VERSION "0.0.1"

NS_ :

BS_:

BU_: TCU BRK ESP MCU RDD GP TMS GW KPD1 RDE FNR ECU KPD2 ATSGO ACU IMU1 IMU2 IMU3 IMU4 IMU5 AGW PMI HDOQS EGOQS OBC EEC CBSW EJRH EJLH EPDLT EPDL2 EPDLR EPDLA TRBDZ ECU1 CLST LC510 EGDL JS SMB KPAC ACCU Audio TGU RDRR RDLH RDRH AVM CHMSL CTC SMK MC3D EVC MCU2

BO_ 2566904865 MCU_CETI: 10 MCU
 SG_ SalesRegion : 72|8@1+ (1,0) [0|255] "" Vector__XXX
 SG_ TcuType : 68|4@1+ (1,0) [0|15] "" Vector__XXX
 SG_ JoyType : 64|4@1+ (1,0) [0|15] "" Vector__XXX
 SG_ McvCtrlType : 60|4@1+ (1,0) [0|15] "" Vector__XXX
 SG_ McvType : 56|4@1+ (1,0) [0|15] "" Vector__XXX
 SG_ PmpCtrlType : 52|4@1+ (1,0) [0|15] "" Vector__XXX
 SG_ PmpType : 48|4@1+ (1,0) [0|15] "" Vector__XXX
 SG_ EcuMaker : 44|4@1+ (1,0) [0|15] "" Vector__XXX
 SG_ EgMaker : 40|4@1+ (1,0) [0|15] "" Vector__XXX
 SG_ ModelYearVer : 36|4@1+ (1,0) [0|15] "" Vector__XXX
 SG_ MchType : 32|4@1+ (1,0) [0|15] "" Vector__XXX
 SG_ MchClass : 16|16@1+ (0.1,0) [0|6502.3] "" Vector__XXX
 SG_ MchGen : 8|8@1+ (1,0) [0|255] "" Vector__XXX
 SG_ EmsCtrl : 0|8@1+ (1,0) [0|255] "" Vector__XXX

BO_ 2566905121 MCU_ASDI: 178 MCU
 SG_ TwUseFlow4 : 1408|16@1+ (1,0) [0|65535] "" Vector__XXX
 SG_ TwUseFlow3 : 1392|16@1+ (1,0) [0|65535] "" Vector__XXX
 SG_ TwUseFlow2 : 1376|16@1+ (1,0) [0|65535] "" Vector__XXX
 SG_ TwUseFlow1 : 1360|16@1+ (1,0) [0|65535] "" Vector__XXX
 SG_ TwUseFlow0 : 1344|16@1+ (1,0) [0|65535] "" Vector__XXX
 SG_ TwSetFlow4 : 1328|16@1+ (1,0) [0|65535] "" Vector__XXX
 SG_ TwSetFlow3 : 1312|16@1+ (1,0) [0|65535] "" Vector__XXX
 SG_ TwSetFlow2 : 1296|16@1+ (1,0) [0|65535] "" Vector__XXX
 SG_ TwSetFlow1 : 1280|16@1+ (1,0) [0|65535] "" Vector__XXX
 SG_ TwSetFlow0 : 1264|16@1+ (1,0) [0|65535] "" Vector__XXX
 SG_ TwMinFlowAtt4 : 1248|16@1+ (1,0) [0|65535] "" Vector__XXX
 SG_ TwMinFlowAtt3 : 1232|16@1+ (1,0) [0|65535] "" Vector__XXX
 SG_ TwMinFlowAtt2 : 1216|16@1+ (1,0) [0|65535] "" Vector__XXX
 SG_ TwMinFlowAtt1 : 1200|16@1+ (1,0) [0|65535] "" Vector__XXX
 SG_ TwMinFlowAtt0 : 1184|16@1+ (1,0) [0|65535] "" Vector__XXX
 SG_ TwMaxFlowAtt4 : 1168|16@1+ (1,0) [0|65535] "" Vector__XXX
 SG_ TwMaxFlowAtt3 : 1152|16@1+ (1,0) [0|65535] "" Vector__XXX
 SG_ TwMaxFlowAtt2 : 1136|16@1+ (1,0) [0|65535] "" Vector__XXX
 SG_ TwMaxFlowAtt1 : 1120|16@1+ (1,0) [0|65535] "" Vector__XXX
 SG_ TwMaxFlowAtt0 : 1104|16@1+ (1,0) [0|65535] "" Vector__XXX
 SG_ TwMaxFlowPmp4 : 1088|16@1+ (1,0) [0|65535] "" Vector__XXX
 SG_ TwMaxFlowPmp3 : 1072|16@1+ (1,0) [0|65535] "" Vector__XXX
 SG_ TwMaxFlowPmp2 : 1056|16@1+ (1,0) [0|65535] "" Vector__XXX
 SG_ TwMaxFlowPmp1 : 1040|16@1+ (1,0) [0|65535] "" Vector__XXX
 SG_ TwMaxFlowPmp0 : 1024|16@1+ (1,0) [0|65535] "" Vector__XXX
 SG_ TwPrs4 : 1008|16@1+ (1,0) [0|65535] "" Vector__XXX
 SG_ TwPrs3 : 992|16@1+ (1,0) [0|65535] "" Vector__XXX
 SG_ TwPrs2 : 976|16@1+ (1,0) [0|65535] "" Vector__XXX
 SG_ TwPrs1 : 960|16@1+ (1,0) [0|65535] "" Vector__XXX
 SG_ TwPrs0 : 944|16@1+ (1,0) [0|65535] "" Vector__XXX
 SG_ TwRpm4 : 928|16@1+ (1,0) [0|65535] "" Vector__XXX
 SG_ TwRpm3 : 912|16@1+ (1,0) [0|65535] "" Vector__XXX
 SG_ TwRpm2 : 896|16@1+ (1,0) [0|65535] "" Vector__XXX
 SG_ TwRpm1 : 880|16@1+ (1,0) [0|65535] "" Vector__XXX
 SG_ TwRpm0 : 864|16@1+ (1,0) [0|65535] "" Vector__XXX
 SG_ Tw4BrkrBtnType : 853|2@1+ (1,0) [0|3] "" Vector__XXX
 SG_ Tw4TwoPmpOpt : 852|1@1+ (1,0) [0|1] "" Vector__XXX
 SG_ Tw4SelAttNo : 849|3@1+ (1,0) [0|7] "" Vector__XXX
 SG_ Tw4SelAttType : 848|1@1+ (1,0) [0|1] "" Vector__XXX
 SG_ Tw3BrkrBtnType : 837|2@1+ (1,0) [0|3] "" Vector__XXX
 SG_ Tw3TwoPmpOpt : 836|1@1+ (1,0) [0|1] "" Vector__XXX
 SG_ Tw3SelAttNo : 833|3@1+ (1,0) [0|7] "" Vector__XXX
 SG_ Tw3SelAttType : 832|1@1+ (1,0) [0|1] "" Vector__XXX
 SG_ Tw2BrkrBtnType : 821|2@1+ (1,0) [0|3] "" Vector__XXX
 SG_ Tw2TwoPmpOpt : 820|1@1+ (1,0) [0|1] "" Vector__XXX
 SG_ Tw2SelAttNo : 817|3@1+ (1,0) [0|7] "" Vector__XXX
 SG_ Tw2SelAttType : 816|1@1+ (1,0) [0|1] "" Vector__XXX
 SG_ Tw1BrkrBtnType : 805|2@1+ (1,0) [0|3] "" Vector__XXX
 SG_ Tw1TwoPmpOpt : 804|1@1+ (1,0) [0|1] "" Vector__XXX
 SG_ Tw1SelAttNo : 801|3@1+ (1,0) [0|7] "" Vector__XXX
 SG_ Tw1SelAttType : 800|1@1+ (1,0) [0|1] "" Vector__XXX
 SG_ Tw0BrkrBtnType : 789|2@1+ (1,0) [0|3] "" Vector__XXX
 SG_ Tw0TwoPmpOpt : 788|1@1+ (1,0) [0|1] "" Vector__XXX
 SG_ Tw0SelAttNo : 785|3@1+ (1,0) [0|7] "" Vector__XXX
 SG_ Tw0SelAttType : 784|1@1+ (1,0) [0|1] "" Vector__XXX
 SG_ OwUseFlow4 : 768|16@1+ (1,0) [0|65535] "" Vector__XXX
 SG_ OwUseFlow3 : 752|16@1+ (1,0) [0|65535] "" Vector__XXX
 SG_ OwUseFlow2 : 736|16@1+ (1,0) [0|65535] "" Vector__XXX
 SG_ OwUseFlow1 : 720|16@1+ (1,0) [0|65535] "" Vector__XXX
 SG_ OwUseFlow0 : 704|16@1+ (1,0) [0|65535] "" Vector__XXX
 SG_ OwSetFlow4 : 688|16@1+ (1,0) [0|65535] "" Vector__XXX
 SG_ OwSetFlow3 : 672|16@1+ (1,0) [0|65535] "" Vector__XXX
 SG_ OwSetFlow2 : 656|16@1+ (1,0) [0|65535] "" Vector__XXX
 SG_ OwSetFlow1 : 640|16@1+ (1,0) [0|65535] "" Vector__XXX
 SG_ OwSetFlow0 : 624|16@1+ (1,0) [0|65535] "" Vector__XXX
 SG_ OwMinFlowAtt4 : 608|16@1+ (1,0) [0|65535] "" Vector__XXX
 SG_ OwMinFlowAtt3 : 592|16@1+ (1,0) [0|65535] "" Vector__XXX
 SG_ OwMinFlowAtt2 : 576|16@1+ (1,0) [0|65535] "" Vector__XXX
 SG_ OwMinFlowAtt1 : 560|16@1+ (1,0) [0|65535] "" Vector__XXX
 SG_ OwMinFlowAtt0 : 544|16@1+ (1,0) [0|65535] "" Vector__XXX
 SG_ OwMaxFlowAtt4 : 528|16@1+ (1,0) [0|65535] "" Vector__XXX
 SG_ OwMaxFlowAtt3 : 512|16@1+ (1,0) [0|65535] "" Vector__XXX
 SG_ OwMaxFlowAtt2 : 496|16@1+ (1,0) [0|65535] "" Vector__XXX
 SG_ OwMaxFlowAtt1 : 480|16@1+ (1,0) [0|65535] "" Vector__XXX
 SG_ OwMaxFlowAtt0 : 464|16@1+ (1,0) [0|65535] "" Vector__XXX
 SG_ OwMaxFlowPmp4 : 448|16@1+ (1,0) [0|65535] "" Vector__XXX
 SG_ OwMaxFlowPmp3 : 432|16@1+ (1,0) [0|65535] "" Vector__XXX
 SG_ OwMaxFlowPmp2 : 416|16@1+ (1,0) [0|65535] "" Vector__XXX
 SG_ OwMaxFlowPmp1 : 400|16@1+ (1,0) [0|65535] "" Vector__XXX
 SG_ OwMaxFlowPmp0 : 384|16@1+ (1,0) [0|65535] "" Vector__XXX
 SG_ OwPrs4 : 368|16@1+ (1,0) [0|65535] "" Vector__XXX
 SG_ OwPrs3 : 352|16@1+ (1,0) [0|65535] "" Vector__XXX
 SG_ OwPrs2 : 336|16@1+ (1,0) [0|65535] "" Vector__XXX
 SG_ OwPrs1 : 320|16@1+ (1,0) [0|65535] "" Vector__XXX
 SG_ OwPrs0 : 304|16@1+ (1,0) [0|65535] "" Vector__XXX
 SG_ OwRpm4 : 288|16@1+ (1,0) [0|65535] "" Vector__XXX
 SG_ OwRpm3 : 272|16@1+ (1,0) [0|65535] "" Vector__XXX
 SG_ OwRpm2 : 256|16@1+ (1,0) [0|65535] "" Vector__XXX
 SG_ OwRpm1 : 240|16@1+ (1,0) [0|65535] "" Vector__XXX
 SG_ OwRpm0 : 224|16@1+ (1,0) [0|65535] "" Vector__XXX
 SG_ RttCurStep : 220|4@1+ (1,0) [0|15] "" Vector__XXX
 SG_ TwCurStep : 216|4@1+ (1,0) [0|15] "" Vector__XXX
 SG_ Ow4BrkrBtnType : 213|2@1+ (1,0) [0|3] "" Vector__XXX
 SG_ Ow4TwoPmpOpt : 212|1@1+ (1,0) [0|1] "" Vector__XXX
 SG_ Ow4SelAttNo : 209|3@1+ (1,0) [0|7] "" Vector__XXX
 SG_ Ow4SelAttType : 208|1@1+ (1,0) [0|1] "" Vector__XXX
 SG_ OwCurStep : 200|4@1+ (1,0) [0|15] "" Vector__XXX
 SG_ Ow3BrkrBtnType : 197|2@1+ (1,0) [0|3] "" Vector__XXX
 SG_ Ow3TwoPmpOpt : 196|1@1+ (1,0) [0|1] "" Vector__XXX
 SG_ Ow3SelAttNo : 193|3@1+ (1,0) [0|7] "" Vector__XXX
 SG_ Ow3SelAttType : 192|1@1+ (1,0) [0|1] "" Vector__XXX
 SG_ Ow2BrkrBtnType : 181|2@1+ (1,0) [0|3] "" Vector__XXX
 SG_ Ow2TwoPmpOpt : 180|1@1+ (1,0) [0|1] "" Vector__XXX
 SG_ Ow2SelAttNo : 177|3@1+ (1,0) [0|7] "" Vector__XXX
 SG_ Ow2SelAttType : 176|1@1+ (1,0) [0|1] "" Vector__XXX
 SG_ Ow1BrkrBtnType : 165|2@1+ (1,0) [0|3] "" Vector__XXX
 SG_ Ow1TwoPmpOpt : 164|1@1+ (1,0) [0|1] "" Vector__XXX
 SG_ Ow1SelAttNo : 161|3@1+ (1,0) [0|7] "" Vector__XXX
 SG_ Ow1SelAttType : 160|1@1+ (1,0) [0|1] "" Vector__XXX
 SG_ Ow0BrkrBtnType : 149|2@1+ (1,0) [0|3] "" Vector__XXX
 SG_ Ow0TwoPmpOpt : 148|1@1+ (1,0) [0|1] "" Vector__XXX
 SG_ Ow0SelAttNo : 145|3@1+ (1,0) [0|7] "" Vector__XXX
 SG_ Ow0SelAttType : 144|1@1+ (1,0) [0|1] "" Vector__XXX
 SG_ MaxFlow : 128|16@1+ (1,0) [0|65535] "" Vector__XXX
 SG_ MinFlow : 112|16@1+ (1,0) [0|65535] "" Vector__XXX
 SG_ MaxPrsTw : 96|16@1+ (1,0) [0|65535] "" Vector__XXX
 SG_ MinPrsTw : 80|16@1+ (1,0) [0|65535] "" Vector__XXX
 SG_ MaxPrsOw : 64|16@1+ (1,0) [0|65535] "" Vector__XXX
 SG_ MinPrsOw : 48|16@1+ (1,0) [0|65535] "" Vector__XXX
 SG_ MaxSpd : 32|16@1+ (1,0) [0|65535] "" Vector__XXX
 SG_ MinSpd : 16|16@1+ (1,0) [0|65535] "" Vector__XXX
 SG_ SelAttTw : 3|3@1+ (1,0) [0|7] "" Vector__XXX
 SG_ SelAttOw : 0|3@1+ (1,0) [0|7] "" Vector__XXX

BO_ 2566905377 MCU_FUDI: 32 MCU
 SG_ TrvlStd : 224|32@1+ (1,0) [0|4294967295] "" Vector__XXX
 SG_ TrvlPow : 192|32@1+ (1,0) [0|4294967295] "" Vector__XXX
 SG_ Idle : 160|32@1+ (1,0) [0|4294967295] "" Vector__XXX
 SG_ AutoIdle : 128|32@1+ (1,0) [0|4294967295] "" Vector__XXX
 SG_ EcnMd : 96|32@1+ (1,0) [0|4294967295] "" Vector__XXX
 SG_ StdMd : 64|32@1+ (1,0) [0|4294967295] "" Vector__XXX
 SG_ PowMd : 32|32@1+ (1,0) [0|4294967295] "" Vector__XXX
 SG_ PowPlusMd : 0|32@1+ (1,0) [0|4294967295] "" Vector__XXX

BO_ 2566905633 MCU_UHDI: 96 MCU
 SG_ TotOprHr : 736|32@1+ (1,0) [0|4294967295] "" Vector__XXX
 SG_ Co0lTempAbove106 : 704|32@1+ (1,0) [0|4294967295] "" Vector__XXX
 SG_ Co0lTemp96105 : 672|32@1+ (1,0) [0|4294967295] "" Vector__XXX
 SG_ Co0lTemp96100 : 640|32@1+ (1,0) [0|4294967295] "" Vector__XXX
 SG_ Co0lTemp9195 : 608|32@1+ (1,0) [0|4294967295] "" Vector__XXX
 SG_ Co0lTemp8190 : 576|32@1+ (1,0) [0|4294967295] "" Vector__XXX
 SG_ Co0lTempBelow80 : 544|32@1+ (1,0) [0|4294967295] "" Vector__XXX
 SG_ HydOilTmpAbove96 : 512|32@1+ (1,0) [0|4294967295] "" Vector__XXX
 SG_ HydOilTmp9195 : 480|32@1+ (1,0) [0|4294967295] "" Vector__XXX
 SG_ HydOilTmp8190 : 448|32@1+ (1,0) [0|4294967295] "" Vector__XXX
 SG_ HydOilTmp7180 : 416|32@1+ (1,0) [0|4294967295] "" Vector__XXX
 SG_ HydOilTmp5170 : 384|32@1+ (1,0) [0|4294967295] "" Vector__XXX
 SG_ HydOilTmpBelow50 : 352|32@1+ (1,0) [0|4294967295] "" Vector__XXX
 SG_ TwMd : 320|32@1+ (1,0) [0|4294967295] "" Vector__XXX
 SG_ BrkrMd : 288|32@1+ (1,0) [0|4294967295] "" Vector__XXX
 SG_ LiftMd : 256|32@1+ (1,0) [0|4294967295] "" Vector__XXX
 SG_ TrvlStd : 224|32@1+ (1,0) [0|4294967295] "" Vector__XXX
 SG_ TrvlPow : 192|32@1+ (1,0) [0|4294967295] "" Vector__XXX
 SG_ Idle : 160|32@1+ (1,0) [0|4294967295] "" Vector__XXX
 SG_ AutoIdle : 128|32@1+ (1,0) [0|4294967295] "" Vector__XXX
 SG_ EcnMd : 96|32@1+ (1,0) [0|4294967295] "" Vector__XXX
 SG_ StdMd : 64|32@1+ (1,0) [0|4294967295] "" Vector__XXX
 SG_ PowMd : 32|32@1+ (1,0) [0|4294967295] "" Vector__XXX
 SG_ PowPlusMd : 0|32@1+ (1,0) [0|4294967295] "" Vector__XXX

BO_ 2566905889 MCU_RTFI: 14 MCU
 SG_ Afc7 : 96|16@1+ (1,0) [0|65535] "" Vector__XXX
 SG_ Afc6 : 80|16@1+ (1,0) [0|65535] "" Vector__XXX
 SG_ Afc5 : 64|16@1+ (1,0) [0|65535] "" Vector__XXX
 SG_ Afc4 : 48|16@1+ (1,0) [0|65535] "" Vector__XXX
 SG_ Afc3 : 32|16@1+ (1,0) [0|65535] "" Vector__XXX
 SG_ Afc2 : 16|16@1+ (1,0) [0|65535] "" Vector__XXX
 SG_ Afc1 : 0|16@1+ (1,0) [0|65535] "" Vector__XXX

BO_ 2566906145 MCU_FLI: 14 MCU
 SG_ Hfc2FirstOcrTm : 80|32@1+ (1,0) [0|4294967295] "" Vector__XXX
 SG_ Hfc2 : 64|16@1+ (1,0) [0|65535] "" Vector__XXX
 SG_ Hfc2Cnt : 56|8@1+ (1,0) [0|255] "" Vector__XXX
 SG_ Hfc1FirstOcrTm : 24|32@1+ (1,0) [0|4294967295] "" Vector__XXX
 SG_ Hfc1 : 8|16@1+ (1,0) [0|65535] "" Vector__XXX
 SG_ Hfc1Cnt : 0|8@1+ (1,0) [0|255] "" Vector__XXX

BO_ 2566906401 MCU_ARTFI: 250 MCU

BO_ 2566906657 MCU_TPUC: 250 MCU
 SG_ TmsPunlckCode : 0|32@1+ (1,0) [0|4294967295] "" Vector__XXX

BO_ 2566907169 MCU_VSWVER: 250 MCU
 SG_ McuSwVerYear : 48|8@1+ (1,1985) [1985|2235] "year" Vector__XXX
 SG_ McuSwVerDay : 40|8@1+ (0.25,0) [0|62.5] "days" Vector__XXX
 SG_ McuSwVerMonth : 32|8@1+ (1,0) [0|250] "month" Vector__XXX
 SG_ McuSwVer : 0|32@1+ (1,0) [0|255] "" Vector__XXX

BO_ 2566907681 MCU_ECOGI: 15 MCU
 SG_ IccoFunCrcmdScore : 112|8@1+ (1,0) [0|250] "" Vector__XXX
 SG_ UnssHydReliefScore : 104|8@1+ (1,0) [0|250] "" Vector__XXX
 SG_ InIntentBrkPreventScore : 96|8@1+ (1,0) [0|250] "" Vector__XXX
 SG_ EmgStpPreventScore : 88|8@1+ (1,0) [0|250] "" Vector__XXX
 SG_ EgMdDnRcmdScore : 80|8@1+ (1,0) [0|250] "" Vector__XXX
 SG_ LckUpRcmdScore : 72|8@1+ (1,0) [0|250] "" Vector__XXX
 SG_ GrNeutRpmUpScore : 64|8@1+ (1,0) [0|250] "" Vector__XXX
 SG_ IdlePrvtScore : 56|8@1+ (1,0) [0|250] "" Vector__XXX
 SG_ ManGrMaxSpdRcmdScore : 48|8@1+ (1,0) [0|250] "" Vector__XXX
 SG_ Auto14RcmdScore : 40|8@1+ (1,0) [0|250] "" Vector__XXX
 SG_ LisVhcSpdSetDnChngRcmdScore : 32|8@1+ (1,0) [0|250] "" Vector__XXX
 SG_ LisVhcSpdSetUpChngRcmdScore : 24|8@1+ (1,0) [0|250] "" Vector__XXX
 SG_ LisFunCrcmdScore : 16|8@1+ (1,0) [0|250] "" Vector__XXX
 SG_ IccoFunCrctm : 5|1@1+ (1,0) [0|1] "" Vector__XXX
 SG_ EgMdDnRctm : 4|1@1+ (1,0) [0|1] "" Vector__XXX
 SG_ LckUpRcmd : 3|1@1+ (1,0) [0|1] "" Vector__XXX
 SG_ IdlePrvtRcmd : 2|1@1+ (1,0) [0|1] "" Vector__XXX
 SG_ Auto14Rcmd : 1|1@1+ (1,0) [0|1] "" Vector__XXX
 SG_ LisRcmd : 0|1@1+ (1,0) [0|1] "" Vector__XXX

BO_ 2566907937 MCU_MCI: 250 MCU
 SG_ ElecStrJoyThmbWhlConf : 16|2@1+ (1,0) [0|3] "" Vector__XXX
 SG_ Dl06EgFuelEffCalbConf : 14|2@1+ (1,0) [0|3] "" Vector__XXX
 SG_ RttThmbWhlDirConf : 12|2@1+ (1,0) [0|3] "" Vector__XXX
 SG_ TwThmbWhlDirConf : 10|2@1+ (1,0) [0|3] "" Vector__XXX
 SG_ CanPdlIntChngConf : 8|2@1+ (1,0) [0|3] "" Vector__XXX
 SG_ TrvlSwgAlmIntChngConf : 6|2@1+ (1,0) [0|3] "" Vector__XXX
 SG_ OprHrTmpIntChngConf : 4|2@1+ (1,0) [0|3] "" Vector__XXX
 SG_ QckCouplerIntChngConf : 2|2@1+ (1,0) [0|3] "" Vector__XXX
 SG_ ThmbWhlSensConf : 1|1@1+ (1,0) [0|1] "" Vector__XXX
 SG_ MultiFuncJoyBtnConf : 0|1@1+ (1,0) [0|1] "" Vector__XXX

BO_ 2566908449 MCU_MWIG: 250 MCU
 SG_ AssitSwgRh : 46|2@1+ (1,0) [0|3] "" Vector__XXX
 SG_ AssitSwgLh : 44|2@1+ (1,0) [0|3] "" Vector__XXX
 SG_ AssitBck : 42|2@1+ (1,0) [0|3] "" Vector__XXX
 SG_ AssitGrd : 40|2@1+ (1,0) [0|3] "" Vector__XXX
 SG_ SafeWrkSideFar : 36|2@1+ (1,0) [0|3] "" Vector__XXX
 SG_ SafeWrkSideMid : 34|2@1+ (1,0) [0|3] "" Vector__XXX
 SG_ SafeWrkSideNear : 32|2@1+ (1,0) [0|3] "" Vector__XXX
 SG_ SafeWrkFrFar : 28|2@1+ (1,0) [0|3] "" Vector__XXX
 SG_ SafeWrkFrMid : 26|2@1+ (1,0) [0|3] "" Vector__XXX
 SG_ SafeWrkFrNear : 24|2@1+ (1,0) [0|3] "" Vector__XXX
 SG_ FrMvGuidArmOut : 22|2@1+ (1,0) [0|3] "" Vector__XXX
 SG_ FrMvGuidArmIn : 20|2@1+ (1,0) [0|3] "" Vector__XXX
 SG_ FrMvGuidBoomDn : 18|2@1+ (1,0) [0|3] "" Vector__XXX
 SG_ FrMvGuidBoomUp : 16|2@1+ (1,0) [0|3] "" Vector__XXX
 SG_ EfenceTrkWrn : 14|2@1+ (1,0) [0|3] "" Vector__XXX
 SG_ EfenceDzWrn : 12|2@1+ (1,0) [0|3] "" Vector__XXX
 SG_ EfenceCabWrn : 10|2@1+ (1,0) [0|3] "" Vector__XXX
 SG_ EfenceFSwgRhWrn : 8|2@1+ (1,0) [0|3] "" Vector__XXX
 SG_ EfenceFSwgLhWrn : 6|2@1+ (1,0) [0|3] "" Vector__XXX
 SG_ EfenceCeilWrn : 4|2@1+ (1,0) [0|3] "" Vector__XXX
 SG_ EfenceFloorWrn : 2|2@1+ (1,0) [0|3] "" Vector__XXX
 SG_ EfenceWallWrn : 0|2@1+ (1,0) [0|3] "" Vector__XXX

BO_ 2566908705 MCU_TWG: 250 MCU
 SG_ TotWhgCurTrk : 40|16@1+ (2,0) [0|128510] "kg" Vector__XXX
 SG_ BckCntCurTrk : 24|16@1+ (1,0) [0|65535] "count" Vector__XXX
 SG_ WghCntSt : 20|2@1+ (1,0) [0|3] "" Vector__XXX
 SG_ WghSt : 16|4@1+ (1,0) [0|15] "" Vector__XXX
 SG_ RelTmBckWhg : 0|16@1+ (2,0) [0|128510] "kg" Vector__XXX

BO_ 2566908961 MCU_WCPR: 250 MCU
 SG_ BckZeroCalbStep : 20|4@1+ (1,0) [0|15] "" Vector__XXX
 SG_ BckZeroCalbStage : 16|4@1+ (1,0) [0|15] "" Vector__XXX
 SG_ FrMultiCalbStep : 12|4@1+ (1,0) [0|15] "" Vector__XXX
 SG_ FrMultiCalbStage : 8|4@1+ (1,0) [0|15] "" Vector__XXX
 SG_ FrSngCalbStep : 4|4@1+ (1,0) [0|15] "" Vector__XXX
 SG_ FrSngCalbStage : 0|4@1+ (1,0) [0|15] "" Vector__XXX

BO_ 2566909217 MCU_WCCV: 250 MCU
 SG_ TgtArmCylSpdUpLmt : 40|8@1+ (0.1,0) [0|20] "mm/sec" Vector__XXX
 SG_ TgtArmCylSpdLwLmt : 32|8@1+ (0.1,0) [0|20] "mm/sec" Vector__XXX
 SG_ CurArmCylSpd : 24|8@1+ (0.1,0) [0|20] "mm/sec" Vector__XXX
 SG_ TgtBoomCylSpdUpLmt : 16|8@1+ (0.1,0) [0|20] "mm/sec" Vector__XXX
 SG_ TgtBoomCylSpdLwLmt : 8|8@1+ (0.1,0) [0|20] "mm/sec" Vector__XXX
 SG_ CurBoomCylSpd : 0|8@1+ (0.1,0) [0|20] "mm/sec" Vector__XXX

BO_ 2566909473 MCU_WCJA: 250 MCU
 SG_ TgtArmJointAngEndPos : 40|8@1+ (1,-125) [-125|125] "deg" Vector__XXX
 SG_ TgtArmJointAngStartPos : 32|8@1+ (1,-125) [-125|125] "deg" Vector__XXX
 SG_ CurArmJointAng : 24|8@1+ (1,-125) [-125|125] "deg" Vector__XXX
 SG_ TgtBoomJointAngEndPos : 16|8@1+ (1,-125) [-125|125] "deg" Vector__XXX
 SG_ TgtBoomJointAngStartPos : 8|8@1+ (1,-125) [-125|125] "deg" Vector__XXX
 SG_ CurBoomJointAng : 0|8@1+ (1,-125) [-125|125] "deg" Vector__XXX

BO_ 2566909729 MCU_LADG: 250 MCU
 SG_ Reach : 48|16@1+ (1,-32000) [-32000|32255] "mm" Vector__XXX
 SG_ Hight : 32|16@1+ (1,-32000) [-32000|32255] "mm" Vector__XXX
 SG_ RatedLoad : 16|16@1+ (2,0) [0|128510] "kg" Vector__XXX
 SG_ ActLoad : 0|16@1+ (2,0) [0|128510] "kg" Vector__XXX

BO_ 2634018819 TCU_TCUID: 8 TCU

BO_ 2566910241 MCU_ASRG: 250 MCU
 SG_ SwgAng : 0|24@1+ (3.0517578125E-005,-250) [-250|252] "deg" Vector__XXX

BO_ 2566910534 EVC_ETCCMVCU: 9 EVC

BO_ 2566912289 MCU_MWHG4: 138 MCU
 SG_ SsOfsRttAng : 1088|16@1+ (0.0078125,-200) [-200|301.99] "deg" Vector__XXX
 SG_ ImuSsOfsTrttTiltAng : 1072|16@1+ (0.0078125,-200) [-200|301.99] "deg" Vector__XXX
 SG_ TrttBodyDmsnTQ4 : 1056|16@1+ (1,0) [0|64255] "mm" Vector__XXX
 SG_ TrttBodyDmsnDQ4 : 1040|16@1+ (1,0) [0|64255] "mm" Vector__XXX
 SG_ TrttBodyDmsnAngGdt : 1016|24@1+ (3.0517578125E-005,-250) [-250|252] "deg" Vector__XXX
 SG_ TrttBodyDmsnDT : 1000|16@1+ (1,0) [0|64255] "mm" Vector__XXX
 SG_ TrttBodyDmsnGT : 984|16@1+ (1,0) [0|64255] "mm" Vector__XXX
 SG_ TrttBodyDmsnDG : 968|16@1+ (1,0) [0|64255] "mm" Vector__XXX
 SG_ TrttBodyDmsnVW : 952|16@1+ (1,0) [0|64255] "mm" Vector__XXX
 SG_ TrttBodyDmsnUV : 936|16@1+ (1,0) [0|64255] "mm" Vector__XXX
 SG_ TrttBodyDmsnTU : 920|16@1+ (1,0) [0|64255] "mm" Vector__XXX
 SG_ TrttBck05DmsnAngVwn : 896|24@1+ (3.0517578125E-005,-250) [-250|252] "deg" Vector__XXX
 SG_ TrttBck05DmsnTN : 880|16@1+ (1,0) [0|64255] "mm" Vector__XXX
 SG_ TrttBck05DmsnWN : 864|16@1+ (1,0) [0|64255] "mm" Vector__XXX
 SG_ TrttBck05DmsnWT : 848|16@1+ (1,0) [0|64255] "mm" Vector__XXX
 SG_ TrttBck05DmsnNQ3 : 832|16@1+ (1,0) [0|64255] "mm" Vector__XXX
 SG_ TrttBck05DmsnWQ3 : 816|16@1+ (1,0) [0|64255] "mm" Vector__XXX
 SG_ TrttBck05DmsnNQ2 : 800|16@1+ (1,0) [0|64255] "mm" Vector__XXX
 SG_ TrttBck05DmsnWQ2 : 784|16@1+ (1,0) [0|64255] "mm" Vector__XXX
 SG_ TrttBck05DmsnWidth : 768|16@1+ (1,0) [0|64255] "mm" Vector__XXX
 SG_ TrttBck05DmsnNQ1 : 752|16@1+ (1,0) [0|64255] "mm" Vector__XXX
 SG_ TrttBck05DmsnWQ1 : 736|16@1+ (1,0) [0|64255] "mm" Vector__XXX
 SG_ TrttBck04DmsnAngVwn : 712|24@1+ (3.0517578125E-005,-250) [-250|252] "deg" Vector__XXX
 SG_ TrttBck04DmsnTN : 696|16@1+ (1,0) [0|64255] "mm" Vector__XXX
 SG_ TrttBck04DmsnWN : 680|16@1+ (1,0) [0|64255] "mm" Vector__XXX
 SG_ TrttBck04DmsnWT : 664|16@1+ (1,0) [0|64255] "mm" Vector__XXX
 SG_ TrttBck04DmsnNQ3 : 648|16@1+ (1,0) [0|64255] "mm" Vector__XXX
 SG_ TrttBck04DmsnWQ3 : 632|16@1+ (1,0) [0|64255] "mm" Vector__XXX
 SG_ TrttBck04DmsnNQ2 : 616|16@1+ (1,0) [0|64255] "mm" Vector__XXX
 SG_ TrttBck04DmsnWQ2 : 600|16@1+ (1,0) [0|64255] "mm" Vector__XXX
 SG_ TrttBck04DmsnWidth : 584|16@1+ (1,0) [0|64255] "mm" Vector__XXX
 SG_ TrttBck04DmsnNQ1 : 568|16@1+ (1,0) [0|64255] "mm" Vector__XXX
 SG_ TrttBck04DmsnWQ1 : 552|16@1+ (1,0) [0|64255] "mm" Vector__XXX
 SG_ TrttBck03DmsnAngVwn : 528|24@1+ (3.0517578125E-005,-250) [-250|252] "deg" Vector__XXX
 SG_ TrttBck03DmsnTN : 512|16@1+ (1,0) [0|64255] "mm" Vector__XXX
 SG_ TrttBck03DmsnWN : 496|16@1+ (1,0) [0|64255] "mm" Vector__XXX
 SG_ TrttBck03DmsnWT : 480|16@1+ (1,0) [0|64255] "mm" Vector__XXX
 SG_ TrttBck03DmsnNQ3 : 464|16@1+ (1,0) [0|64255] "mm" Vector__XXX
 SG_ TrttBck03DmsnWQ3 : 448|16@1+ (1,0) [0|64255] "mm" Vector__XXX
 SG_ TrttBck03DmsnNQ2 : 432|16@1+ (1,0) [0|64255] "mm" Vector__XXX
 SG_ TrttBck03DmsnWQ2 : 416|16@1+ (1,0) [0|64255] "mm" Vector__XXX
 SG_ TrttBck03DmsnWidth : 400|16@1+ (1,0) [0|64255] "mm" Vector__XXX
 SG_ TrttBck03DmsnNQ1 : 384|16@1+ (1,0) [0|64255] "mm" Vector__XXX
 SG_ TrttBck03DmsnWQ1 : 368|16@1+ (1,0) [0|64255] "mm" Vector__XXX
 SG_ TrttBck02DmsnAngVwn : 344|24@1+ (3.0517578125E-005,-250) [-250|252] "deg" Vector__XXX
 SG_ TrttBck02DmsnTN : 328|16@1+ (1,0) [0|64255] "mm" Vector__XXX
 SG_ TrttBck02DmsnWN : 312|16@1+ (1,0) [0|64255] "mm" Vector__XXX
 SG_ TrttBck02DmsnWT : 296|16@1+ (1,0) [0|64255] "mm" Vector__XXX
 SG_ TrttBck02DmsnNQ3 : 280|16@1+ (1,0) [0|64255] "mm" Vector__XXX
 SG_ TrttBck02DmsnWQ3 : 264|16@1+ (1,0) [0|64255] "mm" Vector__XXX
 SG_ TrttBck02DmsnNQ2 : 248|16@1+ (1,0) [0|64255] "mm" Vector__XXX
 SG_ TrttBck02DmsnWQ2 : 232|16@1+ (1,0) [0|64255] "mm" Vector__XXX
 SG_ TrttBck02DmsnWidth : 216|16@1+ (1,0) [0|64255] "mm" Vector__XXX
 SG_ TrttBck02DmsnNQ1 : 200|16@1+ (1,0) [0|64255] "mm" Vector__XXX
 SG_ TrttBck02DmsnWQ1 : 184|16@1+ (1,0) [0|64255] "mm" Vector__XXX
 SG_ TrttBck01DmsnAngVwn : 160|24@1+ (3.0517578125E-005,-250) [-250|252] "deg" Vector__XXX
 SG_ TrttBck01DmsnTN : 144|16@1+ (1,0) [0|64255] "mm" Vector__XXX
 SG_ TrttBck01DmsnWN : 128|16@1+ (1,0) [0|64255] "mm" Vector__XXX
 SG_ TrttBck01DmsnWT : 112|16@1+ (1,0) [0|64255] "mm" Vector__XXX
 SG_ TrttBck01DmsnNQ3 : 96|16@1+ (1,0) [0|64255] "mm" Vector__XXX
 SG_ TrttBck01DmsnWQ3 : 80|16@1+ (1,0) [0|64255] "mm" Vector__XXX
 SG_ TrttBck01DmsnNQ2 : 64|16@1+ (1,0) [0|64255] "mm" Vector__XXX
 SG_ TrttBck01DmsnWQ2 : 48|16@1+ (1,0) [0|64255] "mm" Vector__XXX
 SG_ TrttBck01DmsnWidth : 32|16@1+ (1,0) [0|64255] "mm" Vector__XXX
 SG_ TrttBck01DmsnNQ1 : 16|16@1+ (1,0) [0|64255] "mm" Vector__XXX
 SG_ TrttBck01DmsnWQ1 : 0|16@1+ (1,0) [0|64255] "mm" Vector__XXX

BO_ 2566912545 MCU_MWHG1: 125 MCU
 SG_ Bck05DmsnAngGdn : 976|24@1+ (3.0517578125E-005,-250) [-250|252] "deg" Vector__XXX
 SG_ Bck05DmsnDT : 960|16@1+ (1,0) [0|64255] "mm" Vector__XXX
 SG_ Bck05DmsnNQ3 : 944|16@1+ (1,0) [0|64255] "mm" Vector__XXX
 SG_ Bck05DmsnDQ3 : 928|16@1+ (1,0) [0|64255] "mm" Vector__XXX
 SG_ Bck05DmsnNQ2 : 912|16@1+ (1,0) [0|64255] "mm" Vector__XXX
 SG_ Bck05DmsnDQ2 : 896|16@1+ (1,0) [0|64255] "mm" Vector__XXX
 SG_ Bck05DmsnTN : 880|16@1+ (1,0) [0|64255] "mm" Vector__XXX
 SG_ Bck05DmsnWidth : 864|16@1+ (1,0) [0|64255] "mm" Vector__XXX
 SG_ Bck05DmsnNQ1 : 848|16@1+ (1,0) [0|64255] "mm" Vector__XXX
 SG_ Bck05DmsnDQ1 : 832|16@1+ (1,0) [0|64255] "mm" Vector__XXX
 SG_ Bck05DmsnDN : 816|16@1+ (1,0) [0|64255] "mm" Vector__XXX
 SG_ Bck05DmsnDG : 800|16@1+ (1,0) [0|64255] "mm" Vector__XXX
 SG_ Bck04DmsnAngGdn : 776|24@1+ (3.0517578125E-005,-250) [-250|252] "deg" Vector__XXX
 SG_ Bck04DmsnDT : 760|16@1+ (1,0) [0|64255] "mm" Vector__XXX
 SG_ Bck04DmsnNQ3 : 744|16@1+ (1,0) [0|64255] "mm" Vector__XXX
 SG_ Bck04DmsnDQ3 : 728|16@1+ (1,0) [0|64255] "mm" Vector__XXX
 SG_ Bck04DmsnNQ2 : 712|16@1+ (1,0) [0|64255] "mm" Vector__XXX
 SG_ Bck04DmsnDQ2 : 696|16@1+ (1,0) [0|64255] "mm" Vector__XXX
 SG_ Bck04DmsnTN : 680|16@1+ (1,0) [0|64255] "mm" Vector__XXX
 SG_ Bck04DmsnWidth : 664|16@1+ (1,0) [0|64255] "mm" Vector__XXX
 SG_ Bck04DmsnNQ1 : 648|16@1+ (1,0) [0|64255] "mm" Vector__XXX
 SG_ Bck04DmsnDQ1 : 632|16@1+ (1,0) [0|64255] "mm" Vector__XXX
 SG_ Bck04DmsnDN : 616|16@1+ (1,0) [0|64255] "mm" Vector__XXX
 SG_ Bck04DmsnDG : 600|16@1+ (1,0) [0|64255] "mm" Vector__XXX
 SG_ Bck03DmsnAngGdn : 576|24@1+ (3.0517578125E-005,-250) [-250|252] "deg" Vector__XXX
 SG_ Bck03DmsnDT : 560|16@1+ (1,0) [0|64255] "mm" Vector__XXX
 SG_ Bck03DmsnNQ3 : 544|16@1+ (1,0) [0|64255] "mm" Vector__XXX
 SG_ Bck03DmsnDQ3 : 528|16@1+ (1,0) [0|64255] "mm" Vector__XXX
 SG_ Bck03DmsnNQ2 : 512|16@1+ (1,0) [0|64255] "mm" Vector__XXX
 SG_ Bck03DmsnDQ2 : 496|16@1+ (1,0) [0|64255] "mm" Vector__XXX
 SG_ Bck03DmsnTN : 480|16@1+ (1,0) [0|64255] "mm" Vector__XXX
 SG_ Bck03DmsnWidth : 464|16@1+ (1,0) [0|64255] "mm" Vector__XXX
 SG_ Bck03DmsnNQ1 : 448|16@1+ (1,0) [0|64255] "mm" Vector__XXX
 SG_ Bck03DmsnDQ1 : 432|16@1+ (1,0) [0|64255] "mm" Vector__XXX
 SG_ Bck03DmsnDN : 416|16@1+ (1,0) [0|64255] "mm" Vector__XXX
 SG_ Bck03DmsnDG : 400|16@1+ (1,0) [0|64255] "mm" Vector__XXX
 SG_ Bck02DmsnAngGdn : 376|24@1+ (3.0517578125E-005,-250) [-250|252] "deg" Vector__XXX
 SG_ Bck02DmsnDT : 360|16@1+ (1,0) [0|64255] "mm" Vector__XXX
 SG_ Bck02DmsnNQ3 : 344|16@1+ (1,0) [0|64255] "mm" Vector__XXX
 SG_ Bck02DmsnDQ3 : 328|16@1+ (1,0) [0|64255] "mm" Vector__XXX
 SG_ Bck02DmsnNQ2 : 312|16@1+ (1,0) [0|64255] "mm" Vector__XXX
 SG_ Bck02DmsnDQ2 : 296|16@1+ (1,0) [0|64255] "mm" Vector__XXX
 SG_ Bck02DmsnTN : 280|16@1+ (1,0) [0|64255] "mm" Vector__XXX
 SG_ Bck02DmsnWidth : 264|16@1+ (1,0) [0|64255] "mm" Vector__XXX
 SG_ Bck02DmsnNQ1 : 248|16@1+ (1,0) [0|64255] "mm" Vector__XXX
 SG_ Bck02DmsnDQ1 : 232|16@1+ (1,0) [0|64255] "mm" Vector__XXX
 SG_ Bck02DmsnDN : 216|16@1+ (1,0) [0|64255] "mm" Vector__XXX
 SG_ Bck02DmsnDG : 200|16@1+ (1,0) [0|64255] "mm" Vector__XXX
 SG_ Bck01DmsnAngGdn : 176|24@1+ (3.0517578125E-005,-250) [-250|252] "deg" Vector__XXX
 SG_ Bck01DmsnDT : 160|16@1+ (1,0) [0|64255] "mm" Vector__XXX
 SG_ Bck01DmsnNQ3 : 144|16@1+ (1,0) [0|64255] "mm" Vector__XXX
 SG_ Bck01DmsnDQ3 : 128|16@1+ (1,0) [0|64255] "mm" Vector__XXX
 SG_ Bck01DmsnNQ2 : 112|16@1+ (1,0) [0|64255] "mm" Vector__XXX
 SG_ Bck01DmsnDQ2 : 96|16@1+ (1,0) [0|64255] "mm" Vector__XXX
 SG_ Bck01DmsnTN : 80|16@1+ (1,0) [0|64255] "mm" Vector__XXX
 SG_ Bck01DmsnWidth : 64|16@1+ (1,0) [0|64255] "mm" Vector__XXX
 SG_ Bck01DmsnNQ1 : 48|16@1+ (1,0) [0|64255] "mm" Vector__XXX
 SG_ Bck01DmsnDQ1 : 32|16@1+ (1,0) [0|64255] "mm" Vector__XXX
 SG_ Bck01DmsnDN : 16|16@1+ (1,0) [0|64255] "mm" Vector__XXX
 SG_ Bck01DmsnDG : 0|16@1+ (1,0) [0|64255] "mm" Vector__XXX

BO_ 2566912801 MCU_MWHG2: 110 MCU
 SG_ DacCoordinateSystem : 874|2@1+ (1,0) [0|3] "" Vector__XXX
 SG_ DacAutoMdSelect : 872|2@1+ (1,0) [0|3] "" Vector__XXX
 SG_ CrwTipCalbLen : 856|16@1+ (1,0) [0|64255] "mm" Vector__XXX
 SG_ ImuSsOfsBladeRoll : 832|24@1+ (3.0517578125E-005,-250) [-250|252] "deg" Vector__XXX
 SG_ ImuSsOfsBladePch : 808|24@1+ (3.0517578125E-005,-250) [-250|252] "deg" Vector__XXX
 SG_ ImuSsOfsCfrmRoll : 784|24@1+ (3.0517578125E-005,-250) [-250|252] "deg" Vector__XXX
 SG_ ImuSsOfsCfrmPch : 760|24@1+ (3.0517578125E-005,-250) [-250|252] "deg" Vector__XXX
 SG_ BladeTipCalbLen : 744|16@1+ (1,0) [0|64255] "mm" Vector__XXX
 SG_ BladeJointCalbLen : 728|16@1+ (1,0) [0|64255] "mm" Vector__XXX
 SG_ GrdAstPrfDsnDt01PntZ09 : 712|16@1+ (1,-32000) [-32000|32255] "mm" Vector__XXX
 SG_ GrdAstPrfDsnDt01PntY09 : 696|16@1+ (1,-32000) [-32000|32255] "mm" Vector__XXX
 SG_ GrdAstPrfDsnDt01PntZ08 : 680|16@1+ (1,-32000) [-32000|32255] "mm" Vector__XXX
 SG_ GrdAstPrfDsnDt01PntY08 : 664|16@1+ (1,-32000) [-32000|32255] "mm" Vector__XXX
 SG_ GrdAstPrfDsnDt01PntZ07 : 648|16@1+ (1,-32000) [-32000|32255] "mm" Vector__XXX
 SG_ GrdAstPrfDsnDt01PntY07 : 632|16@1+ (1,-32000) [-32000|32255] "mm" Vector__XXX
 SG_ GrdAstPrfDsnDt01PntZ06 : 616|16@1+ (1,-32000) [-32000|32255] "mm" Vector__XXX
 SG_ GrdAstPrfDsnDt01PntY06 : 600|16@1+ (1,-32000) [-32000|32255] "mm" Vector__XXX
 SG_ GrdAstPrfDsnDt01PntZ05 : 584|16@1+ (1,-32000) [-32000|32255] "mm" Vector__XXX
 SG_ GrdAstPrfDsnDt01PntY05 : 568|16@1+ (1,-32000) [-32000|32255] "mm" Vector__XXX
 SG_ GrdAstPrfDsnDt01PntZ04 : 552|16@1+ (1,-32000) [-32000|32255] "mm" Vector__XXX
 SG_ GrdAstPrfDsnDt01PntY04 : 536|16@1+ (1,-32000) [-32000|32255] "mm" Vector__XXX
 SG_ GrdAstPrfDsnDt01PntZ03 : 520|16@1+ (1,-32000) [-32000|32255] "mm" Vector__XXX
 SG_ GrdAstPrfDsnDt01PntY03 : 504|16@1+ (1,-32000) [-32000|32255] "mm" Vector__XXX
 SG_ GrdAstPrfDsnDt01PntZ02 : 488|16@1+ (1,-32000) [-32000|32255] "mm" Vector__XXX
 SG_ GrdAstPrfDsnDt01PntY02 : 472|16@1+ (1,-32000) [-32000|32255] "mm" Vector__XXX
 SG_ GrdAstPrfDsnDt01PntZ01 : 456|16@1+ (1,-32000) [-32000|32255] "mm" Vector__XXX
 SG_ GrdAstPrfDsnDt01PntY01 : 440|16@1+ (1,-32000) [-32000|32255] "mm" Vector__XXX
 SG_ CrossSlopeDsnDt : 424|16@1+ (0.0078125,-251) [-251|250.99] "%" Vector__XXX
 SG_ SlopeDsnDt : 408|16@1+ (0.0078125,-251) [-251|250.99] "%" Vector__XXX
 SG_ DepthDsnDt : 392|16@1+ (1,0) [0|64255] "mm" Vector__XXX
 SG_ JoyFuncAssnRhThmbWhl05 : 384|8@1+ (1,0) [0|255] "" Vector__XXX
 SG_ JoyFuncAssnRhThmbWhl04 : 376|8@1+ (1,0) [0|255] "" Vector__XXX
 SG_ JoyFuncAssnRhThmbWhl03 : 368|8@1+ (1,0) [0|255] "" Vector__XXX
 SG_ JoyFuncAssnRhThmbWhl02 : 360|8@1+ (1,0) [0|255] "" Vector__XXX
 SG_ JoyFuncAssnRhThmbWhl01 : 352|8@1+ (1,0) [0|255] "" Vector__XXX
 SG_ JoyFuncAssnLhThmbWhl05 : 344|8@1+ (1,0) [0|255] "" Vector__XXX
 SG_ JoyFuncAssnLhThmbWhl04 : 336|8@1+ (1,0) [0|255] "" Vector__XXX
 SG_ JoyFuncAssnLhThmbWhl03 : 328|8@1+ (1,0) [0|255] "" Vector__XXX
 SG_ JoyFuncAssnLhThmbWhl02 : 320|8@1+ (1,0) [0|255] "" Vector__XXX
 SG_ JoyFuncAssnLhThmbWhl01 : 312|8@1+ (1,0) [0|255] "" Vector__XXX
 SG_ JoyFuncAssnRhBtn10 : 304|8@1+ (1,0) [0|255] "" Vector__XXX
 SG_ JoyFuncAssnRhBtn09 : 296|8@1+ (1,0) [0|255] "" Vector__XXX
 SG_ JoyFuncAssnRhBtn08 : 288|8@1+ (1,0) [0|255] "" Vector__XXX
 SG_ JoyFuncAssnRhBtn07 : 280|8@1+ (1,0) [0|255] "" Vector__XXX
 SG_ JoyFuncAssnRhBtn06 : 272|8@1+ (1,0) [0|255] "" Vector__XXX
 SG_ JoyFuncAssnRhBtn05 : 264|8@1+ (1,0) [0|255] "" Vector__XXX
 SG_ JoyFuncAssnRhBtn04 : 256|8@1+ (1,0) [0|255] "" Vector__XXX
 SG_ JoyFuncAssnRhBtn03 : 248|8@1+ (1,0) [0|255] "" Vector__XXX
 SG_ JoyFuncAssnRhBtn02 : 240|8@1+ (1,0) [0|255] "" Vector__XXX
 SG_ JoyFuncAssnRhBtn01 : 232|8@1+ (1,0) [0|255] "" Vector__XXX
 SG_ JoyFuncAssnLhBtn10 : 224|8@1+ (1,0) [0|255] "" Vector__XXX
 SG_ JoyFuncAssnLhBtn09 : 216|8@1+ (1,0) [0|255] "" Vector__XXX
 SG_ JoyFuncAssnLhBtn08 : 208|8@1+ (1,0) [0|255] "" Vector__XXX
 SG_ JoyFuncAssnLhBtn07 : 200|8@1+ (1,0) [0|255] "" Vector__XXX
 SG_ JoyFuncAssnLhBtn06 : 192|8@1+ (1,0) [0|255] "" Vector__XXX
 SG_ JoyFuncAssnLhBtn05 : 184|8@1+ (1,0) [0|255] "" Vector__XXX
 SG_ JoyFuncAssnLhBtn04 : 176|8@1+ (1,0) [0|255] "" Vector__XXX
 SG_ JoyFuncAssnLhBtn03 : 168|8@1+ (1,0) [0|255] "" Vector__XXX
 SG_ JoyFuncAssnLhBtn02 : 160|8@1+ (1,0) [0|255] "" Vector__XXX
 SG_ JoyFuncAssnLhBtn01 : 152|8@1+ (1,0) [0|255] "" Vector__XXX
 SG_ ImuSsOfsBucket : 128|24@1+ (3.0517578125E-005,-250) [-250|252] "deg" Vector__XXX
 SG_ ImuSsOfsArtiArmPch : 104|24@1+ (3.0517578125E-005,-250) [-250|252] "deg" Vector__XXX
 SG_ ImuSsOfsArmPch : 80|24@1+ (3.0517578125E-005,-250) [-250|252] "deg" Vector__XXX
 SG_ ImuSsOfsBoomPch : 56|24@1+ (3.0517578125E-005,-250) [-250|252] "deg" Vector__XXX
 SG_ ImuSsOfsBodyRoll : 32|24@1+ (3.0517578125E-005,-250) [-250|252] "deg" Vector__XXX
 SG_ ImuSsOfsBodyPch : 8|24@1+ (3.0517578125E-005,-250) [-250|252] "deg" Vector__XXX
 SG_ SelectedBucketNo : 0|8@1+ (1,0) [0|255] "" Vector__XXX

BO_ 2566913057 MCU_MWHG3: 67 MCU
 SG_ MaterialName : 336|200@1+ (1,0) [0|255] "" Vector__XXX
 SG_ TrkName : 136|200@1+ (1,0) [0|255] "" Vector__XXX
 SG_ BchmkZOfs : 120|16@1+ (1,-32000) [-32000|32255] "mm" Vector__XXX
 SG_ BchmkYOfs : 104|16@1+ (1,-32000) [-32000|32255] "mm" Vector__XXX
 SG_ BchmkXOfs : 88|16@1+ (1,-32000) [-32000|32255] "mm" Vector__XXX
 SG_ TrkCount : 72|16@1+ (1,0) [0|64255] "" Vector__XXX
 SG_ SelMaterialDensity : 56|16@1+ (1,0) [0|64255] "kg/?" Vector__XXX
 SG_ SelTrkTgtWgh : 40|16@1+ (2,0) [0|128510] "kg" Vector__XXX
 SG_ BckRefPnt : 38|2@1+ (1,0) [0|3] "" Vector__XXX
 SG_ ArtiBoomDmsnOpt : 35|3@1+ (1,0) [0|7] "" Vector__XXX
 SG_ ArmDmsnOpt : 32|3@1+ (1,0) [0|7] "" Vector__XXX
 SG_ BoomDmsnOpt : 27|3@1+ (1,0) [0|7] "" Vector__XXX
 SG_ GrdAstMd : 20|4@1+ (1,0) [0|15] "" Vector__XXX
 SG_ GrdAstAccuracy : 16|4@1+ (1,0) [0|15] "" Vector__XXX
 SG_ TrkShoeWidth : 8|8@1+ (10,0) [0|2500] "mm" Vector__XXX

BO_ 2566913313 MCU_MWTSV: 18 MCU
 SG_ SwgAstAngTgtSetSwgLh : 120|24@1+ (3.0517578125E-005,-250) [-250|252] "deg" Vector__XXX
 SG_ SwgAstAngTgtSetSwgRh : 96|24@1+ (3.0517578125E-005,-250) [-250|252] "deg" Vector__XXX
 SG_ EfenceTgtSetSwgRh : 72|24@1+ (3.0517578125E-005,-250) [-250|252] "deg" Vector__XXX
 SG_ EfenceTgtSetSwgLh : 48|24@1+ (3.0517578125E-005,-250) [-250|252] "deg" Vector__XXX
 SG_ EfenceTgtSetCeil : 32|16@1+ (1,-32000) [-32000|32255] "mm" Vector__XXX
 SG_ EfenceTgtSetFloor : 16|16@1+ (1,-32000) [-32000|32255] "mm" Vector__XXX
 SG_ EfenceTgtSetWall : 0|16@1+ (1,-32000) [-32000|32255] "mm" Vector__XXX

BO_ 2566913569 MCU_MTSI: 57 MCU
 SG_ MaterialLoadSt : 448|1@1+ (1,0) [0|1] "" Vector__XXX
 SG_ TotWghCurtrk : 432|16@1+ (2,0) [0|128510] "kg" Vector__XXX
 SG_ BckCntCurtrk : 416|16@1+ (1,0) [0|65535] "count" Vector__XXX
 SG_ SelMaterialDensity : 400|16@1+ (1,0) [0|64255] "kg/?" Vector__XXX
 SG_ MaterialName : 200|200@1+ (1,0) [0|255] "" Vector__XXX
 SG_ TrkName : 0|200@1+ (1,0) [0|255] "" Vector__XXX

BO_ 2566913825 MCU_MAWI: 250 MCU
 SG_ TotAcmtWgh : 32|32@1+ (2,0) [0|8589934590] "kg" Vector__XXX
 SG_ TotAcmtBckCnt : 0|24@1+ (1,0) [0|16777215] "count" Vector__XXX

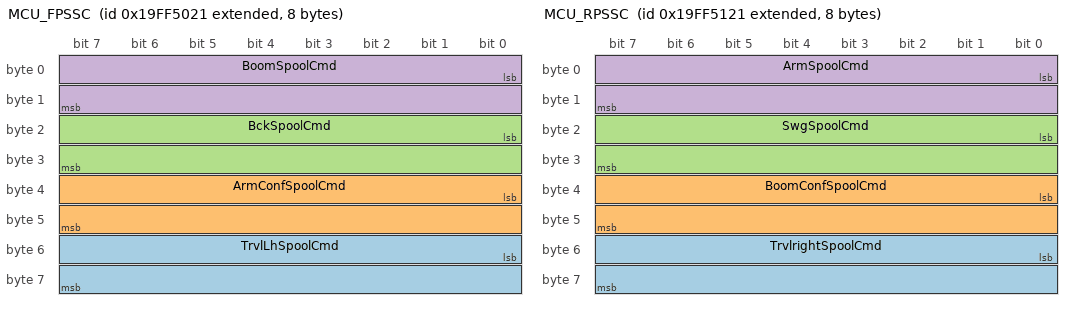
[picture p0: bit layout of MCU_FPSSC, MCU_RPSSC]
BO_ 2583646241 MCU_FPSSC: 8 MCU
 SG_ TrvlLhSpoolCmd : 48|16@1+ (0.01,-20) [-20|20] "mm" Vector__XXX
 SG_ ArmConfSpoolCmd : 32|16@1+ (0.01,-20) [-20|20] "mm" Vector__XXX
 SG_ BckSpoolCmd : 16|16@1+ (0.01,-20) [-20|20] "mm" Vector__XXX
 SG_ BoomSpoolCmd : 0|16@1+ (0.01,-20) [-20|20] "mm" Vector__XXX

BO_ 2583646497 MCU_RPSSC: 8 MCU
 SG_ TrvlrightSpoolCmd : 48|16@1+ (0.01,-20) [-20|20] "mm" Vector__XXX
 SG_ BoomConfSpoolCmd : 32|16@1+ (0.01,-20) [-20|20] "mm" Vector__XXX
 SG_ SwgSpoolCmd : 16|16@1+ (0.01,-20) [-20|20] "mm" Vector__XXX
 SG_ ArmSpoolCmd : 0|16@1+ (0.01,-20) [-20|20] "mm" Vector__XXX

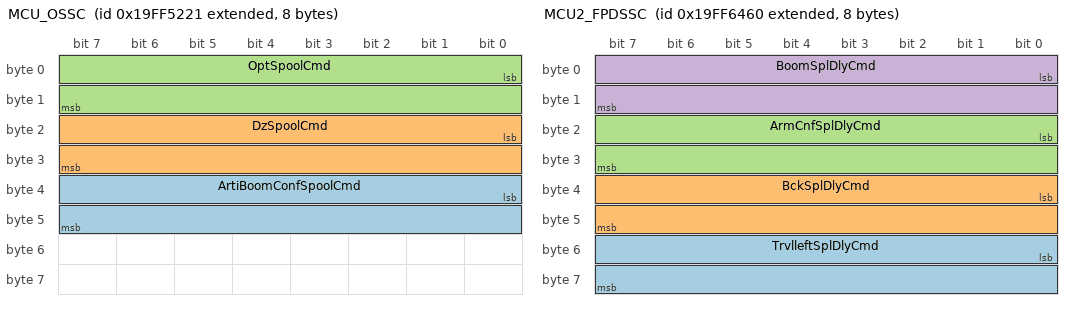
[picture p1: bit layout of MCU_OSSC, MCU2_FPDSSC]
BO_ 2583646753 MCU_OSSC: 8 MCU
 SG_ ArtiBoomConfSpoolCmd : 32|16@1+ (0.01,-20) [-20|20] "mm" Vector__XXX
 SG_ DzSpoolCmd : 16|16@1+ (0.01,-20) [-20|20] "mm" Vector__XXX
 SG_ OptSpoolCmd : 0|16@1+ (0.01,-20) [-20|20] "mm" Vector__XXX

BO_ 2583651424 MCU2_FPDSSC: 8 MCU2
 SG_ TrvlleftSplDlyCmd : 48|16@1+ (0.01,-20) [-20|20] "mm" Vector__XXX
 SG_ BckSplDlyCmd : 32|16@1+ (0.01,-20) [-20|20] "mm" Vector__XXX
 SG_ ArmCnfSplDlyCmd : 16|16@1+ (0.01,-20) [-20|20] "mm" Vector__XXX
 SG_ BoomSplDlyCmd : 0|16@1+ (0.01,-20) [-20|20] "mm" Vector__XXX

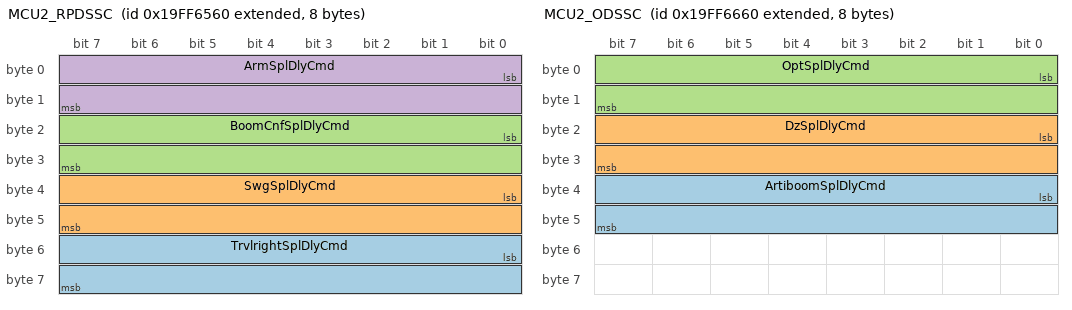
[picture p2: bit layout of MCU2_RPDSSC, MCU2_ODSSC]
BO_ 2583651680 MCU2_RPDSSC: 8 MCU2
 SG_ TrvlrightSplDlyCmd : 48|16@1+ (0.01,-20) [-20|20] "mm" Vector__XXX
 SG_ SwgSplDlyCmd : 32|16@1+ (0.01,-20) [-20|20] "mm" Vector__XXX
 SG_ BoomCnfSplDlyCmd : 16|16@1+ (0.01,-20) [-20|20] "mm" Vector__XXX
 SG_ ArmSplDlyCmd : 0|16@1+ (0.01,-20) [-20|20] "mm" Vector__XXX

BO_ 2583651936 MCU2_ODSSC: 8 MCU2
 SG_ ArtiboomSplDlyCmd : 32|16@1+ (0.01,-20) [-20|20] "mm" Vector__XXX
 SG_ DzSplDlyCmd : 16|16@1+ (0.01,-20) [-20|20] "mm" Vector__XXX
 SG_ OptSplDlyCmd : 0|16@1+ (0.01,-20) [-20|20] "mm" Vector__XXX

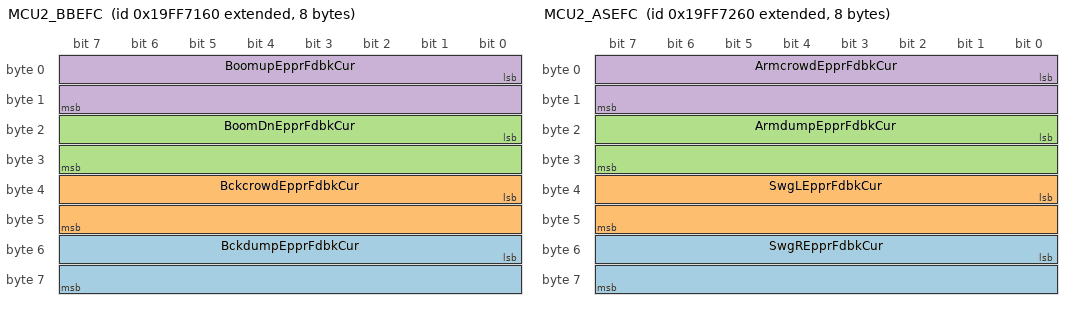
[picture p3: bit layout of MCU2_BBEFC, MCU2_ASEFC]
BO_ 2583654752 MCU2_BBEFC: 8 MCU2
 SG_ BckdumpEpprFdbkCur : 48|16@1+ (1,0) [0|1000] "mA" Vector__XXX
 SG_ BckcrowdEpprFdbkCur : 32|16@1+ (1,0) [0|1000] "mA" Vector__XXX
 SG_ BoomDnEpprFdbkCur : 16|16@1+ (1,0) [0|1000] "mA" Vector__XXX
 SG_ BoomupEpprFdbkCur : 0|16@1+ (1,0) [0|1000] "mA" Vector__XXX

BO_ 2583655008 MCU2_ASEFC: 8 MCU2
 SG_ SwgREpprFdbkCur : 48|16@1+ (1,0) [0|1000] "mA" Vector__XXX
 SG_ SwgLEpprFdbkCur : 32|16@1+ (1,0) [0|1000] "mA" Vector__XXX
 SG_ ArmdumpEpprFdbkCur : 16|16@1+ (1,0) [0|1000] "mA" Vector__XXX
 SG_ ArmcrowdEpprFdbkCur : 0|16@1+ (1,0) [0|1000] "mA" Vector__XXX

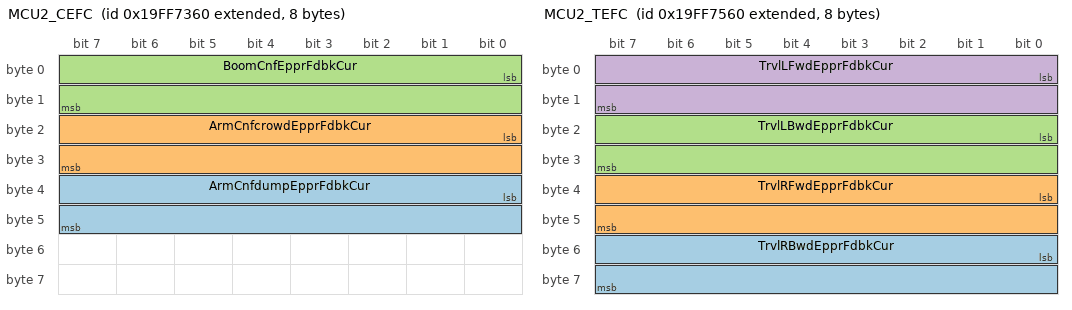
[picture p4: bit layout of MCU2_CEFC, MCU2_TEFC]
BO_ 2583655264 MCU2_CEFC: 8 MCU2
 SG_ ArmCnfdumpEpprFdbkCur : 32|16@1+ (1,0) [0|1000] "mA" Vector__XXX
 SG_ ArmCnfcrowdEpprFdbkCur : 16|16@1+ (1,0) [0|1000] "mA" Vector__XXX
 SG_ BoomCnfEpprFdbkCur : 0|16@1+ (1,0) [0|1000] "mA" Vector__XXX

BO_ 2583655520 MCU2_OEFC: 8 MCU2
 SG_ OpenEpprFdbkCur : 16|16@1+ (1,0) [0|1000] "mA" Vector__XXX
 SG_ CloseEpprFdbkCur : 0|16@1+ (1,0) [0|1000] "mA" Vector__XXX

BO_ 2583655776 MCU2_TEFC: 8 MCU2
 SG_ TrvlRBwdEpprFdbkCur : 48|16@1+ (1,0) [0|1000] "mA" Vector__XXX
 SG_ TrvlRFwdEpprFdbkCur : 32|16@1+ (1,0) [0|1000] "mA" Vector__XXX
 SG_ TrvlLBwdEpprFdbkCur : 16|16@1+ (1,0) [0|1000] "mA" Vector__XXX
 SG_ TrvlLFwdEpprFdbkCur : 0|16@1+ (1,0) [0|1000] "mA" Vector__XXX

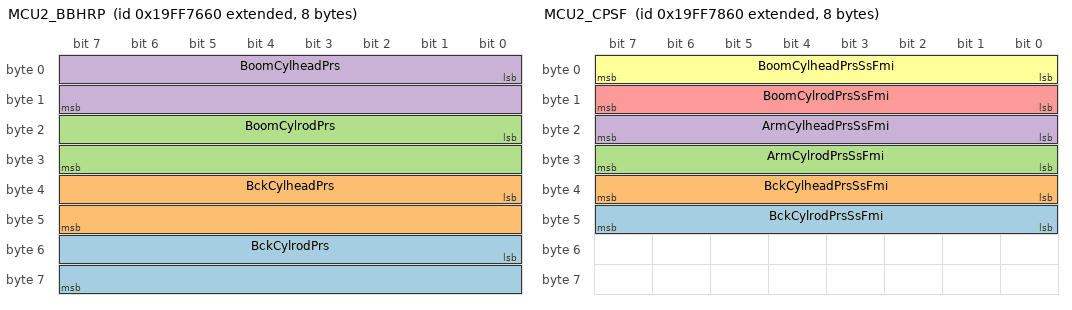
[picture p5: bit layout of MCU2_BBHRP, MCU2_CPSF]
BO_ 2583656032 MCU2_BBHRP: 8 MCU2
 SG_ BckCylrodPrs : 48|16@1+ (0.25,0) [0|500] "bar" Vector__XXX
 SG_ BckCylheadPrs : 32|16@1+ (0.25,0) [0|500] "bar" Vector__XXX
 SG_ BoomCylrodPrs : 16|16@1+ (0.25,0) [0|500] "bar" Vector__XXX
 SG_ BoomCylheadPrs : 0|16@1+ (0.25,0) [0|500] "bar" Vector__XXX

BO_ 2583656288 MCU2_AHRP: 8 MCU2
 SG_ ArmCylrodPrs : 16|16@1+ (0.25,0) [0|500] "bar" Vector__XXX
 SG_ ArmCylheadPrs : 0|16@1+ (0.25,0) [0|500] "bar" Vector__XXX

BO_ 2583656544 MCU2_CPSF: 8 MCU2
 SG_ BckCylrodPrsSsFmi : 40|8@1+ (1,0) [0|255] "" Vector__XXX
 SG_ BckCylheadPrsSsFmi : 32|8@1+ (1,0) [0|255] "" Vector__XXX
 SG_ ArmCylrodPrsSsFmi : 24|8@1+ (1,0) [0|255] "" Vector__XXX
 SG_ ArmCylheadPrsSsFmi : 16|8@1+ (1,0) [0|255] "" Vector__XXX
 SG_ BoomCylrodPrsSsFmi : 8|8@1+ (1,0) [0|255] "" Vector__XXX
 SG_ BoomCylheadPrsSsFmi : 0|8@1+ (1,0) [0|255] "" Vector__XXX

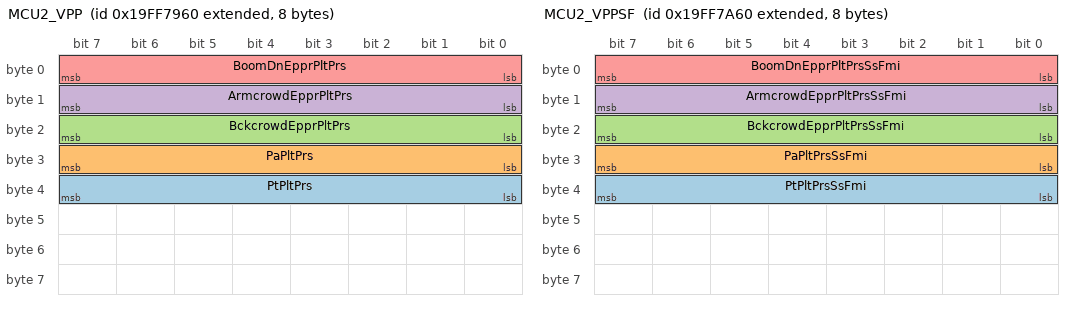
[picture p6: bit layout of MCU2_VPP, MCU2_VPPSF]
BO_ 2583656800 MCU2_VPP: 8 MCU2
 SG_ PtPltPrs : 32|8@1+ (0.25,0) [0|50] "bar" Vector__XXX
 SG_ PaPltPrs : 24|8@1+ (0.25,0) [0|50] "bar" Vector__XXX
 SG_ BckcrowdEpprPltPrs : 16|8@1+ (0.25,0) [0|50] "bar" Vector__XXX
 SG_ ArmcrowdEpprPltPrs : 8|8@1+ (0.25,0) [0|50] "bar" Vector__XXX
 SG_ BoomDnEpprPltPrs : 0|8@1+ (0.25,0) [0|50] "bar" Vector__XXX

BO_ 2583657056 MCU2_VPPSF: 8 MCU2
 SG_ PtPltPrsSsFmi : 32|8@1+ (1,0) [0|255] "" Vector__XXX
 SG_ PaPltPrsSsFmi : 24|8@1+ (1,0) [0|255] "" Vector__XXX
 SG_ BckcrowdEpprPltPrsSsFmi : 16|8@1+ (1,0) [0|255] "" Vector__XXX
 SG_ ArmcrowdEpprPltPrsSsFmi : 8|8@1+ (1,0) [0|255] "" Vector__XXX
 SG_ BoomDnEpprPltPrsSsFmi : 0|8@1+ (1,0) [0|255] "" Vector__XXX

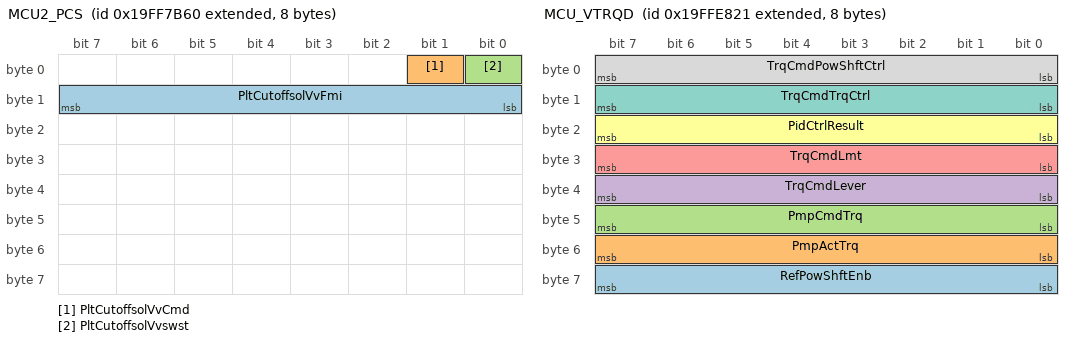
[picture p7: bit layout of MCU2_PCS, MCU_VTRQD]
BO_ 2583657312 MCU2_PCS: 8 MCU2
 SG_ PltCutoffsolVvFmi : 8|8@1+ (1,0) [0|255] "" Vector__XXX
 SG_ PltCutoffsolVvCmd : 1|1@1+ (1,0) [0|1] "" Vector__XXX
 SG_ PltCutoffsolVvswst : 0|1@1+ (1,0) [0|1] "" Vector__XXX

BO_ 2583667233 MCU_CBCC: 8 MCU

BO_ 2583683873 MCU_FJPP: 8 MCU

BO_ 2583684129 MCU_TJPP: 8 MCU

BO_ 2583684385 MCU_VFD: 8 MCU
 SG_ Qa2 : 50|10@1+ (10,0) [0|10230] "" Vector__XXX
 SG_ Qa1 : 40|10@1+ (10,0) [0|10230] "" Vector__XXX

BO_ 2583684641 MCU_VP1D: 8 MCU
 SG_ Pcmd1 : 0|12@1+ (0.25,0) [0|1023.75] "" Vector__XXX

BO_ 2583684897 MCU_VP2D: 8 MCU
 SG_ Pcmd2 : 0|12@1+ (0.25,0) [0|1023.75] "" Vector__XXX

BO_ 2583685153 MCU_VTRQD: 8 MCU
 SG_ RefPowShftEnb : 56|8@1+ (8,800) [800|2000] "Rpm" Vector__XXX
 SG_ PmpActTrq : 48|8@1+ (0.5,0) [0|127.5] "%" Vector__XXX
 SG_ PmpCmdTrq : 40|8@1+ (0.5,0) [0|127.5] "%" Vector__XXX
 SG_ TrqCmdLever : 32|8@1+ (0.5,0) [0|127.5] "%" Vector__XXX
 SG_ TrqCmdLmt : 24|8@1+ (0.5,0) [0|127.5] "%" Vector__XXX
 SG_ PidCtrlResult : 16|8@1+ (-0.5,0) [-125|125] "%" Vector__XXX
 SG_ TrqCmdTrqCtrl : 8|8@1+ (0.5,0) [0|127.5] "%" Vector__XXX
 SG_ TrqCmdPowShftCtrl : 0|8@1+ (0.5,0) [0|127.5] "%" Vector__XXX

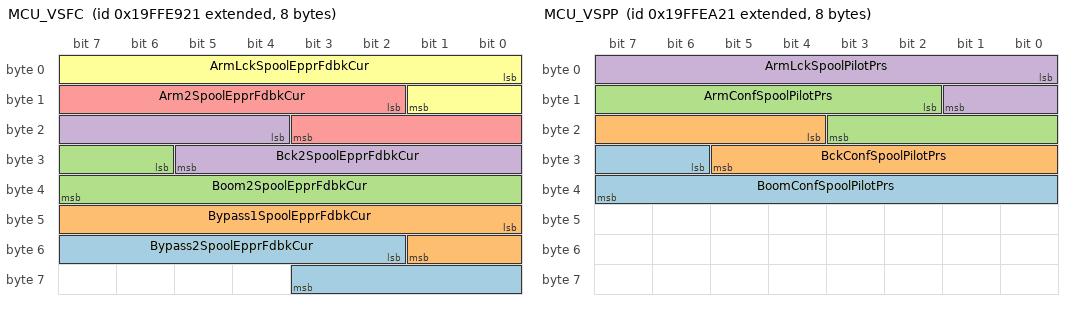
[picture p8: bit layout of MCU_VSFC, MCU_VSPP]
BO_ 2583685409 MCU_VSFC: 8 MCU
 SG_ Bypass2SpoolEpprFdbkCur : 50|10@1+ (1,0) [0|1000] "mA" Vector__XXX
 SG_ Bypass1SpoolEpprFdbkCur : 40|10@1+ (1,0) [0|1000] "mA" Vector__XXX
 SG_ Boom2SpoolEpprFdbkCur : 30|10@1+ (1,0) [0|1000] "mA" Vector__XXX
 SG_ Bck2SpoolEpprFdbkCur : 20|10@1+ (1,0) [0|1000] "mA" Vector__XXX
 SG_ Arm2SpoolEpprFdbkCur : 10|10@1+ (1,0) [0|1000] "mA" Vector__XXX
 SG_ ArmLckSpoolEpprFdbkCur : 0|10@1+ (1,0) [0|1000] "mA" Vector__XXX

BO_ 2583685665 MCU_VSPP: 8 MCU
 SG_ BoomConfSpoolPilotPrs : 30|10@1+ (0.0625,0) [0|50] "bar" Vector__XXX
 SG_ BckConfSpoolPilotPrs : 20|10@1+ (0.0625,0) [0|50] "bar" Vector__XXX
 SG_ ArmConfSpoolPilotPrs : 10|10@1+ (0.0625,0) [0|50] "bar" Vector__XXX
 SG_ ArmLckSpoolPilotPrs : 0|10@1+ (0.0625,0) [0|50] "bar" Vector__XXX

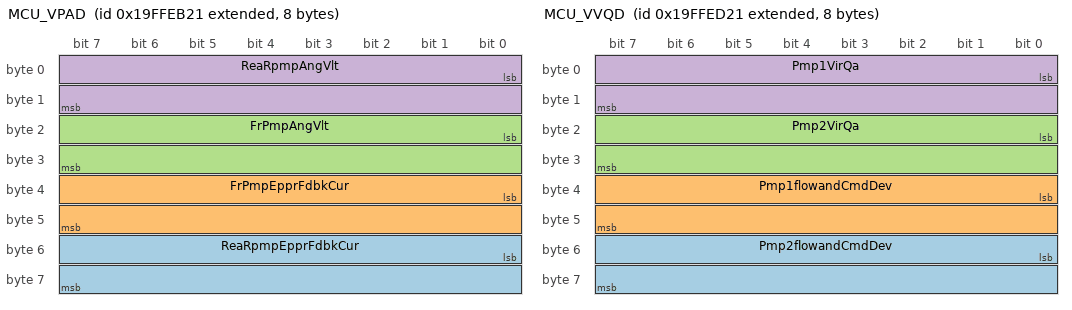
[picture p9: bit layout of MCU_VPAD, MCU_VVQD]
BO_ 2583685921 MCU_VPAD: 8 MCU
 SG_ ReaRpmpEpprFdbkCur : 48|16@1+ (1,0) [0|1000] "mA" Vector__XXX
 SG_ FrPmpEpprFdbkCur : 32|16@1+ (1,0) [0|1000] "mA" Vector__XXX
 SG_ FrPmpAngVlt : 16|16@1+ (1,0) [0|10000] "mV" Vector__XXX
 SG_ ReaRpmpAngVlt : 0|16@1+ (1,0) [0|10000] "mV" Vector__XXX

BO_ 2583686177 MCU_VTD: 8 MCU
 SG_ FrPmpAngVlt : 16|16@1+ (1,-40) [-40|250] "Celsius" Vector__XXX
 SG_ OilFanEpprFdbkCur : 0|16@1+ (1,0) [0|1000] "mA" Vector__XXX

BO_ 2583686433 MCU_VVQD: 8 MCU
 SG_ Pmp2flowandCmdDev : 48|16@1+ (1,0) [0|10000] "cc/sec" Vector__XXX
 SG_ Pmp1flowandCmdDev : 32|16@1+ (1,0) [0|10000] "cc/sec" Vector__XXX
 SG_ Pmp2VirQa : 16|16@1+ (1,0) [0|10000] "cc/sec" Vector__XXX
 SG_ Pmp1VirQa : 0|16@1+ (1,0) [0|10000] "cc/sec" Vector__XXX

BO_ 2382360307 AGW_TRADM2: 250 AGW

BO_ 2382360563 AGW_TRADM1: 250 AGW

BO_ 2382360819 AGW_TAIM1: 250 AGW

BO_ 2382361075 AGW_TRAIM1: 250 AGW

BO_ 2382361331 AGW_TRSIM1: 250 AGW

BO_ 2382361587 AGW_TRRSDM1: 250 AGW

BO_ 2382361843 AGW_TRTSDM1: 250 AGW

BO_ 2382362867 AGW_AFIM1: 250 AGW

BO_ 2382363123 AGW_ALCM1: 250 AGW

BO_ 2382363379 AGW_AHCM1: 250 AGW

BO_ 2382363681 MCU_EIM1: 250 MCU

BO_ 2382364193 MCU_ACM2: 250 MCU

BO_ 2382364449 MCU_ACM1: 250 MCU

BO_ 2566842442 TGU_VDS: 8 TGU
 SG_ Pitch : 32|16@1+ (0.0078125,-200) [-200|301.99] "deg" Vector__XXX
 SG_ Spd : 16|16@1+ (0.00390625,0) [0|250.996] "km/h" Vector__XXX

BO_ 2566845258 TGU_VP1: 8 TGU

BO_ 2583642954 TGU_DKLLG: 250 TGU
 SG_ Dkey : 8|48@1+ (1,0) [0|281474976710655] "" Vector__XXX
 SG_ SelType : 0|3@1+ (1,0) [0|7] "" Vector__XXX

BO_ 2583643210 TGU_DKLUG: 250 TGU
 SG_ DkeyList : 0|64@1+ (1,0) [0|255] "" Vector__XXX

BO_ 2583643466 TGU_DKTL: 250 TGU

BO_ 2583642186 TGU_MPS: 8 TGU
 SG_ TokenRevCnt : 2|8@1+ (1,0) [0|255] "" Vector__XXX
 SG_ MpSt : 0|2@1+ (1,0) [0|3] "" Vector__XXX

BO_ 2583642442 TGU_MPI: 101 TGU
 SG_ MpSt : 800|2@1+ (1,0) [0|3] "" Vector__XXX
 SG_ TguId : 640|160@1+ (1,0) [0|255] "ASCII" Vector__XXX
 SG_ Sname : 480|160@1+ (1,0) [0|255] "ASCII" Vector__XXX
 SG_ Pname : 400|80@1+ (1,0) [0|255] "ASCII" Vector__XXX
 SG_ Vin : 240|160@1+ (1,0) [0|255] "ASCII" Vector__XXX
 SG_ MchType : 208|32@1+ (1,0) [0|255] "ASCII" Vector__XXX
 SG_ Oem : 160|48@1+ (1,0) [0|255] "ASCII" Vector__XXX
 SG_ Mch : 0|160@1+ (1,0) [0|255] "ASCII" Vector__XXX

BO_ 2583642698 TGU_TCNI: 250 TGU
 SG_ NetNm : 8|56@1+ (1,0) [0|255] "ASCII" Vector__XXX
 SG_ Rssi : 5|3@1+ (1,0) [0|7] "" Vector__XXX
 SG_ Type : 2|3@1+ (1,0) [0|7] "" Vector__XXX
 SG_ Con : 0|2@1+ (1,0) [0|3] "" Vector__XXX

BO_ 2583642401 MCU_MPI: 101 MCU
 SG_ MpSt : 800|2@1+ (1,0) [0|3] "" Vector__XXX
 SG_ TguId : 640|160@1+ (1,0) [0|255] "ASCII" Vector__XXX
 SG_ Sname : 480|160@1+ (1,0) [0|255] "ASCII" Vector__XXX
 SG_ Pname : 400|80@1+ (1,0) [0|255] "ASCII" Vector__XXX
 SG_ Vin : 240|160@1+ (1,0) [0|255] "ASCII" Vector__XXX
 SG_ MchType : 208|32@1+ (1,0) [0|255] "ASCII" Vector__XXX
 SG_ Oem : 160|48@1+ (1,0) [0|255] "ASCII" Vector__XXX
 SG_ Mch : 0|160@1+ (1,0) [0|255] "ASCII" Vector__XXX

BO_ 2583662698 PHM_TGU_PHMWG: 8 TGU
 SG_ WarnPopEgOilQual : 3|3@1+ (1,0) [0|7] "" Vector__XXX
 SG_ WarnPopHyhOilQual : 0|3@1+ (1,0) [0|7] "" Vector__XXX

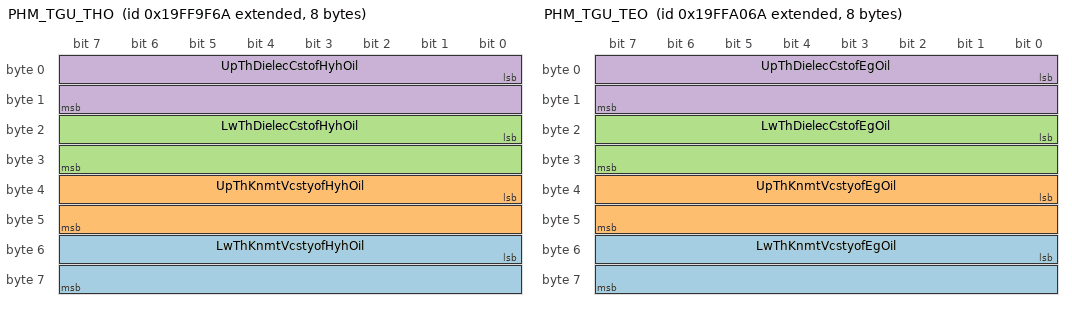
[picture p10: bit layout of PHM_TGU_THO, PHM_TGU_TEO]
BO_ 2583666538 PHM_TGU_THO: 8 TGU
 SG_ LwThKnmtVcstyofHyhOil : 48|16@1+ (0.00778149,0) [0|500] "" Vector__XXX
 SG_ UpThKnmtVcstyofHyhOil : 32|16@1+ (0.00778149,0) [0|500] "" Vector__XXX
 SG_ LwThDielecCstofHyhOil : 16|16@1+ (0.0001220703125,0) [0|7.844] "" Vector__XXX
 SG_ UpThDielecCstofHyhOil : 0|16@1+ (0.0001220703125,0) [0|7.844] "" Vector__XXX

BO_ 2583666794 PHM_TGU_TEO: 8 TGU
 SG_ LwThKnmtVcstyofEgOil : 48|16@1+ (0.00778149,0) [0|500] "" Vector__XXX
 SG_ UpThKnmtVcstyofEgOil : 32|16@1+ (0.00778149,0) [0|500] "" Vector__XXX
 SG_ LwThDielecCstofEgOil : 16|16@1+ (0.0001220703125,0) [0|7.844] "" Vector__XXX
 SG_ UpThDielecCstofEgOil : 0|16@1+ (0.0001220703125,0) [0|7.844] "" Vector__XXX

BO_ 2583667050 PHM_TGU_KVO: 8 TGU
 SG_ KnmtVcstyofEgOil : 16|16@1+ (0.00778149,0) [0|500] "" Vector__XXX
 SG_ KnmtVcstyofHyhOil : 0|16@1+ (0.00778149,0) [0|500] "" Vector__XXX

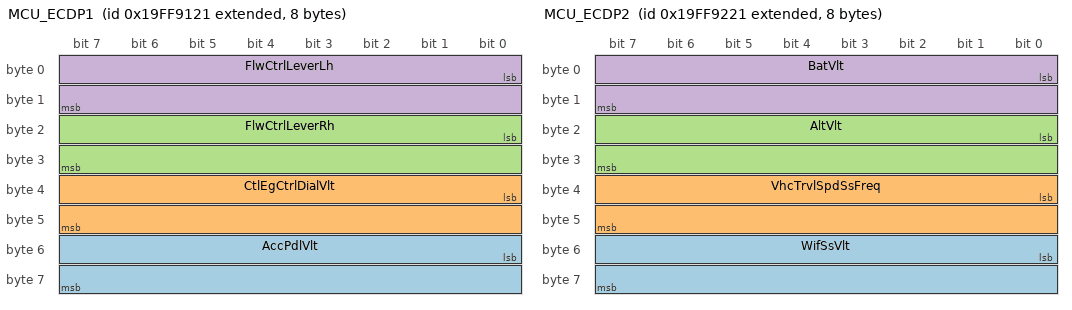
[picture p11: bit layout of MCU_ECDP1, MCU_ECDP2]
BO_ 2583662881 MCU_ECDP1: 8 MCU
 SG_ AccPdlVlt : 48|16@1+ (0.001,0) [0|64.255] "" Vector__XXX
 SG_ CtlEgCtrlDialVlt : 32|16@1+ (0.001,0) [0|64.255] "" Vector__XXX
 SG_ FlwCtrlLeverRh : 16|16@1+ (0.001,0) [0|64.255] "" Vector__XXX
 SG_ FlwCtrlLeverLh : 0|16@1+ (0.001,0) [0|64.255] "" Vector__XXX

BO_ 2583663137 MCU_ECDP2: 8 MCU
 SG_ WifSsVlt : 48|16@1+ (0.001,0) [0|64.255] "" Vector__XXX
 SG_ VhcTrvlSpdSsFreq : 32|16@1+ (1,0) [0|65000] "Hz" Vector__XXX
 SG_ AltVlt : 16|16@1+ (0.001,0) [0|64.255] "" Vector__XXX
 SG_ BatVlt : 0|16@1+ (0.001,0) [0|64.255] "" Vector__XXX

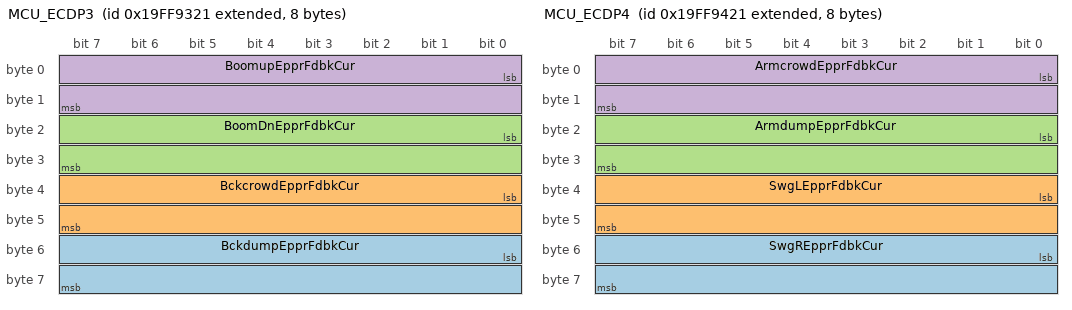
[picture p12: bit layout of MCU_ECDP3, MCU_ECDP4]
BO_ 2583663393 MCU_ECDP3: 8 MCU
 SG_ BckdumpEpprFdbkCur : 48|16@1+ (1,0) [0|1000] "mA" Vector__XXX
 SG_ BckcrowdEpprFdbkCur : 32|16@1+ (1,0) [0|1000] "mA" Vector__XXX
 SG_ BoomDnEpprFdbkCur : 16|16@1+ (1,0) [0|1000] "mA" Vector__XXX
 SG_ BoomupEpprFdbkCur : 0|16@1+ (1,0) [0|1000] "mA" Vector__XXX

BO_ 2583663649 MCU_ECDP4: 8 MCU
 SG_ SwgREpprFdbkCur : 48|16@1+ (1,0) [0|1000] "mA" Vector__XXX
 SG_ SwgLEpprFdbkCur : 32|16@1+ (1,0) [0|1000] "mA" Vector__XXX
 SG_ ArmdumpEpprFdbkCur : 16|16@1+ (1,0) [0|1000] "mA" Vector__XXX
 SG_ ArmcrowdEpprFdbkCur : 0|16@1+ (1,0) [0|1000] "mA" Vector__XXX

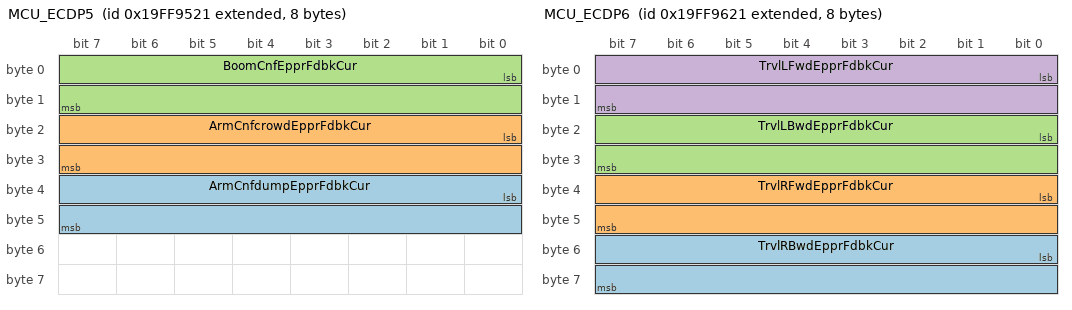
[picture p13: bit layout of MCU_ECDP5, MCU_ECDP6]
BO_ 2583663905 MCU_ECDP5: 8 MCU
 SG_ ArmCnfdumpEpprFdbkCur : 32|16@1+ (1,0) [0|1000] "mA" Vector__XXX
 SG_ ArmCnfcrowdEpprFdbkCur : 16|16@1+ (1,0) [0|1000] "mA" Vector__XXX
 SG_ BoomCnfEpprFdbkCur : 0|16@1+ (1,0) [0|1000] "mA" Vector__XXX

BO_ 2583664161 MCU_ECDP6: 8 MCU
 SG_ TrvlRBwdEpprFdbkCur : 48|16@1+ (1,0) [0|1000] "mA" Vector__XXX
 SG_ TrvlRFwdEpprFdbkCur : 32|16@1+ (1,0) [0|1000] "mA" Vector__XXX
 SG_ TrvlLBwdEpprFdbkCur : 16|16@1+ (1,0) [0|1000] "mA" Vector__XXX
 SG_ TrvlLFwdEpprFdbkCur : 0|16@1+ (1,0) [0|1000] "mA" Vector__XXX

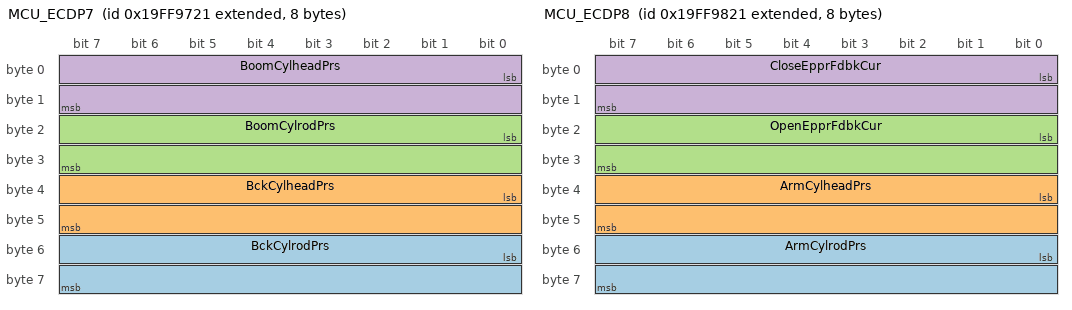
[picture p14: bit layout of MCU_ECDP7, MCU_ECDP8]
BO_ 2583664417 MCU_ECDP7: 8 MCU
 SG_ BckCylrodPrs : 48|16@1+ (0.25,0) [0|500] "bar" Vector__XXX
 SG_ BckCylheadPrs : 32|16@1+ (0.25,0) [0|500] "bar" Vector__XXX
 SG_ BoomCylrodPrs : 16|16@1+ (0.25,0) [0|500] "bar" Vector__XXX
 SG_ BoomCylheadPrs : 0|16@1+ (0.25,0) [0|500] "bar" Vector__XXX

BO_ 2583664673 MCU_ECDP8: 8 MCU
 SG_ ArmCylrodPrs : 48|16@1+ (0.25,0) [0|500] "bar" Vector__XXX
 SG_ ArmCylheadPrs : 32|16@1+ (0.25,0) [0|500] "bar" Vector__XXX
 SG_ OpenEpprFdbkCur : 16|16@1+ (1,0) [0|1000] "mA" Vector__XXX
 SG_ CloseEpprFdbkCur : 0|16@1+ (1,0) [0|1000] "mA" Vector__XXX

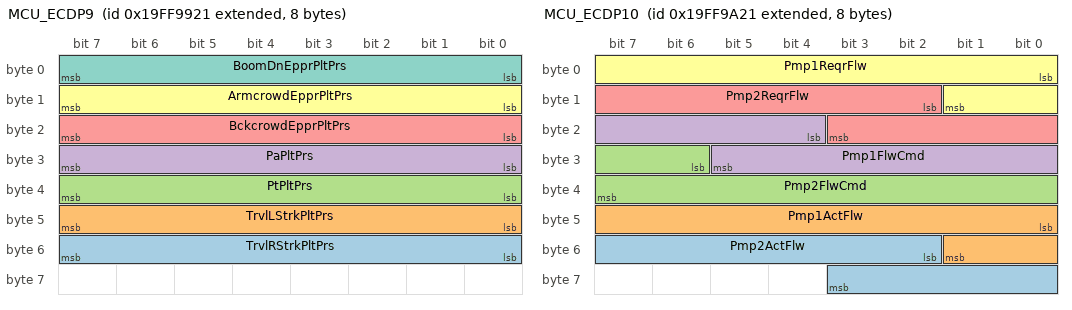
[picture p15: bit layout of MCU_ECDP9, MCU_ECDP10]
BO_ 2583664929 MCU_ECDP9: 8 MCU
 SG_ TrvlRStrkPltPrs : 48|8@1+ (0.25,0) [0|50] "bar" Vector__XXX
 SG_ TrvlLStrkPltPrs : 40|8@1+ (0.25,0) [0|50] "bar" Vector__XXX
 SG_ PtPltPrs : 32|8@1+ (0.25,0) [0|50] "bar" Vector__XXX
 SG_ PaPltPrs : 24|8@1+ (0.25,0) [0|50] "bar" Vector__XXX
 SG_ BckcrowdEpprPltPrs : 16|8@1+ (0.25,0) [0|50] "bar" Vector__XXX
 SG_ ArmcrowdEpprPltPrs : 8|8@1+ (0.25,0) [0|50] "bar" Vector__XXX
 SG_ BoomDnEpprPltPrs : 0|8@1+ (0.25,0) [0|50] "bar" Vector__XXX

BO_ 2583665185 MCU_ECDP10: 8 MCU
 SG_ Pmp2ActFlw : 50|10@1+ (10,0) [0|10000] "cc/sec" Vector__XXX
 SG_ Pmp1ActFlw : 40|10@1+ (10,0) [0|10000] "cc/sec" Vector__XXX
 SG_ Pmp2FlwCmd : 30|10@1+ (10,0) [0|10000] "cc/sec" Vector__XXX
 SG_ Pmp1FlwCmd : 20|10@1+ (10,0) [0|10000] "cc/sec" Vector__XXX
 SG_ Pmp2ReqrFlw : 10|10@1+ (10,0) [0|10000] "cc/sec" Vector__XXX
 SG_ Pmp1ReqrFlw : 0|10@1+ (10,0) [0|10000] "cc/sec" Vector__XXX

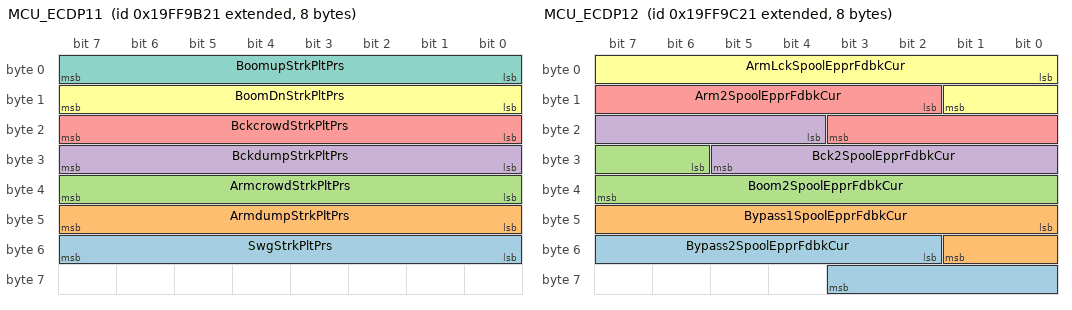
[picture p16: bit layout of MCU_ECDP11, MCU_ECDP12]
BO_ 2583665441 MCU_ECDP11: 8 MCU
 SG_ SwgStrkPltPrs : 48|8@1+ (0.25,0) [0|50] "bar" Vector__XXX
 SG_ ArmdumpStrkPltPrs : 40|8@1+ (0.25,0) [0|50] "bar" Vector__XXX
 SG_ ArmcrowdStrkPltPrs : 32|8@1+ (0.25,0) [0|50] "bar" Vector__XXX
 SG_ BckdumpStrkPltPrs : 24|8@1+ (0.25,0) [0|50] "bar" Vector__XXX
 SG_ BckcrowdStrkPltPrs : 16|8@1+ (0.25,0) [0|50] "bar" Vector__XXX
 SG_ BoomDnStrkPltPrs : 8|8@1+ (0.25,0) [0|50] "bar" Vector__XXX
 SG_ BoomupStrkPltPrs : 0|8@1+ (0.25,0) [0|50] "bar" Vector__XXX

BO_ 2583665697 MCU_ECDP12: 8 MCU
 SG_ Bypass2SpoolEpprFdbkCur : 50|10@1+ (1,0) [0|1000] "mA" Vector__XXX
 SG_ Bypass1SpoolEpprFdbkCur : 40|10@1+ (1,0) [0|1000] "mA" Vector__XXX
 SG_ Boom2SpoolEpprFdbkCur : 30|10@1+ (1,0) [0|1000] "mA" Vector__XXX
 SG_ Bck2SpoolEpprFdbkCur : 20|10@1+ (1,0) [0|1000] "mA" Vector__XXX
 SG_ Arm2SpoolEpprFdbkCur : 10|10@1+ (1,0) [0|1000] "mA" Vector__XXX
 SG_ ArmLckSpoolEpprFdbkCur : 0|10@1+ (1,0) [0|1000] "mA" Vector__XXX

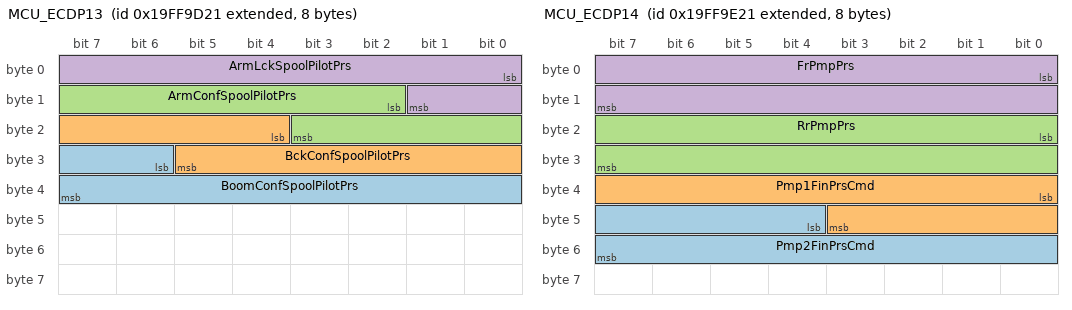
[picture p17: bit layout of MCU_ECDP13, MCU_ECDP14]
BO_ 2583665953 MCU_ECDP13: 8 MCU
 SG_ BoomConfSpoolPilotPrs : 30|10@1+ (0.0625,0) [0|50] "bar" Vector__XXX
 SG_ BckConfSpoolPilotPrs : 20|10@1+ (0.0625,0) [0|50] "bar" Vector__XXX
 SG_ ArmConfSpoolPilotPrs : 10|10@1+ (0.0625,0) [0|50] "bar" Vector__XXX
 SG_ ArmLckSpoolPilotPrs : 0|10@1+ (0.0625,0) [0|50] "bar" Vector__XXX

BO_ 2583666209 MCU_ECDP14: 8 MCU
 SG_ Pmp2FinPrsCmd : 44|12@1+ (0.25,0) [0|500] "bar" Vector__XXX
 SG_ Pmp1FinPrsCmd : 32|12@1+ (0.25,0) [0|500] "bar" Vector__XXX
 SG_ RrPmpPrs : 16|16@1+ (0.0625,0) [0|500] "bar" Vector__XXX
 SG_ FrPmpPrs : 0|16@1+ (0.0625,0) [0|500] "bar" Vector__XXX

BO_ 2633656127 HDOQS_OQM2: 8 HDOQS
 SG_ Oilresistivity : 0|32@1+ (1000,0) [0|4211081215000] "?" Vector__XXX

BO_ 2633656238 EGOQS_OQM2: 8 EGOQS
 SG_ Oilresistivity : 0|32@1+ (1000,0) [0|4211081215000] "?" Vector__XXX

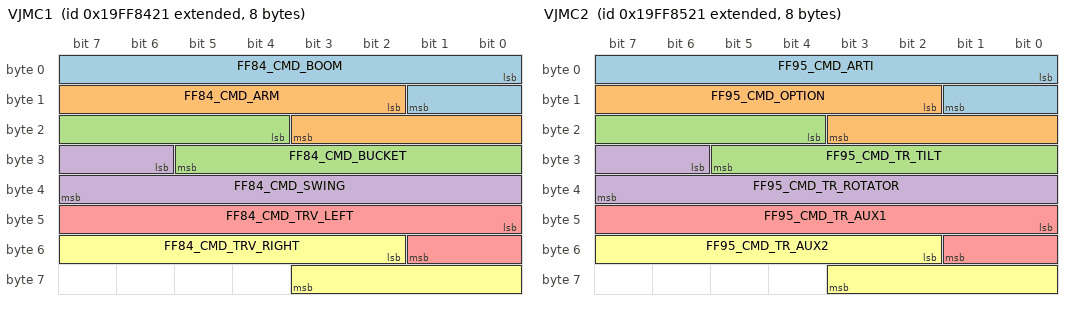
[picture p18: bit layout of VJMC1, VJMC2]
BO_ 2583659553 VJMC1: 8 Vector__XXX
 SG_ FF84_CMD_BOOM : 0|10@1+ (4,-1000) [-1000|3092] "" Vector__XXX
 SG_ FF84_CMD_ARM : 10|10@1+ (4,-1000) [-1000|3092] "" Vector__XXX
 SG_ FF84_CMD_BUCKET : 20|10@1+ (4,-1000) [-1000|3092] "" Vector__XXX
 SG_ FF84_CMD_SWING : 30|10@1+ (4,-1000) [-1000|3092] "" Vector__XXX
 SG_ FF84_CMD_TRV_LEFT : 40|10@1+ (4,-1000) [-1000|3092] "" Vector__XXX
 SG_ FF84_CMD_TRV_RIGHT : 50|10@1+ (4,-1000) [-1000|3092] "" Vector__XXX

BO_ 2583659809 VJMC2: 8 Vector__XXX
 SG_ FF95_CMD_ARTI : 0|10@1+ (4,-1000) [-1000|3092] "" Vector__XXX
 SG_ FF95_CMD_OPTION : 10|10@1+ (4,-1000) [-1000|3092] "" Vector__XXX
 SG_ FF95_CMD_TR_TILT : 20|10@1+ (4,-1000) [-1000|3092] "" Vector__XXX
 SG_ FF95_CMD_TR_ROTATOR : 30|10@1+ (4,-1000) [-1000|3092] "" Vector__XXX
 SG_ FF95_CMD_TR_AUX1 : 40|10@1+ (4,-1000) [-1000|3092] "" Vector__XXX
 SG_ FF95_CMD_TR_AUX2 : 50|10@1+ (4,-1000) [-1000|3092] "" Vector__XXX

CM_ BO_ 2566904865 "CE Type Information";
CM_ SG_ 2566904865 SalesRegion "SalesRegion";
CM_ SG_ 2566904865 TcuType "TCUType";
CM_ SG_ 2566904865 JoyType "JoystickType";
CM_ SG_ 2566904865 McvCtrlType "MCVControlType";
CM_ SG_ 2566904865 McvType "MCVType";
CM_ SG_ 2566904865 PmpCtrlType "PumpControlType";
CM_ SG_ 2566904865 PmpType "PumpType";
CM_ SG_ 2566904865 EcuMaker "ECUmaker";
CM_ SG_ 2566904865 EgMaker "Enginemaker";
CM_ SG_ 2566904865 ModelYearVer "ModelYearVersion";
CM_ SG_ 2566904865 MchType "MachineType";
CM_ SG_ 2566904865 MchClass "MachineClassification";
CM_ SG_ 2566904865 MchGen "MachineGeneration";
CM_ SG_ 2566904865 EmsCtrl "EmissionControl";
CM_ BO_ 2566905121 "Attachment  Setting Data Information";
CM_ SG_ 2566905121 TwUseFlow4 "TwoWayUseFlow4";
CM_ SG_ 2566905121 TwUseFlow3 "TwoWayUseFlow3";
CM_ SG_ 2566905121 TwUseFlow2 "TwoWayUseFlow2";
CM_ SG_ 2566905121 TwUseFlow1 "TwoWayUseFlow1";
CM_ SG_ 2566905121 TwUseFlow0 "TwoWayUseFlow0";
CM_ SG_ 2566905121 TwSetFlow4 "TwoWaySetFlow4";
CM_ SG_ 2566905121 TwSetFlow3 "TwoWaySetFlow3";
CM_ SG_ 2566905121 TwSetFlow2 "TwoWaySetFlow2";
CM_ SG_ 2566905121 TwSetFlow1 "TwoWaySetFlow1";
CM_ SG_ 2566905121 TwSetFlow0 "TwoWaySetFlow0";
CM_ SG_ 2566905121 TwMinFlowAtt4 "TwoWayMinFlow(ATT)4";
CM_ SG_ 2566905121 TwMinFlowAtt3 "TwoWayMinFlow(ATT)3";
CM_ SG_ 2566905121 TwMinFlowAtt2 "TwoWayMinFlow(ATT)2";
CM_ SG_ 2566905121 TwMinFlowAtt1 "TwoWayMinFlow(ATT)1";
CM_ SG_ 2566905121 TwMinFlowAtt0 "TwoWayMinFlow(ATT)0";
CM_ SG_ 2566905121 TwMaxFlowAtt4 "TwoWayMaxFlow(ATT)4";
CM_ SG_ 2566905121 TwMaxFlowAtt3 "TwoWayMaxFlow(ATT)3";
CM_ SG_ 2566905121 TwMaxFlowAtt2 "TwoWayMaxFlow(ATT)2";
CM_ SG_ 2566905121 TwMaxFlowAtt1 "TwoWayMaxFlow(ATT)1";
CM_ SG_ 2566905121 TwMaxFlowAtt0 "TwoWayMaxFlow(ATT)0";
CM_ SG_ 2566905121 TwMaxFlowPmp4 "TwoWayMaxFlow(Pump)4";
CM_ SG_ 2566905121 TwMaxFlowPmp3 "TwoWayMaxFlow(Pump)3";
CM_ SG_ 2566905121 TwMaxFlowPmp2 "TwoWayMaxFlow(Pump)2";
CM_ SG_ 2566905121 TwMaxFlowPmp1 "TwoWayMaxFlow(Pump)1";
CM_ SG_ 2566905121 TwMaxFlowPmp0 "TwoWayMaxFlow(Pump)0";
CM_ SG_ 2566905121 TwPrs4 "TwoWayPress4";
CM_ SG_ 2566905121 TwPrs3 "TwoWayPress3";
CM_ SG_ 2566905121 TwPrs2 "TwoWayPress2";
CM_ SG_ 2566905121 TwPrs1 "TwoWayPress1";
CM_ SG_ 2566905121 TwPrs0 "TwoWayPress0";
CM_ SG_ 2566905121 TwRpm4 "TwoWayRpm4";
CM_ SG_ 2566905121 TwRpm3 "TwoWayRpm3";
CM_ SG_ 2566905121 TwRpm2 "TwoWayRpm2";
CM_ SG_ 2566905121 TwRpm1 "TwoWayRpm1";
CM_ SG_ 2566905121 TwRpm0 "TwoWayRpm0";
CM_ SG_ 2566905121 Tw4BrkrBtnType "TWoWay4;ThumbWheelType";
CM_ SG_ 2566905121 Tw4TwoPmpOpt "TWoWay4;2PumpOption";
CM_ SG_ 2566905121 Tw4SelAttNo "TWoWay4;SelectedATTNumber(1~5)";
CM_ SG_ 2566905121 Tw4SelAttType "TWoWay4;SelectedATTType(OnewayorTwoway)";
CM_ SG_ 2566905121 Tw3BrkrBtnType "TWoWay3;ThumbWheelType";
CM_ SG_ 2566905121 Tw3TwoPmpOpt "TWoWay3;2PumpOption";
CM_ SG_ 2566905121 Tw3SelAttNo "TWoWay3;SelectedATTNumber(1~5)";
CM_ SG_ 2566905121 Tw3SelAttType "TWoWay3;SelectedATTType(OnewayorTwoway)";
CM_ SG_ 2566905121 Tw2BrkrBtnType "TWoWay2;ThumbWheelType";
CM_ SG_ 2566905121 Tw2TwoPmpOpt "TWoWay2;2PumpOption";
CM_ SG_ 2566905121 Tw2SelAttNo "TWoWay2;SelectedATTNumber(1~5)";
CM_ SG_ 2566905121 Tw2SelAttType "TWoWay2;SelectedATTType(OnewayorTwoway)";
CM_ SG_ 2566905121 Tw1BrkrBtnType "TWoWay1;ThumbWheelType";
CM_ SG_ 2566905121 Tw1TwoPmpOpt "TWoWay1;2PumpOption";
CM_ SG_ 2566905121 Tw1SelAttNo "TWoWay1;SelectedATTNumber(1~5)";
CM_ SG_ 2566905121 Tw1SelAttType "TWoWay1;SelectedATTType(OnewayorTwoway)";
CM_ SG_ 2566905121 Tw0BrkrBtnType "TWoWay0;ThumbWheelType";
CM_ SG_ 2566905121 Tw0TwoPmpOpt "TWoWay0;2PumpOption";
CM_ SG_ 2566905121 Tw0SelAttNo "TWoWay0;SelectedATTNumber(1~5)";
CM_ SG_ 2566905121 Tw0SelAttType "TWoWay0;SelectedATTType(OnewayorTwoway)";
CM_ SG_ 2566905121 OwUseFlow4 "OneWayUseFlow4";
CM_ SG_ 2566905121 OwUseFlow3 "OneWayUseFlow3";
CM_ SG_ 2566905121 OwUseFlow2 "OneWayUseFlow2";
CM_ SG_ 2566905121 OwUseFlow1 "OneWayUseFlow1";
CM_ SG_ 2566905121 OwUseFlow0 "OneWayUseFlow0";
CM_ SG_ 2566905121 OwSetFlow4 "OneWaySetFlow4";
CM_ SG_ 2566905121 OwSetFlow3 "OneWaySetFlow3";
CM_ SG_ 2566905121 OwSetFlow2 "OneWaySetFlow2";
CM_ SG_ 2566905121 OwSetFlow1 "OneWaySetFlow1";
CM_ SG_ 2566905121 OwSetFlow0 "OneWaySetFlow0";
CM_ SG_ 2566905121 OwMinFlowAtt4 "OneWayMinFlow(ATT)4";
CM_ SG_ 2566905121 OwMinFlowAtt3 "OneWayMinFlow(ATT)3";
CM_ SG_ 2566905121 OwMinFlowAtt2 "OneWayMinFlow(ATT)2";
CM_ SG_ 2566905121 OwMinFlowAtt1 "OneWayMinFlow(ATT)1";
CM_ SG_ 2566905121 OwMinFlowAtt0 "OneWayMinFlow(ATT)0";
CM_ SG_ 2566905121 OwMaxFlowAtt4 "OneWayMaxFlow(ATT)4";
CM_ SG_ 2566905121 OwMaxFlowAtt3 "OneWayMaxFlow(ATT)3";
CM_ SG_ 2566905121 OwMaxFlowAtt2 "OneWayMaxFlow(ATT)2";
CM_ SG_ 2566905121 OwMaxFlowAtt1 "OneWayMaxFlow(ATT)1";
CM_ SG_ 2566905121 OwMaxFlowAtt0 "OneWayMaxFlow(ATT)0";
CM_ SG_ 2566905121 OwMaxFlowPmp4 "OneWayMaxFlow(Pump)4";
CM_ SG_ 2566905121 OwMaxFlowPmp3 "OneWayMaxFlow(Pump)3";
CM_ SG_ 2566905121 OwMaxFlowPmp2 "OneWayMaxFlow(Pump)2";
CM_ SG_ 2566905121 OwMaxFlowPmp1 "OneWayMaxFlow(Pump)1";
CM_ SG_ 2566905121 OwMaxFlowPmp0 "OneWayMaxFlow(Pump)0";
CM_ SG_ 2566905121 OwPrs4 "OneWayPress4";
CM_ SG_ 2566905121 OwPrs3 "OneWayPress3";
CM_ SG_ 2566905121 OwPrs2 "OneWayPress2";
CM_ SG_ 2566905121 OwPrs1 "OneWayPress1";
CM_ SG_ 2566905121 OwPrs0 "OneWayPress0";
CM_ SG_ 2566905121 OwRpm4 "OneWayRpm4";
CM_ SG_ 2566905121 OwRpm3 "OneWayRpm3";
CM_ SG_ 2566905121 OwRpm2 "OneWayRpm2";
CM_ SG_ 2566905121 OwRpm1 "OneWayRpm1";
CM_ SG_ 2566905121 OwRpm0 "OneWayRpm0";
CM_ SG_ 2566905121 RttCurStep "RotatingCurrentStep";
CM_ SG_ 2566905121 TwCurStep "TwoWayCurrentStep";
CM_ SG_ 2566905121 Ow4BrkrBtnType "OneWay4;BreakerButtonType";
CM_ SG_ 2566905121 Ow4TwoPmpOpt "OneWay4;2PumpOption";
CM_ SG_ 2566905121 Ow4SelAttNo "OneWay4;SelectedATTNumber(1~5)";
CM_ SG_ 2566905121 Ow4SelAttType "OneWay4;SelectedATTType(OnewayorTwoway)";
CM_ SG_ 2566905121 OwCurStep "OneWayCurrentStep";
CM_ SG_ 2566905121 Ow3BrkrBtnType "OneWay3;BreakerButtonType";
CM_ SG_ 2566905121 Ow3TwoPmpOpt "OneWay3;2PumpOption";
CM_ SG_ 2566905121 Ow3SelAttNo "OneWay3;SelectedATTNumber(1~5)";
CM_ SG_ 2566905121 Ow3SelAttType "OneWay3;SelectedATTType(OnewayorTwoway)";
CM_ SG_ 2566905121 Ow2BrkrBtnType "OneWay2;BreakerButtonType";
CM_ SG_ 2566905121 Ow2TwoPmpOpt "OneWay2;2PumpOption";
CM_ SG_ 2566905121 Ow2SelAttNo "OneWay2;SelectedATTNumber(1~5)";
CM_ SG_ 2566905121 Ow2SelAttType "OneWay2;SelectedATTType(OnewayorTwoway)";
CM_ SG_ 2566905121 Ow1BrkrBtnType "OneWay1;BreakerButtonType";
CM_ SG_ 2566905121 Ow1TwoPmpOpt "OneWay1;2PumpOption";
CM_ SG_ 2566905121 Ow1SelAttNo "OneWay1;SelectedATTNumber(1~5)";
CM_ SG_ 2566905121 Ow1SelAttType "OneWay1;SelectedATTType(OnewayorTwoway)";
CM_ SG_ 2566905121 Ow0BrkrBtnType "OneWay0;BreakerButtonType";
CM_ SG_ 2566905121 Ow0TwoPmpOpt "OneWay0;2PumpOption";
CM_ SG_ 2566905121 Ow0SelAttNo "OneWay0;SelectedATTNumber(1~5)";
CM_ SG_ 2566905121 Ow0SelAttType "OneWay0;SelectedATTType(OnewayorTwoway)";
CM_ SG_ 2566905121 MaxFlow "MaxFlow";
CM_ SG_ 2566905121 MinFlow "MinFlow";
CM_ SG_ 2566905121 MaxPrsTw "MaxPressTwo";
CM_ SG_ 2566905121 MinPrsTw "MinPressTwo";
CM_ SG_ 2566905121 MaxPrsOw "MaxPressOne";
CM_ SG_ 2566905121 MinPrsOw "MinPressOne";
CM_ SG_ 2566905121 MaxSpd "MaxSpeed";
CM_ SG_ 2566905121 MinSpd "MinSpeed";
CM_ SG_ 2566905121 SelAttTw "SelectedAttachmentTwoway";
CM_ SG_ 2566905121 SelAttOw "SelectedAttachmentOneway";
CM_ BO_ 2566905377 "Fuel Used Data Information";
CM_ SG_ 2566905377 TrvlStd "TravelStandard";
CM_ SG_ 2566905377 TrvlPow "TravelPower";
CM_ SG_ 2566905377 Idle "Idle";
CM_ SG_ 2566905377 AutoIdle "AutoIdle";
CM_ SG_ 2566905377 EcnMd "EconomyMode";
CM_ SG_ 2566905377 StdMd "StandardMode";
CM_ SG_ 2566905377 PowMd "PowerMode";
CM_ SG_ 2566905377 PowPlusMd "Power+Mode";
CM_ BO_ 2566905633 "Used Hour Data Information";
CM_ SG_ 2566905633 TotOprHr "TotalOpertionHour";
CM_ SG_ 2566905633 Co0lTempAbove106 "CoolantTmeperature(Above106?)";
CM_ SG_ 2566905633 Co0lTemp96105 "CoolantTmeperature(96~105?)";
CM_ SG_ 2566905633 Co0lTemp96100 "CoolantTmeperature(96~100?)";
CM_ SG_ 2566905633 Co0lTemp9195 "CoolantTmeperature(91~95?)";
CM_ SG_ 2566905633 Co0lTemp8190 "CoolantTmeperature(81~90?)";
CM_ SG_ 2566905633 Co0lTempBelow80 "CoolantTmeperature(Below80?)";
CM_ SG_ 2566905633 HydOilTmpAbove96 "Hyd.OilTemperature(Above96?)";
CM_ SG_ 2566905633 HydOilTmp9195 "Hyd.OilTemperature(91~95?)";
CM_ SG_ 2566905633 HydOilTmp8190 "Hyd.OilTemperature(81~90?)";
CM_ SG_ 2566905633 HydOilTmp7180 "Hyd.OilTemperature(71~80?)";
CM_ SG_ 2566905633 HydOilTmp5170 "Hyd.OilTemperature(51~70?)";
CM_ SG_ 2566905633 HydOilTmpBelow50 "Hyd.OilTemperature(Below50?)";
CM_ SG_ 2566905633 TwMd "TwoWayMode";
CM_ SG_ 2566905633 BrkrMd "BreakerMode";
CM_ SG_ 2566905633 LiftMd "LiftMode";
CM_ SG_ 2566905633 TrvlStd "TravelStandard";
CM_ SG_ 2566905633 TrvlPow "TravelPower";
CM_ SG_ 2566905633 Idle "Idle";
CM_ SG_ 2566905633 AutoIdle "AutoIdle";
CM_ SG_ 2566905633 EcnMd "EconomyMode";
CM_ SG_ 2566905633 StdMd "StandardMode";
CM_ SG_ 2566905633 PowMd "PowerMode";
CM_ SG_ 2566905633 PowPlusMd "Power+Mode";
CM_ BO_ 2566905889 "Real Time Failure Information";
CM_ SG_ 2566905889 Afc7 "�RealTimeFailureNCode(11bits)+FMI(5bits)";
CM_ SG_ 2566905889 Afc6 "RealTimeFailure6Code(11bits)+FMI(5bits)";
CM_ SG_ 2566905889 Afc5 "RealTimeFailure5Code(11bits)+FMI(5bits)";
CM_ SG_ 2566905889 Afc4 "RealTimeFailure4Code(11bits)+FMI(5bits)";
CM_ SG_ 2566905889 Afc3 "RealTimeFailure3Code(11bits)+FMI(5bits)";
CM_ SG_ 2566905889 Afc2 "RealTimeFailure2Code(11bits)+FMI(5bits)";
CM_ SG_ 2566905889 Afc1 "RealTimeFailure1Code(11bits)+FMI(5bits)";
CM_ BO_ 2566906145 "Failure Log Information";
CM_ SG_ 2566906145 Hfc2FirstOcrTm "FailureLog2FirstOccurenceTime";
CM_ SG_ 2566906145 Hfc2 "FailureLog2Code(11bits)+FMI(5bits)";
CM_ SG_ 2566906145 Hfc2Cnt "FailureLog2Count";
CM_ SG_ 2566906145 Hfc1FirstOcrTm "FailureLog1FirstOccurenceTime";
CM_ SG_ 2566906145 Hfc1 "FailureLog1Code(11bits)+FMI(5bits)";
CM_ SG_ 2566906145 Hfc1Cnt "FailureLog1Count";
CM_ BO_ 2566906401 "AVM Real Time Failure Information";
CM_ BO_ 2566906657 "TMS Permanent Unlock Code";
CM_ SG_ 2566906657 TmsPunlckCode "TMSPernamentUnlockCode";
CM_ BO_ 2566907169 "VCU Software Version ";
CM_ SG_ 2566907169 McuSwVerYear "VCUSWVersion:Year";
CM_ SG_ 2566907169 McuSwVerDay "VCUSWVersion;Day";
CM_ SG_ 2566907169 McuSwVerMonth "VCUSWVersion;Month";
CM_ SG_ 2566907169 McuSwVer "VCUSWVersion";
CM_ BO_ 2566907681 "ECO Guidance Information";
CM_ SG_ 2566907681 IccoFunCrcmdScore "ICCO????????";
CM_ SG_ 2566907681 UnssHydReliefScore "??????Relief??";
CM_ SG_ 2566907681 InIntentBrkPreventScore "???????????????";
CM_ SG_ 2566907681 EmgStpPreventScore "???????";
CM_ SG_ 2566907681 EgMdDnRcmdScore "??????????";
CM_ SG_ 2566907681 LckUpRcmdScore "????????";
CM_ SG_ 2566907681 GrNeutRpmUpScore "????????Rpm????";
CM_ SG_ 2566907681 IdlePrvtScore "????????";
CM_ SG_ 2566907681 ManGrMaxSpdRcmdScore "????????????";
CM_ SG_ 2566907681 Auto14RcmdScore "1-4????????";
CM_ SG_ 2566907681 LisVhcSpdSetDnChngRcmdScore "LIS????????????";
CM_ SG_ 2566907681 LisVhcSpdSetUpChngRcmdScore "LIS????????????";
CM_ SG_ 2566907681 LisFunCrcmdScore "LIS????????";
CM_ SG_ 2566907681 IccoFunCrctm "0";
CM_ SG_ 2566907681 EgMdDnRctm "0";
CM_ SG_ 2566907681 LckUpRcmd "0";
CM_ SG_ 2566907681 IdlePrvtRcmd "0";
CM_ SG_ 2566907681 Auto14Rcmd "0";
CM_ SG_ 2566907681 LisRcmd "0";
CM_ BO_ 2566907937 "Machine Configuration Information";
CM_ SG_ 2566907937 ElecStrJoyThmbWhlConf "ElectricSteeringJoystickThumbwheelConfiguration";
CM_ SG_ 2566907937 Dl06EgFuelEffCalbConf "DL06EngineFuelEfficiencyCalibrationConfiguration";
CM_ SG_ 2566907937 RttThmbWhlDirConf "Rotating????????Configuration";
CM_ SG_ 2566907937 TwThmbWhlDirConf "2way????????Configuration";
CM_ SG_ 2566907937 CanPdlIntChngConf "CANPedalInterchangeabilityConfiguration";
CM_ SG_ 2566907937 TrvlSwgAlmIntChngConf "TravelSwingAlarmInterchangeabilityConfiguration";
CM_ SG_ 2566907937 OprHrTmpIntChngConf "OperationHourPerTemperatureInterchangeabilityConfiguration";
CM_ SG_ 2566907937 QckCouplerIntChngConf "QuickCouplerInterchangeabilityConfiguration";
CM_ SG_ 2566907937 ThmbWhlSensConf "ThumbWheelSensitivityConfiguration";
CM_ SG_ 2566907937 MultiFuncJoyBtnConf "MultifunctionJoystickButtonConfiguration";
CM_ BO_ 2566908449 "MC Weighing Info Group";
CM_ SG_ 2566908449 AssitSwgRh "AssistStatus;SwingRight";
CM_ SG_ 2566908449 AssitSwgLh "AssistStatus;SwingLeft";
CM_ SG_ 2566908449 AssitBck "AssistStatus;Bucket";
CM_ SG_ 2566908449 AssitGrd "AssistStatus;Grade";
CM_ SG_ 2566908449 SafeWrkSideFar "SafeWorkingIndicator;SideFar";
CM_ SG_ 2566908449 SafeWrkSideMid "SafeWorkingIndicator;SideMid";
CM_ SG_ 2566908449 SafeWrkSideNear "SafeWorkingIndicator;SideNear";
CM_ SG_ 2566908449 SafeWrkFrFar "SafeWorkingIndicator;FrontFar";
CM_ SG_ 2566908449 SafeWrkFrMid "SafeWorkingIndicator;FrontMid";
CM_ SG_ 2566908449 SafeWrkFrNear "SafeWorkingIndicator;FrontNear";
CM_ SG_ 2566908449 FrMvGuidArmOut "FrontMovementGuide;ArmOut";
CM_ SG_ 2566908449 FrMvGuidArmIn "FrontMovementGuide;ArmIn";
CM_ SG_ 2566908449 FrMvGuidBoomDn "FrontMovementGuide;BoomDown";
CM_ SG_ 2566908449 FrMvGuidBoomUp "FrontMovementGuide:BoomUp";
CM_ SG_ 2566908449 EfenceTrkWrn "E-fenceWarning;Track";
CM_ SG_ 2566908449 EfenceDzWrn "E-fenceWarning;Dozer";
CM_ SG_ 2566908449 EfenceCabWrn "E-fenceWarning;Cabin";
CM_ SG_ 2566908449 EfenceFSwgRhWrn "E-fenceWarning;SwingRight";
CM_ SG_ 2566908449 EfenceFSwgLhWrn "E-fenceWarning;SwingLeft";
CM_ SG_ 2566908449 EfenceCeilWrn "E-fenceWarning;Ceiling";
CM_ SG_ 2566908449 EfenceFloorWrn "E-fenceWarning;Floor";
CM_ SG_ 2566908449 EfenceWallWrn "E-fenceWarning;Wall";
CM_ BO_ 2566908705 "Truck Weighing Group";
CM_ SG_ 2566908705 TotWhgCurTrk "TotalWeightofcurrenttruck";
CM_ SG_ 2566908705 BckCntCurTrk "BucketCountofcurrenttruck";
CM_ SG_ 2566908705 WghCntSt "WeighingCountStatus";
CM_ SG_ 2566908705 WghSt "WeighingStatus";
CM_ SG_ 2566908705 RelTmBckWhg "RealtimeBucketWeight";
CM_ BO_ 2566908961 "Weighing Calibration Progress Rate";
CM_ SG_ 2566908961 BckZeroCalbStep "BucketZeroCalibration;Step";
CM_ SG_ 2566908961 BckZeroCalbStage "BucketZeroCalibration;Stage";
CM_ SG_ 2566908961 FrMultiCalbStep "FrontMultiCalibration;Step";
CM_ SG_ 2566908961 FrMultiCalbStage "FrontMultiCalibration;Stage";
CM_ SG_ 2566908961 FrSngCalbStep "FrontSingleCalibration;Step";
CM_ SG_ 2566908961 FrSngCalbStage "FrontSingleCalibration;Stage";
CM_ BO_ 2566909217 "Weighing Calibration Cylinder Velocity";
CM_ SG_ 2566909217 TgtArmCylSpdUpLmt "TargetArmCylinderVelocity;UpperLimit";
CM_ SG_ 2566909217 TgtArmCylSpdLwLmt "TargetArmCylinderVelocity;LowerLimit";
CM_ SG_ 2566909217 CurArmCylSpd "CurrentArmCylinderVelocity";
CM_ SG_ 2566909217 TgtBoomCylSpdUpLmt "TargetBoomCylinderVelocity;UpperLimit";
CM_ SG_ 2566909217 TgtBoomCylSpdLwLmt "TargetBoomCylinderVelocity;LowerLimit";
CM_ SG_ 2566909217 CurBoomCylSpd "CurrentBoomCylinderVelocity";
CM_ BO_ 2566909473 "Weighing Calibration joint Angle";
CM_ SG_ 2566909473 TgtArmJointAngEndPos "TargetArmJointAngle;EndPosition";
CM_ SG_ 2566909473 TgtArmJointAngStartPos "TargetArmJointAngle;StartPosition";
CM_ SG_ 2566909473 CurArmJointAng "CurrentArmJointAngle";
CM_ SG_ 2566909473 TgtBoomJointAngEndPos "TargetBoomJointAngle;EndPosition";
CM_ SG_ 2566909473 TgtBoomJointAngStartPos "TargetBoomJointAngle;StartPosition";
CM_ SG_ 2566909473 CurBoomJointAng "CurrentBoomJointAngle";
CM_ BO_ 2566909729 "Lift Assist Data Group";
CM_ SG_ 2566909729 Reach "Reach";
CM_ SG_ 2566909729 Hight "Hight";
CM_ SG_ 2566909729 RatedLoad "RatedLoad";
CM_ SG_ 2566909729 ActLoad "ActualLoad";
CM_ BO_ 2634018819 "TCU_ID";
CM_ BO_ 2566910241 "Analog Sensor Relay Group";
CM_ SG_ 2566910241 SwgAng "SwingAngle";
CM_ BO_ 2566910534 "ETC Calibration Message to VCU";
CM_ BO_ 2566912289 "MC Weighing Handshake Group 4";
CM_ SG_ 2566912289 SsOfsRttAng "SensorOffset;RotationAngle";
CM_ SG_ 2566912289 ImuSsOfsTrttTiltAng "IMUSensorOffset;TiltRotatorTiltAngle";
CM_ SG_ 2566912289 TrttBodyDmsnTQ4 "TiltRotatorBodyDimension:TQ4";
CM_ SG_ 2566912289 TrttBodyDmsnDQ4 "TiltRotatorBodyDimension:DQ4";
CM_ SG_ 2566912289 TrttBodyDmsnAngGdt "TiltRotatorBodyDemension;AnlgeGDT";
CM_ SG_ 2566912289 TrttBodyDmsnDT "TiltRotatorBodyDemension;DT";
CM_ SG_ 2566912289 TrttBodyDmsnGT "TiltRotatorBodyDemension;GT";
CM_ SG_ 2566912289 TrttBodyDmsnDG "TiltRotatorBodyDemension;DG";
CM_ SG_ 2566912289 TrttBodyDmsnVW "TiltRotatorBodyDemension;VW";
CM_ SG_ 2566912289 TrttBodyDmsnUV "TiltRotatorBodyDemension;UV";
CM_ SG_ 2566912289 TrttBodyDmsnTU "TiltRotatorBodyDemension;TU";
CM_ SG_ 2566912289 TrttBck05DmsnAngVwn "TiltRotatorBucket05Demension;AnlgeVWN";
CM_ SG_ 2566912289 TrttBck05DmsnTN "TiltRotatorBucket05Demension;TN";
CM_ SG_ 2566912289 TrttBck05DmsnWN "TiltRotatorBucket05Demension;WN";
CM_ SG_ 2566912289 TrttBck05DmsnWT "TiltRotatorBucket05Demension;WT";
CM_ SG_ 2566912289 TrttBck05DmsnNQ3 "TiltRotatorBucket05Demension;NQ3";
CM_ SG_ 2566912289 TrttBck05DmsnWQ3 "TiltRotatorBucket05Demension;WQ3";
CM_ SG_ 2566912289 TrttBck05DmsnNQ2 "TiltRotatorBucket05Demension;NQ2";
CM_ SG_ 2566912289 TrttBck05DmsnWQ2 "TiltRotatorBucket05Demension;WQ2";
CM_ SG_ 2566912289 TrttBck05DmsnWidth "TiltRotatorBucket05Demension;Width";
CM_ SG_ 2566912289 TrttBck05DmsnNQ1 "TiltRotatorBucket05Demension;NQ1";
CM_ SG_ 2566912289 TrttBck05DmsnWQ1 "TiltRotatorBucket05Demension;WQ1";
CM_ SG_ 2566912289 TrttBck04DmsnAngVwn "TiltRotatorBucket04Demension;AnlgeVWN";
CM_ SG_ 2566912289 TrttBck04DmsnTN "TiltRotatorBucket04Demension;TN";
CM_ SG_ 2566912289 TrttBck04DmsnWN "TiltRotatorBucket04Demension;WN";
CM_ SG_ 2566912289 TrttBck04DmsnWT "TiltRotatorBucket04Demension;WT";
CM_ SG_ 2566912289 TrttBck04DmsnNQ3 "TiltRotatorBucket04Demension;NQ3";
CM_ SG_ 2566912289 TrttBck04DmsnWQ3 "TiltRotatorBucket04Demension;WQ3";
CM_ SG_ 2566912289 TrttBck04DmsnNQ2 "TiltRotatorBucket04Demension;NQ2";
CM_ SG_ 2566912289 TrttBck04DmsnWQ2 "TiltRotatorBucket04Demension;WQ2";
CM_ SG_ 2566912289 TrttBck04DmsnWidth "TiltRotatorBucket04Demension;Width";
CM_ SG_ 2566912289 TrttBck04DmsnNQ1 "TiltRotatorBucket04Demension;NQ1";
CM_ SG_ 2566912289 TrttBck04DmsnWQ1 "TiltRotatorBucket04Demension;WQ1";
CM_ SG_ 2566912289 TrttBck03DmsnAngVwn "TiltRotatorBucket03Demension;AnlgeVWN";
CM_ SG_ 2566912289 TrttBck03DmsnTN "TiltRotatorBucket03Demension;TN";
CM_ SG_ 2566912289 TrttBck03DmsnWN "TiltRotatorBucket03Demension;WN";
CM_ SG_ 2566912289 TrttBck03DmsnWT "TiltRotatorBucket03Demension;WT";
CM_ SG_ 2566912289 TrttBck03DmsnNQ3 "TiltRotatorBucket03Demension;NQ3";
CM_ SG_ 2566912289 TrttBck03DmsnWQ3 "TiltRotatorBucket03Demension;WQ3";
CM_ SG_ 2566912289 TrttBck03DmsnNQ2 "TiltRotatorBucket03Demension;NQ2";
CM_ SG_ 2566912289 TrttBck03DmsnWQ2 "TiltRotatorBucket03Demension;WQ2";
CM_ SG_ 2566912289 TrttBck03DmsnWidth "TiltRotatorBucket03Demension;Width";
CM_ SG_ 2566912289 TrttBck03DmsnNQ1 "TiltRotatorBucket03Demension;NQ1";
CM_ SG_ 2566912289 TrttBck03DmsnWQ1 "TiltRotatorBucket03Demension;WQ1";
CM_ SG_ 2566912289 TrttBck02DmsnAngVwn "TiltRotatorBucket02Demension;AnlgeVWN";
CM_ SG_ 2566912289 TrttBck02DmsnTN "TiltRotatorBucket02Demension;TN";
CM_ SG_ 2566912289 TrttBck02DmsnWN "TiltRotatorBucket02Demension;WN";
CM_ SG_ 2566912289 TrttBck02DmsnWT "TiltRotatorBucket02Demension;WT";
CM_ SG_ 2566912289 TrttBck02DmsnNQ3 "TiltRotatorBucket02Demension;NQ3";
CM_ SG_ 2566912289 TrttBck02DmsnWQ3 "TiltRotatorBucket02Demension;WQ3";
CM_ SG_ 2566912289 TrttBck02DmsnNQ2 "TiltRotatorBucket02Demension;NQ2";
CM_ SG_ 2566912289 TrttBck02DmsnWQ2 "TiltRotatorBucket02Demension;WQ2";
CM_ SG_ 2566912289 TrttBck02DmsnWidth "TiltRotatorBucket02Demension;Width";
CM_ SG_ 2566912289 TrttBck02DmsnNQ1 "TiltRotatorBucket02Demension;NQ1";
CM_ SG_ 2566912289 TrttBck02DmsnWQ1 "TiltRotatorBucket02Demension;WQ1";
CM_ SG_ 2566912289 TrttBck01DmsnAngVwn "TiltRotatorBucket01Demension;AnlgeVWN";
CM_ SG_ 2566912289 TrttBck01DmsnTN "TiltRotatorBucket01Demension;TN";
CM_ SG_ 2566912289 TrttBck01DmsnWN "TiltRotatorBucket01Demension;WN";
CM_ SG_ 2566912289 TrttBck01DmsnWT "TiltRotatorBucket01Demension;WT";
CM_ SG_ 2566912289 TrttBck01DmsnNQ3 "TiltRotatorBucket01Demension;NQ3";
CM_ SG_ 2566912289 TrttBck01DmsnWQ3 "TiltRotatorBucket01Demension;WQ3";
CM_ SG_ 2566912289 TrttBck01DmsnNQ2 "TiltRotatorBucket01Demension;NQ2";
CM_ SG_ 2566912289 TrttBck01DmsnWQ2 "TiltRotatorBucket01Demension;WQ2";
CM_ SG_ 2566912289 TrttBck01DmsnWidth "TiltRotatorBucket01Demension;Width";
CM_ SG_ 2566912289 TrttBck01DmsnNQ1 "TiltRotatorBucket01Demension;NQ1";
CM_ SG_ 2566912289 TrttBck01DmsnWQ1 "TiltRotatorBucket01Demension;WQ1";
CM_ BO_ 2566912545 "MC Weighing Handshake Group 1";
CM_ SG_ 2566912545 Bck05DmsnAngGdn "Bucket05Demension;AnlgeGDN(theta4)";
CM_ SG_ 2566912545 Bck05DmsnDT "Bucket05Demension;DT";
CM_ SG_ 2566912545 Bck05DmsnNQ3 "Bucket05Demension;NQ3";
CM_ SG_ 2566912545 Bck05DmsnDQ3 "Bucket05Demension;DQ3";
CM_ SG_ 2566912545 Bck05DmsnNQ2 "Bucket05Demension;NQ2";
CM_ SG_ 2566912545 Bck05DmsnDQ2 "Bucket05Demension;DQ2";
CM_ SG_ 2566912545 Bck05DmsnTN "Bucket05Demension;TN";
CM_ SG_ 2566912545 Bck05DmsnWidth "Bucket05Demension;Width";
CM_ SG_ 2566912545 Bck05DmsnNQ1 "Bucket05Demension;NQ1";
CM_ SG_ 2566912545 Bck05DmsnDQ1 "Bucket05Demension;DQ1";
CM_ SG_ 2566912545 Bck05DmsnDN "Bucket05Demension;DN";
CM_ SG_ 2566912545 Bck05DmsnDG "Bucket05Demension;DG";
CM_ SG_ 2566912545 Bck04DmsnAngGdn "Bucket04Demension;AnlgeGDN(theta4)";
CM_ SG_ 2566912545 Bck04DmsnDT "Bucket04Demension;DT";
CM_ SG_ 2566912545 Bck04DmsnNQ3 "Bucket04Demension;NQ3";
CM_ SG_ 2566912545 Bck04DmsnDQ3 "Bucket04Demension;DQ3";
CM_ SG_ 2566912545 Bck04DmsnNQ2 "Bucket04Demension;NQ2";
CM_ SG_ 2566912545 Bck04DmsnDQ2 "Bucket04Demension;DQ2";
CM_ SG_ 2566912545 Bck04DmsnTN "Bucket04Demension;TN";
CM_ SG_ 2566912545 Bck04DmsnWidth "Bucket04Demension;Width";
CM_ SG_ 2566912545 Bck04DmsnNQ1 "Bucket04Demension;NQ1";
CM_ SG_ 2566912545 Bck04DmsnDQ1 "Bucket04Demension;DQ1";
CM_ SG_ 2566912545 Bck04DmsnDN "Bucket04Demension;DN";
CM_ SG_ 2566912545 Bck04DmsnDG "Bucket04Demension;DG";
CM_ SG_ 2566912545 Bck03DmsnAngGdn "Bucket03Demension;AnlgeGDN(theta4)";
CM_ SG_ 2566912545 Bck03DmsnDT "Bucket03Demension;DT";
CM_ SG_ 2566912545 Bck03DmsnNQ3 "Bucket03Demension;NQ3";
CM_ SG_ 2566912545 Bck03DmsnDQ3 "Bucket03Demension;DQ3";
CM_ SG_ 2566912545 Bck03DmsnNQ2 "Bucket03Demension;NQ2";
CM_ SG_ 2566912545 Bck03DmsnDQ2 "Bucket03Demension;DQ2";
CM_ SG_ 2566912545 Bck03DmsnTN "Bucket03Demension;TN";
CM_ SG_ 2566912545 Bck03DmsnWidth "Bucket03Demension;Width";
CM_ SG_ 2566912545 Bck03DmsnNQ1 "Bucket03Demension;NQ1";
CM_ SG_ 2566912545 Bck03DmsnDQ1 "Bucket03Demension;DQ1";
CM_ SG_ 2566912545 Bck03DmsnDN "Bucket03Demension;DN";
CM_ SG_ 2566912545 Bck03DmsnDG "Bucket03Demension;DG";
CM_ SG_ 2566912545 Bck02DmsnAngGdn "Bucket02Demension;AnlgeGDN(theta4)";
CM_ SG_ 2566912545 Bck02DmsnDT "Bucket02Demension;DT";
CM_ SG_ 2566912545 Bck02DmsnNQ3 "Bucket02Demension;NQ3";
CM_ SG_ 2566912545 Bck02DmsnDQ3 "Bucket02Demension;DQ3";
CM_ SG_ 2566912545 Bck02DmsnNQ2 "Bucket02Demension;NQ2";
CM_ SG_ 2566912545 Bck02DmsnDQ2 "Bucket02Demension;DQ2";
CM_ SG_ 2566912545 Bck02DmsnTN "Bucket02Demension;TN";
CM_ SG_ 2566912545 Bck02DmsnWidth "Bucket02Demension;Width";
CM_ SG_ 2566912545 Bck02DmsnNQ1 "Bucket02Demension;NQ1";
CM_ SG_ 2566912545 Bck02DmsnDQ1 "Bucket02Demension;DQ1";
CM_ SG_ 2566912545 Bck02DmsnDN "Bucket02Demension;DN";
CM_ SG_ 2566912545 Bck02DmsnDG "Bucket02Demension;DG";
CM_ SG_ 2566912545 Bck01DmsnAngGdn "Bucket01Demension;AnlgeGDN(theta4)";
CM_ SG_ 2566912545 Bck01DmsnDT "Bucket01Demension;DT";
CM_ SG_ 2566912545 Bck01DmsnNQ3 "Bucket01Demension;NQ3";
CM_ SG_ 2566912545 Bck01DmsnDQ3 "Bucket01Demension;DQ3";
CM_ SG_ 2566912545 Bck01DmsnNQ2 "Bucket01Demension;NQ2";
CM_ SG_ 2566912545 Bck01DmsnDQ2 "Bucket01Demension;DQ2";
CM_ SG_ 2566912545 Bck01DmsnTN "Bucket01Demension;TN";
CM_ SG_ 2566912545 Bck01DmsnWidth "Bucket01Demension;Width";
CM_ SG_ 2566912545 Bck01DmsnNQ1 "Bucket01Demension;NQ1";
CM_ SG_ 2566912545 Bck01DmsnDQ1 "Bucket01Demension;DQ1";
CM_ SG_ 2566912545 Bck01DmsnDN "Bucket01Demension;DN";
CM_ SG_ 2566912545 Bck01DmsnDG "Bucket01Demension;DG";
CM_ BO_ 2566912801 "MC Weighing Handshake Group 2";
CM_ SG_ 2566912801 DacCoordinateSystem "??;SetDACCoordinateSystem";
CM_ SG_ 2566912801 DacAutoMdSelect "CMD;DACAutoModeSelect";
CM_ SG_ 2566912801 CrwTipCalbLen "CrawlerTipCalibrationLength";
CM_ SG_ 2566912801 ImuSsOfsBladeRoll "IMUSensorOffset;Blade�Roll";
CM_ SG_ 2566912801 ImuSsOfsBladePch "IMUSensorOffset;BladePitch";
CM_ SG_ 2566912801 ImuSsOfsCfrmRoll "IMUSensorOffset;C-frameRoll";
CM_ SG_ 2566912801 ImuSsOfsCfrmPch "IMUSensorOffset;C-framePitch";
CM_ SG_ 2566912801 BladeTipCalbLen "Bladetipcalibrationlength";
CM_ SG_ 2566912801 BladeJointCalbLen "BladeJointCalibrationLength";
CM_ SG_ 2566912801 GrdAstPrfDsnDt01PntZ09 "GradeAssistProfileDesignData01;PointZ09";
CM_ SG_ 2566912801 GrdAstPrfDsnDt01PntY09 "GradeAssistProfileDesignData01;PointY09";
CM_ SG_ 2566912801 GrdAstPrfDsnDt01PntZ08 "GradeAssistProfileDesignData01;PointZ08";
CM_ SG_ 2566912801 GrdAstPrfDsnDt01PntY08 "GradeAssistProfileDesignData01;PointY08";
CM_ SG_ 2566912801 GrdAstPrfDsnDt01PntZ07 "GradeAssistProfileDesignData01;PointZ07";
CM_ SG_ 2566912801 GrdAstPrfDsnDt01PntY07 "GradeAssistProfileDesignData01;PointY07";
CM_ SG_ 2566912801 GrdAstPrfDsnDt01PntZ06 "GradeAssistProfileDesignData01;PointZ06";
CM_ SG_ 2566912801 GrdAstPrfDsnDt01PntY06 "GradeAssistProfileDesignData01;PointY06";
CM_ SG_ 2566912801 GrdAstPrfDsnDt01PntZ05 "GradeAssistProfileDesignData01;PointZ05";
CM_ SG_ 2566912801 GrdAstPrfDsnDt01PntY05 "GradeAssistProfileDesignData01;PointY05";
CM_ SG_ 2566912801 GrdAstPrfDsnDt01PntZ04 "GradeAssistProfileDesignData01;PointZ04";
CM_ SG_ 2566912801 GrdAstPrfDsnDt01PntY04 "GradeAssistProfileDesignData01;PointY04";
CM_ SG_ 2566912801 GrdAstPrfDsnDt01PntZ03 "GradeAssistProfileDesignData01;PointZ03";
CM_ SG_ 2566912801 GrdAstPrfDsnDt01PntY03 "GradeAssistProfileDesignData01;PointY03";
CM_ SG_ 2566912801 GrdAstPrfDsnDt01PntZ02 "GradeAssistProfileDesignData01;PointZ02";
CM_ SG_ 2566912801 GrdAstPrfDsnDt01PntY02 "GradeAssistProfileDesignData01;PointY02";
CM_ SG_ 2566912801 GrdAstPrfDsnDt01PntZ01 "GradeAssistProfileDesignData01;PointZ01";
CM_ SG_ 2566912801 GrdAstPrfDsnDt01PntY01 "GradeAssistProfileDesignData01;PointY01";
CM_ SG_ 2566912801 CrossSlopeDsnDt "CrossSlopeDesignData";
CM_ SG_ 2566912801 SlopeDsnDt "SlopeDesignData";
CM_ SG_ 2566912801 DepthDsnDt "DepthDesignData";
CM_ SG_ 2566912801 JoyFuncAssnRhThmbWhl05 "JoystickFunctionAssign;R.H.ThumbWheel05";
CM_ SG_ 2566912801 JoyFuncAssnRhThmbWhl04 "JoystickFunctionAssign;R.H.ThumbWheel04";
CM_ SG_ 2566912801 JoyFuncAssnRhThmbWhl03 "JoystickFunctionAssign;R.H.ThumbWheel03";
CM_ SG_ 2566912801 JoyFuncAssnRhThmbWhl02 "JoystickFunctionAssign;R.H.ThumbWheel02";
CM_ SG_ 2566912801 JoyFuncAssnRhThmbWhl01 "JoystickFunctionAssign;R.H.ThumbWheel01";
CM_ SG_ 2566912801 JoyFuncAssnLhThmbWhl05 "JoystickFunctionAssign;L.H.ThumbWheel05";
CM_ SG_ 2566912801 JoyFuncAssnLhThmbWhl04 "JoystickFunctionAssign;L.H.ThumbWheel04";
CM_ SG_ 2566912801 JoyFuncAssnLhThmbWhl03 "JoystickFunctionAssign;L.H.ThumbWheel03";
CM_ SG_ 2566912801 JoyFuncAssnLhThmbWhl02 "JoystickFunctionAssign;L.H.ThumbWheel02";
CM_ SG_ 2566912801 JoyFuncAssnLhThmbWhl01 "JoystickFunctionAssign;L.H.ThumbWheel01";
CM_ SG_ 2566912801 JoyFuncAssnRhBtn10 "JoystickFunctionAssign;R.H.Button10";
CM_ SG_ 2566912801 JoyFuncAssnRhBtn09 "JoystickFunctionAssign;R.H.Button09";
CM_ SG_ 2566912801 JoyFuncAssnRhBtn08 "JoystickFunctionAssign;R.H.Button08";
CM_ SG_ 2566912801 JoyFuncAssnRhBtn07 "JoystickFunctionAssign;R.H.Button07";
CM_ SG_ 2566912801 JoyFuncAssnRhBtn06 "JoystickFunctionAssign;R.H.Button06";
CM_ SG_ 2566912801 JoyFuncAssnRhBtn05 "JoystickFunctionAssign;R.H.Button05";
CM_ SG_ 2566912801 JoyFuncAssnRhBtn04 "JoystickFunctionAssign;R.H.Button04";
CM_ SG_ 2566912801 JoyFuncAssnRhBtn03 "JoystickFunctionAssign;R.H.Button03";
CM_ SG_ 2566912801 JoyFuncAssnRhBtn02 "JoystickFunctionAssign;R.H.Button02";
CM_ SG_ 2566912801 JoyFuncAssnRhBtn01 "JoystickFunctionAssign;R.H.Button01";
CM_ SG_ 2566912801 JoyFuncAssnLhBtn10 "JoystickFunctionAssign;L.H.Button10";
CM_ SG_ 2566912801 JoyFuncAssnLhBtn09 "JoystickFunctionAssign;L.H.Button09";
CM_ SG_ 2566912801 JoyFuncAssnLhBtn08 "JoystickFunctionAssign;L.H.Button08";
CM_ SG_ 2566912801 JoyFuncAssnLhBtn07 "JoystickFunctionAssign;L.H.Button07";
CM_ SG_ 2566912801 JoyFuncAssnLhBtn06 "JoystickFunctionAssign;L.H.Button06";
CM_ SG_ 2566912801 JoyFuncAssnLhBtn05 "JoystickFunctionAssign;L.H.Button05";
CM_ SG_ 2566912801 JoyFuncAssnLhBtn04 "JoystickFunctionAssign;L.H.Button04";
CM_ SG_ 2566912801 JoyFuncAssnLhBtn03 "JoystickFunctionAssign;L.H.Button03";
CM_ SG_ 2566912801 JoyFuncAssnLhBtn02 "JoystickFunctionAssign;L.H.Button02";
CM_ SG_ 2566912801 JoyFuncAssnLhBtn01 "JoystickFunctionAssign;L.H.Button01";
CM_ SG_ 2566912801 ImuSsOfsBucket "IMUSensorOffset;Bucket";
CM_ SG_ 2566912801 ImuSsOfsArtiArmPch "IMUSensorOffset;ArtiArmPitch";
CM_ SG_ 2566912801 ImuSsOfsArmPch "IMUSensorOffset;ArmPitch";
CM_ SG_ 2566912801 ImuSsOfsBoomPch "IMUSensorOffset;BoomPitch";
CM_ SG_ 2566912801 ImuSsOfsBodyRoll "IMUSensorOffset;BodyRoll";
CM_ SG_ 2566912801 ImuSsOfsBodyPch "IMUSensorOffset;BodyPitch";
CM_ SG_ 2566912801 SelectedBucketNo "SelectedBucketNumber";
CM_ BO_ 2566913057 "MC Weighing Handshake Group 3";
CM_ SG_ 2566913057 MaterialName "MaterialName";
CM_ SG_ 2566913057 TrkName "TruckName";
CM_ SG_ 2566913057 BchmkZOfs "BenchmarkZOffset";
CM_ SG_ 2566913057 BchmkYOfs "BenchmarkYOffset";
CM_ SG_ 2566913057 BchmkXOfs "BenchmarkXOffset";
CM_ SG_ 2566913057 TrkCount "TruckCount";
CM_ SG_ 2566913057 SelMaterialDensity "SelectedMaterialDensity";
CM_ SG_ 2566913057 SelTrkTgtWgh "SelectedTruckTargetWeight";
CM_ SG_ 2566913057 BckRefPnt "BucketReferencePoint";
CM_ SG_ 2566913057 ArtiBoomDmsnOpt "Opt??;ArtiBoomDemensionOption";
CM_ SG_ 2566913057 ArmDmsnOpt "Opt??;ArmDemensionOption";
CM_ SG_ 2566913057 BoomDmsnOpt "Opt??;BoomDemensionOption";
CM_ SG_ 2566913057 GrdAstMd "GradeAssistMode";
CM_ SG_ 2566913057 GrdAstAccuracy "GradeAssistAccuracy";
CM_ SG_ 2566913057 TrkShoeWidth "TrackShoeWidth";
CM_ BO_ 2566913313 "MC Weighing Target Set Value";
CM_ SG_ 2566913313 SwgAstAngTgtSetSwgLh "SwingAssistAngleTargetSet;SwingLeft";
CM_ SG_ 2566913313 SwgAstAngTgtSetSwgRh "SwingAssistAngleTargetSet;SwingRight";
CM_ SG_ 2566913313 EfenceTgtSetSwgRh "E-FenceTargetSet;SwingRight";
CM_ SG_ 2566913313 EfenceTgtSetSwgLh "E-FenceTargetSet;SwingLeft";
CM_ SG_ 2566913313 EfenceTgtSetCeil "E-FenceTargetSet;Ceiling";
CM_ SG_ 2566913313 EfenceTgtSetFloor "E-FenceTargetSet;Floor";
CM_ SG_ 2566913313 EfenceTgtSetWall "E-FenceTargetSet;Wall";
CM_ BO_ 2566913569 "MC Truck Store Information";
CM_ SG_ 2566913569 MaterialLoadSt "MaterialsLoadingStatus";
CM_ SG_ 2566913569 TotWghCurtrk "TotalWeightofcurrenttruck";
CM_ SG_ 2566913569 BckCntCurtrk "BucketCountofcurrenttruck";
CM_ SG_ 2566913569 SelMaterialDensity "SelectedMaterialDensity";
CM_ SG_ 2566913569 MaterialName "MaterialName";
CM_ SG_ 2566913569 TrkName "TruckName";
CM_ BO_ 2566913825 "MC Accumulated Weighing Information";
CM_ SG_ 2566913825 TotAcmtWgh "TotalAccumulatedWeight";
CM_ SG_ 2566913825 TotAcmtBckCnt "TotalAccumulatedBucketCount";
CM_ BO_ 2583646241 "Front Pump Spool Stroke Command";
CM_ SG_ 2583646241 TrvlLhSpoolCmd "Travelleftspoolcommnad";
CM_ SG_ 2583646241 ArmConfSpoolCmd "Armconfluencespoolcommand";
CM_ SG_ 2583646241 BckSpoolCmd "Bucketspoolcommand";
CM_ SG_ 2583646241 BoomSpoolCmd "Boomspoolcommand";
CM_ BO_ 2583646497 "Rear Pump Spool Stroke Command";
CM_ SG_ 2583646497 TrvlrightSpoolCmd "Travelrightspoolcommnad";
CM_ SG_ 2583646497 BoomConfSpoolCmd "Boomconfluencespoolcommand";
CM_ SG_ 2583646497 SwgSpoolCmd "Swingspoolcommand";
CM_ SG_ 2583646497 ArmSpoolCmd "Armspoolcommand";
CM_ BO_ 2583646753 "Option Spool Stroke Command";
CM_ SG_ 2583646753 ArtiBoomConfSpoolCmd "Artiboomconfluencespoolcommand";
CM_ SG_ 2583646753 DzSpoolCmd "Dozerspoolcommand";
CM_ SG_ 2583646753 OptSpoolCmd "Optionspoolcommand";
CM_ BO_ 2583651424 "Front Pump Delayed Spool Stroke Command";
CM_ SG_ 2583651424 TrvlleftSplDlyCmd "Travelleftspooldelayedcommnad";
CM_ SG_ 2583651424 BckSplDlyCmd "Bucketspooldelayedcommand";
CM_ SG_ 2583651424 ArmCnfSplDlyCmd "Armconfluencespooldelayedcommand";
CM_ SG_ 2583651424 BoomSplDlyCmd "Boomspooldelayedcommand";
CM_ BO_ 2583651680 "Rear Pump Delayed Spool Stroke Command";
CM_ SG_ 2583651680 TrvlrightSplDlyCmd "Travelrightspooldelayedcommnad";
CM_ SG_ 2583651680 SwgSplDlyCmd "Swingspooldelayedcommand";
CM_ SG_ 2583651680 BoomCnfSplDlyCmd "Boomconfluencespooldelayedcommand";
CM_ SG_ 2583651680 ArmSplDlyCmd "Armspooldelayedcommand";
CM_ BO_ 2583651936 "Option Delayed Spool Stroke Command";
CM_ SG_ 2583651936 ArtiboomSplDlyCmd "Artiboomspooldelayedcommand";
CM_ SG_ 2583651936 DzSplDlyCmd "Dozerspooldelayedcommand";
CM_ SG_ 2583651936 OptSplDlyCmd "Optionspooldelayedcommand";
CM_ BO_ 2583654752 "Boom Bucket EPPR Feedback Current";
CM_ SG_ 2583654752 BckdumpEpprFdbkCur "Bucketdumpepprfeedbackcurrent";
CM_ SG_ 2583654752 BckcrowdEpprFdbkCur "Bucketcrowdepprfeedbackcurrent";
CM_ SG_ 2583654752 BoomDnEpprFdbkCur "Boomdownepprfeedbackcurrent";
CM_ SG_ 2583654752 BoomupEpprFdbkCur "Boomupepprfeedbackcurrent";
CM_ BO_ 2583655008 "Arm Swing EPPR Feedback Current";
CM_ SG_ 2583655008 SwgREpprFdbkCur "Swingrightepprfeedbackcurrent";
CM_ SG_ 2583655008 SwgLEpprFdbkCur "Swingleftepprfeedbackcurrent";
CM_ SG_ 2583655008 ArmdumpEpprFdbkCur "Armdumpepprfeedbackcurrent";
CM_ SG_ 2583655008 ArmcrowdEpprFdbkCur "Armcrowdepprfeedbackcurrent";
CM_ BO_ 2583655264 "Confluence EPPR Feedback Current";
CM_ SG_ 2583655264 ArmCnfdumpEpprFdbkCur "Armconfluencedumpepprfeedbackcurrent";
CM_ SG_ 2583655264 ArmCnfcrowdEpprFdbkCur "Armconfluencecrowdepprfeedbackcurrent";
CM_ SG_ 2583655264 BoomCnfEpprFdbkCur "Boomconfluenceepprfeedbackcurrent";
CM_ BO_ 2583655520 "Option EPPR Feedback Current";
CM_ SG_ 2583655520 OpenEpprFdbkCur "Openepprfeedbackcurrent";
CM_ SG_ 2583655520 CloseEpprFdbkCur "Closeepprfeedbackcurrent";
CM_ BO_ 2583655776 "Travel EPPR Feedback Current";
CM_ SG_ 2583655776 TrvlRBwdEpprFdbkCur "Travelrightbackwardepprfeedbackcurrent";
CM_ SG_ 2583655776 TrvlRFwdEpprFdbkCur "Travelrightforwardepprfeedbackcurrent";
CM_ SG_ 2583655776 TrvlLBwdEpprFdbkCur "Travelleftbackwardepprfeedbackcurrent";
CM_ SG_ 2583655776 TrvlLFwdEpprFdbkCur "Travelleftforwardepprfeedbackcurrent";
CM_ BO_ 2583656032 "Boom Bucket Head Rod Pressure";
CM_ SG_ 2583656032 BckCylrodPrs "Bucketcylinderrodpressure";
CM_ SG_ 2583656032 BckCylheadPrs "Bucketcylinderheadpressure";
CM_ SG_ 2583656032 BoomCylrodPrs "Boomcylinderrodpressure";
CM_ SG_ 2583656032 BoomCylheadPrs "Boomcylinderheadpressure";
CM_ BO_ 2583656288 "Arm Head Rod Pressure";
CM_ SG_ 2583656288 ArmCylrodPrs "Armcylinderrodpressure";
CM_ SG_ 2583656288 ArmCylheadPrs "Armcylinderheadpressure";
CM_ BO_ 2583656544 "Cylinder Pressure Sensor FMI";
CM_ SG_ 2583656544 BckCylrodPrsSsFmi "BucketcylinderrodpressuresensorFMI";
CM_ SG_ 2583656544 BckCylheadPrsSsFmi "BucketcylinderheadpressuresensorFMI";
CM_ SG_ 2583656544 ArmCylrodPrsSsFmi "ArmcylinderrodpressuresensorFMI";
CM_ SG_ 2583656544 ArmCylheadPrsSsFmi "ArmcylinderheadpressuresensorFMI";
CM_ SG_ 2583656544 BoomCylrodPrsSsFmi "BoomcylinderrodpressuresensorFMI";
CM_ SG_ 2583656544 BoomCylheadPrsSsFmi "BoomcylinderheadpressuresensorFMI";
CM_ BO_ 2583656800 "Valve Pilot Pressure";
CM_ SG_ 2583656800 PtPltPrs "Ptpilotpressure";
CM_ SG_ 2583656800 PaPltPrs "Papilotpressure";
CM_ SG_ 2583656800 BckcrowdEpprPltPrs "Bucketcrowdepprpilotpressure";
CM_ SG_ 2583656800 ArmcrowdEpprPltPrs "Armcrowdepprpilotpressure";
CM_ SG_ 2583656800 BoomDnEpprPltPrs "Boomdownepprpilotpressure";
CM_ BO_ 2583657056 "Valve Pilot Pressure Senaor FMI";
CM_ SG_ 2583657056 PtPltPrsSsFmi "PtpilotpressuresensorFMI";
CM_ SG_ 2583657056 PaPltPrsSsFmi "PapilotpressuresensorFMI";
CM_ SG_ 2583657056 BckcrowdEpprPltPrsSsFmi "BucketcrowdepprpilotpressuresensorFMI";
CM_ SG_ 2583657056 ArmcrowdEpprPltPrsSsFmi "ArmcrowdepprpilotpressuresensorFMI";
CM_ SG_ 2583657056 BoomDnEpprPltPrsSsFmi "BoomdownepprpilotpressuresensorFMI";
CM_ BO_ 2583657312 "Pilot Cutoff State";
CM_ SG_ 2583657312 PltCutoffsolVvFmi "PilotcutoffsolvalveFMI";
CM_ SG_ 2583657312 PltCutoffsolVvCmd "Pilotcutoffsolvalvecommand";
CM_ SG_ 2583657312 PltCutoffsolVvswst "Pilotcutoffsolvalveswitchstate";
CM_ BO_ 2583667233 "Center Bypass Current Command";
CM_ BO_ 2583683873 "Front Joystick Pilot Pressure";
CM_ BO_ 2583684129 "Travel Joystick Pilot Pressure";
CM_ BO_ 2583684385 "VBO Flow Data";
CM_ BO_ 2583684641 "VBO Pump1 Data";
CM_ BO_ 2583684897 "VBO Pump2 Data";
CM_ BO_ 2583685153 "VBO Torque Data";
CM_ SG_ 2583685153 RefPowShftEnb "ReferencevalueforPowershiftenable";
CM_ SG_ 2583685153 PmpActTrq "Pumpactualtorque";
CM_ SG_ 2583685153 PmpCmdTrq "Pumpcommandtorque";
CM_ SG_ 2583685153 TrqCmdLever "Torquecommandvialever";
CM_ SG_ 2583685153 TrqCmdLmt "Torquecommandlimit";
CM_ SG_ 2583685153 PidCtrlResult "PIDcontrolresult";
CM_ SG_ 2583685153 TrqCmdTrqCtrl "Torquecommandviatorquecontrol";
CM_ SG_ 2583685153 TrqCmdPowShftCtrl "Torquecommandviapowershiftcontrol";
CM_ BO_ 2583685409 "VBO Spool  Feedback Current  ";
CM_ SG_ 2583685409 Bypass2SpoolEpprFdbkCur "Bypass2spoolepprfeedbackcurrent";
CM_ SG_ 2583685409 Bypass1SpoolEpprFdbkCur "Bypass1spoolepprfeedbackcurrent";
CM_ SG_ 2583685409 Boom2SpoolEpprFdbkCur "Boom2spoolepprfeedbackcurrent";
CM_ SG_ 2583685409 Bck2SpoolEpprFdbkCur "Bucket2spoolepprfeedbackcurrent";
CM_ SG_ 2583685409 Arm2SpoolEpprFdbkCur "Arm2spoolepprfeedbackcurrent";
CM_ SG_ 2583685409 ArmLckSpoolEpprFdbkCur "Armlockspoolepprfeedbackcurrent";
CM_ BO_ 2583685665 "VBO Spool Pilot Pressure   ";
CM_ SG_ 2583685665 BoomConfSpoolPilotPrs "Boomconfluencespoolpilotpressure";
CM_ SG_ 2583685665 BckConfSpoolPilotPrs "Bucketconfluencespoolpilotpressure";
CM_ SG_ 2583685665 ArmConfSpoolPilotPrs "Armconfluencespoolpilotpressure";
CM_ SG_ 2583685665 ArmLckSpoolPilotPrs "Armlockspoolpilotpressure";
CM_ BO_ 2583685921 "VBO Pump Angle Data";
CM_ SG_ 2583685921 ReaRpmpEpprFdbkCur "RearpumpEPPRfeedbackcurrent";
CM_ SG_ 2583685921 FrPmpEpprFdbkCur "FrontpumpEPPRfeedbackcurrent";
CM_ SG_ 2583685921 FrPmpAngVlt "Frontpumpanglevoltage";
CM_ SG_ 2583685921 ReaRpmpAngVlt "Rearpumpanglevoltage";
CM_ BO_ 2583686177 "Vbo Temperature Data  ";
CM_ SG_ 2583686177 FrPmpAngVlt "Frontpumpanglevoltage";
CM_ SG_ 2583686177 OilFanEpprFdbkCur "OilfanEPPRfeedbackcurrent";
CM_ BO_ 2583686433 "VBO Virtual Qa Data  ";
CM_ SG_ 2583686433 Pmp2flowandCmdDev "Pump2flowandcommanddeviation";
CM_ SG_ 2583686433 Pmp1flowandCmdDev "Pump1flowandcommanddeviation";
CM_ SG_ 2583686433 Pmp2VirQa "Pump2virtualQa";
CM_ SG_ 2583686433 Pmp1VirQa "Pump1virtualQa";
CM_ BO_ 2382360307 "PG TR Attachment Dimension Message 2";
CM_ BO_ 2382360563 "PG TR Attachment Dimension Message 1";
CM_ BO_ 2382360819 "PG Tool Attachment Information Message 1";
CM_ BO_ 2382361075 "PG TR Attachment Information Message 1";
CM_ BO_ 2382361331 "PG TR Sensor Information Message 1";
CM_ BO_ 2382361587 "PG TR Rotation Sensor Data Message 1";
CM_ BO_ 2382361843 "PG TR Tilt Sensor Data Message 1";
CM_ BO_ 2382362867 "PG Attachment Function Information Message 1";
CM_ BO_ 2382363123 "PG Attachment Lock Control Message 1";
CM_ BO_ 2382363379 "PG Auxiliary Hydraulic Control Message 1";
CM_ BO_ 2382363681 "PG Excavator Information Message 1";
CM_ BO_ 2382364193 "PG Attachment Control Message 2";
CM_ BO_ 2382364449 "PG Attachment Control Message 1";
CM_ BO_ 2566842442 "Vehicle Direction/Speed";
CM_ SG_ 2566842442 Pitch "Pitch(Reserved)";
CM_ SG_ 2566842442 Spd "Navigation-BasedVehicleSpeed";
CM_ BO_ 2566845258 "Vehicle Position 1 (1s)";
CM_ BO_ 2583642954 "Digital Keyless Login";
CM_ SG_ 2583642954 Dkey "Digital Key Selected";
CM_ SG_ 2583642954 SelType "Select Type";
CM_ BO_ 2583643210 "Digital Key List Unregistered";
CM_ SG_ 2583643210 DkeyList "DigitalKeyListInformation";
CM_ BO_ 2583643466 "Digital Key Total List Registered";
CM_ BO_ 2583642186 "Telematics Information";
CM_ BO_ 2583642442 "Machine Provisioning Information";
CM_ SG_ 2583642442 MpSt "Machine Provisioning Status";
CM_ SG_ 2583642442 TguId "Terminal Serial Number";
CM_ SG_ 2583642442 Sname "Machine Sales Name";
CM_ SG_ 2583642442 Pname "Machine Project Name";
CM_ SG_ 2583642442 Vin "Vehicle Identification Number";
CM_ SG_ 2583642442 MchType "Machine Type";
CM_ SG_ 2583642442 Oem "OEM / Seller / Reseller";
CM_ SG_ 2583642442 Mch "Machine Asset ID";
CM_ BO_ 2583642698 "Telematics Cellular Network Information";
CM_ SG_ 2583642698 NetNm "Network Provider Name";
CM_ SG_ 2583642698 Rssi "Received Signal Strength Indicator";
CM_ SG_ 2583642698 Type "Type";
CM_ SG_ 2583642698 Con "Cloud Connected";
CM_ BO_ 2583642401 "Machine Provisioning Information";
CM_ SG_ 2583642401 MpSt "Machine Provisioning Status";
CM_ SG_ 2583642401 TguId "Terminal Serial Number";
CM_ SG_ 2583642401 Sname "Machine Sales Name";
CM_ SG_ 2583642401 Pname "Machine Project Name";
CM_ SG_ 2583642401 Vin "Vehicle Identification Number";
CM_ SG_ 2583642401 MchType "Machine Type";
CM_ SG_ 2583642401 Oem "OEM / Seller / Reseller";
CM_ SG_ 2583642401 Mch "Machine Asset ID";
CM_ BO_ 2583662698 "PHM Warning Group";
CM_ SG_ 2583662698 WarnPopEgOilQual "Warning Pop-up; PHM - Engine Oil Quality ";
CM_ SG_ 2583662698 WarnPopHyhOilQual "Warning Pop-up; PHM - Hydraulic Oil Quality ";
CM_ BO_ 2583666538 "Threshold of Hydraulic Oil";
CM_ SG_ 2583666538 LwThKnmtVcstyofHyhOil "Lower Threshold Kinematic Viscosity of Hydraulic Oil";
CM_ SG_ 2583666538 UpThKnmtVcstyofHyhOil "Upper Threshold Kinematic Viscosity of Hydraulic Oil";
CM_ SG_ 2583666538 LwThDielecCstofHyhOil "Lower Threshold Dieletric Constant of Hydraulic Oil";
CM_ SG_ 2583666538 UpThDielecCstofHyhOil "Upper Threshold Dieletric Constant of Hydraulic Oil";
CM_ BO_ 2583666794 "Threshold of Engine Oil";
CM_ SG_ 2583666794 LwThKnmtVcstyofEgOil "Lower Threshold Kinematic Viscosity of Engine Oil";
CM_ SG_ 2583666794 UpThKnmtVcstyofEgOil "Upper Threshold Kinematic Viscosity of Engine Oil";
CM_ SG_ 2583666794 LwThDielecCstofEgOil "Lower Threshold Dieletric Constant of Engine Oil";
CM_ SG_ 2583666794 UpThDielecCstofEgOil "Upper Threshold Dieletric Constant of Engine Oil";
CM_ BO_ 2583667050 "Kinematic Viscosity of Oil";
CM_ SG_ 2583667050 KnmtVcstyofEgOil "Kinematic Viscosity of Engine Oil";
CM_ SG_ 2583667050 KnmtVcstyofHyhOil "Kinematic Viscosity of Hydraulic Oil";
CM_ BO_ 2583662881 "EPOS CAN Data for PHM1";
CM_ SG_ 2583662881 AccPdlVlt "[??] ?? ?? ?? (?)";
CM_ SG_ 2583662881 CtlEgCtrlDialVlt "[???] ?? ??? ??? ?? [???]";
CM_ SG_ 2583662881 FlwCtrlLeverRh "[???] ?? ???? ? ?? (Flow Control Lever RH)";
CM_ SG_ 2583662881 FlwCtrlLeverLh "[???] ?? ???? ? ?? (Flow Control Lever LH)";
CM_ BO_ 2583663137 "EPOS CAN Data for PHM2";
CM_ SG_ 2583663137 WifSsVlt "[??] ?? ? ?? ?? (WIF Sensor) ??";
CM_ SG_ 2583663137 VhcTrvlSpdSsFreq "[??] ?? ?? ?? ??";
CM_ SG_ 2583663137 AltVlt "[??] ????? ??";
CM_ SG_ 2583663137 BatVlt "[??] ??? ?? [???]";
CM_ BO_ 2583663393 "EPOS CAN Data for PHM3";
CM_ SG_ 2583663393 BckdumpEpprFdbkCur "Bucket dump eppr feedback current";
CM_ SG_ 2583663393 BckcrowdEpprFdbkCur "Bucket crowd eppr feedback current";
CM_ SG_ 2583663393 BoomDnEpprFdbkCur "Boom down eppr feedback current";
CM_ SG_ 2583663393 BoomupEpprFdbkCur "Boom up eppr feedback current";
CM_ BO_ 2583663649 "EPOS CAN Data for PHM4";
CM_ SG_ 2583663649 SwgREpprFdbkCur "Swing right eppr feedback current";
CM_ SG_ 2583663649 SwgLEpprFdbkCur "Swing left eppr feedback current";
CM_ SG_ 2583663649 ArmdumpEpprFdbkCur "Arm dump eppr feedback current";
CM_ SG_ 2583663649 ArmcrowdEpprFdbkCur "Arm crowd eppr feedback current";
CM_ BO_ 2583663905 "EPOS CAN Data for PHM5";
CM_ SG_ 2583663905 ArmCnfdumpEpprFdbkCur "Arm confluence dump eppr feedback current";
CM_ SG_ 2583663905 ArmCnfcrowdEpprFdbkCur "Arm confluence crowd eppr feedback current";
CM_ SG_ 2583663905 BoomCnfEpprFdbkCur "Boom confluence eppr feedback current";
CM_ BO_ 2583664161 "EPOS CAN Data for PHM6";
CM_ SG_ 2583664161 TrvlRBwdEpprFdbkCur "Travel right backward  eppr feedback current";
CM_ SG_ 2583664161 TrvlRFwdEpprFdbkCur "Travel right forward  eppr feedback current";
CM_ SG_ 2583664161 TrvlLBwdEpprFdbkCur "Travel left backward  eppr feedback current";
CM_ SG_ 2583664161 TrvlLFwdEpprFdbkCur "Travel left forward eppr feedback current";
CM_ BO_ 2583664417 "EPOS CAN Data for PHM7";
CM_ SG_ 2583664417 BckCylrodPrs "Bucket cylinder rod pressure";
CM_ SG_ 2583664417 BckCylheadPrs "Bucket cylinder head pressure";
CM_ SG_ 2583664417 BoomCylrodPrs "Boom cylinder rod pressure";
CM_ SG_ 2583664417 BoomCylheadPrs "Boom cylinder head pressure";
CM_ BO_ 2583664673 "EPOS CAN Data for PHM8";
CM_ SG_ 2583664673 ArmCylrodPrs "Arm cylinder rod pressure";
CM_ SG_ 2583664673 ArmCylheadPrs "Arm cylinder head pressure";
CM_ SG_ 2583664673 OpenEpprFdbkCur "Open eppr feedback current";
CM_ SG_ 2583664673 CloseEpprFdbkCur "Close eppr feedback current";
CM_ BO_ 2583664929 "EPOS CAN Data for PHM9";
CM_ SG_ 2583664929 TrvlRStrkPltPrs "Travel right stroke pilot pressure";
CM_ SG_ 2583664929 TrvlLStrkPltPrs "Travel left stroke pilot pressure";
CM_ SG_ 2583664929 PtPltPrs "Pt pilot pressure";
CM_ SG_ 2583664929 PaPltPrs "Pa pilot pressure";
CM_ SG_ 2583664929 BckcrowdEpprPltPrs "Bucket crowd eppr pilot pressure";
CM_ SG_ 2583664929 ArmcrowdEpprPltPrs "Arm crowd eppr pilot pressure";
CM_ SG_ 2583664929 BoomDnEpprPltPrs "Boom down eppr pilot pressure";
CM_ BO_ 2583665185 "EPOS CAN Data for PHM10";
CM_ SG_ 2583665185 Pmp2ActFlw "Pump2 actual flow";
CM_ SG_ 2583665185 Pmp1ActFlw "Pump1 actual flow";
CM_ SG_ 2583665185 Pmp2FlwCmd "Pump2 flow command";
CM_ SG_ 2583665185 Pmp1FlwCmd "Pump1 flow command";
CM_ SG_ 2583665185 Pmp2ReqrFlw "Pump2 required flow";
CM_ SG_ 2583665185 Pmp1ReqrFlw "Pump1 required flow";
CM_ BO_ 2583665441 "EPOS CAN Data for PHM11";
CM_ SG_ 2583665441 SwgStrkPltPrs "Swing stroke pilot pressure";
CM_ SG_ 2583665441 ArmdumpStrkPltPrs "Arm dump stroke pilot pressure";
CM_ SG_ 2583665441 ArmcrowdStrkPltPrs "Arm crowd stroke pilot pressure";
CM_ SG_ 2583665441 BckdumpStrkPltPrs "Bucket dump stroke pilot pressure";
CM_ SG_ 2583665441 BckcrowdStrkPltPrs "Bucket crowd stroke pilot pressure";
CM_ SG_ 2583665441 BoomDnStrkPltPrs "Boom down stroke pilot pressure";
CM_ SG_ 2583665441 BoomupStrkPltPrs "Boom up stroke pilot pressure";
CM_ BO_ 2583665697 "EPOS CAN Data for PHM12";
CM_ SG_ 2583665697 Bypass2SpoolEpprFdbkCur "Bypass2 spool eppr feedback current";
CM_ SG_ 2583665697 Bypass1SpoolEpprFdbkCur "Bypass1 spool eppr feedback current";
CM_ SG_ 2583665697 Boom2SpoolEpprFdbkCur "Boom2 spool eppr feedback current";
CM_ SG_ 2583665697 Bck2SpoolEpprFdbkCur "Bucket2 spool eppr feedback current";
CM_ SG_ 2583665697 Arm2SpoolEpprFdbkCur "Arm2 spool eppr feedback current";
CM_ SG_ 2583665697 ArmLckSpoolEpprFdbkCur "Arm lock spool eppr feedback current";
CM_ BO_ 2583665953 "EPOS CAN Data for PHM13";
CM_ SG_ 2583665953 BoomConfSpoolPilotPrs "Boom confluence spool pilot pressure";
CM_ SG_ 2583665953 BckConfSpoolPilotPrs "Bucket confluence spool pilot pressure";
CM_ SG_ 2583665953 ArmConfSpoolPilotPrs "Arm confluence spool pilot pressure";
CM_ SG_ 2583665953 ArmLckSpoolPilotPrs "Arm lock spool pilot pressure";
CM_ BO_ 2583666209 "EPOS CAN Data for PHM14";
CM_ SG_ 2583666209 Pmp2FinPrsCmd "Pump2 final pressure command";
CM_ SG_ 2583666209 Pmp1FinPrsCmd "Pump1 final pressure command";
CM_ SG_ 2583666209 RrPmpPrs " [???] ?? ?? ?? ";
CM_ SG_ 2583666209 FrPmpPrs " [???] ??? ?? ??";
CM_ BO_ 2633656127 "Oil Quality Message 2";
CM_ SG_ 2633656127 Oilresistivity "Oil resistivity";
CM_ BO_ 2633656238 "Oil Quality Message 2";
CM_ SG_ 2633656238 Oilresistivity "Oil resistivity";
BA_DEF_ BO_  "VFrameFormat" ENUM  "StandardCAN","ExtendedCAN","reserved","J1939PG";
BA_DEF_ BO_  "Channel" STRING ;
BA_DEF_ BO_  "VssMsg" STRING ;
BA_DEF_ SG_  "VssSig" STRING ;
BA_DEF_ BO_  "GenMsgCycleTime" INT 0 65535;
BA_DEF_DEF_  "VFrameFormat" "J1939PG";
BA_DEF_DEF_  "Channel" "";
BA_DEF_DEF_  "VssMsg" "";
BA_DEF_DEF_  "VssSig" "";
BA_DEF_DEF_  "GenMsgCycleTime" 0;
BA_ "VssMsg" BO_ 2566904865 "Mch.MCU.CETI";
BA_ "Channel" BO_ 2566904865 "can1";
BA_ "VssMsg" BO_ 2566905121 "Mch.MCU.ASDI";
BA_ "Channel" BO_ 2566905121 "can1";
BA_ "VssMsg" BO_ 2566905377 "Mch.MCU.FUDI";
BA_ "Channel" BO_ 2566905377 "can1";
BA_ "VssMsg" BO_ 2566905633 "Mch.MCU.UHDI";
BA_ "Channel" BO_ 2566905633 "can1";
BA_ "VssMsg" BO_ 2566905889 "Mch.MCU.RTFI";
BA_ "Channel" BO_ 2566905889 "can1";
BA_ "VssMsg" BO_ 2566906145 "Mch.MCU.FLI";
BA_ "Channel" BO_ 2566906145 "can1";
BA_ "VssMsg" BO_ 2566906401 "Mch.MCU.ARTFI";
BA_ "Channel" BO_ 2566906401 "can1";
BA_ "VssMsg" BO_ 2566906657 "Mch.MCU.TPUC";
BA_ "Channel" BO_ 2566906657 "can1";
BA_ "VssMsg" BO_ 2566907169 "Mch.MCU.VSWVER";
BA_ "Channel" BO_ 2566907169 "can1";
BA_ "VssMsg" BO_ 2566907681 "Mch.MCU.ECOGI";
BA_ "Channel" BO_ 2566907681 "can1";
BA_ "VssMsg" BO_ 2566907937 "Mch.MCU.MCI";
BA_ "Channel" BO_ 2566907937 "can1";
BA_ "GenMsgCycleTime" BO_ 2566908449 100;
BA_ "VssMsg" BO_ 2566908449 "Mch.MCU.MWIG";
BA_ "Channel" BO_ 2566908449 "can1";
BA_ "GenMsgCycleTime" BO_ 2566908705 100;
BA_ "VssMsg" BO_ 2566908705 "Mch.MCU.TWG";
BA_ "Channel" BO_ 2566908705 "can1";
BA_ "GenMsgCycleTime" BO_ 2566908961 100;
BA_ "VssMsg" BO_ 2566908961 "Mch.MCU.WCPR";
BA_ "Channel" BO_ 2566908961 "can1";
BA_ "GenMsgCycleTime" BO_ 2566909217 100;
BA_ "VssMsg" BO_ 2566909217 "Mch.MCU.WCCV";
BA_ "Channel" BO_ 2566909217 "can1";
BA_ "GenMsgCycleTime" BO_ 2566909473 100;
BA_ "VssMsg" BO_ 2566909473 "Mch.MCU.WCJA";
BA_ "Channel" BO_ 2566909473 "can1";
BA_ "GenMsgCycleTime" BO_ 2566909729 100;
BA_ "VssMsg" BO_ 2566909729 "Mch.MCU.LADG";
BA_ "Channel" BO_ 2566909729 "can1";
BA_ "VssMsg" BO_ 2634018819 "Mch.TCU.TCUID";
BA_ "Channel" BO_ 2634018819 "can1";
BA_ "GenMsgCycleTime" BO_ 2566910241 100;
BA_ "VssMsg" BO_ 2566910241 "Mch.MCU.ASRG";
BA_ "Channel" BO_ 2566910241 "can1";
BA_ "VssMsg" BO_ 2566910534 "Mch.EVC.ETCCMVCU";
BA_ "Channel" BO_ 2566910534 "can1";
BA_ "VssMsg" BO_ 2566912289 "Mch.MCU.MWHG4";
BA_ "Channel" BO_ 2566912289 "can1";
BA_ "VssMsg" BO_ 2566912545 "Mch.MCU.MWHG1";
BA_ "Channel" BO_ 2566912545 "can1";
BA_ "VssMsg" BO_ 2566912801 "Mch.MCU.MWHG2";
BA_ "Channel" BO_ 2566912801 "can1";
BA_ "VssMsg" BO_ 2566913057 "Mch.MCU.MWHG3";
BA_ "Channel" BO_ 2566913057 "can1";
BA_ "VssMsg" BO_ 2566913313 "Mch.MCU.MWTSV";
BA_ "Channel" BO_ 2566913313 "can1";
BA_ "VssMsg" BO_ 2566913569 "Mch.MCU.MTSI";
BA_ "Channel" BO_ 2566913569 "can1";
BA_ "VssMsg" BO_ 2566913825 "Mch.MCU.MAWI";
BA_ "Channel" BO_ 2566913825 "can1";
BA_ "GenMsgCycleTime" BO_ 2583646241 10;
BA_ "VssMsg" BO_ 2583646241 "Mch.MCU.FPSSC";
BA_ "Channel" BO_ 2583646241 "can1";
BA_ "GenMsgCycleTime" BO_ 2583646497 10;
BA_ "VssMsg" BO_ 2583646497 "Mch.MCU.RPSSC";
BA_ "Channel" BO_ 2583646497 "can1";
BA_ "GenMsgCycleTime" BO_ 2583646753 10;
BA_ "VssMsg" BO_ 2583646753 "Mch.MCU.OSSC";
BA_ "Channel" BO_ 2583646753 "can1";
BA_ "GenMsgCycleTime" BO_ 2583651424 10;
BA_ "VssMsg" BO_ 2583651424 "Mch.MCU2.FPDSSC";
BA_ "Channel" BO_ 2583651424 "can1";
BA_ "GenMsgCycleTime" BO_ 2583651680 10;
BA_ "VssMsg" BO_ 2583651680 "Mch.MCU2.RPDSSC";
BA_ "Channel" BO_ 2583651680 "can1";
BA_ "GenMsgCycleTime" BO_ 2583651936 10;
BA_ "VssMsg" BO_ 2583651936 "Mch.MCU2.ODSSC";
BA_ "Channel" BO_ 2583651936 "can1";
BA_ "GenMsgCycleTime" BO_ 2583654752 20;
BA_ "VssMsg" BO_ 2583654752 "Mch.MCU2.BBEFC";
BA_ "Channel" BO_ 2583654752 "can1";
BA_ "GenMsgCycleTime" BO_ 2583655008 20;
BA_ "VssMsg" BO_ 2583655008 "Mch.MCU2.ASEFC";
BA_ "Channel" BO_ 2583655008 "can1";
BA_ "GenMsgCycleTime" BO_ 2583655264 20;
BA_ "VssMsg" BO_ 2583655264 "Mch.MCU2.CEFC";
BA_ "Channel" BO_ 2583655264 "can1";
BA_ "GenMsgCycleTime" BO_ 2583655520 20;
BA_ "VssMsg" BO_ 2583655520 "Mch.MCU2.OEFC";
BA_ "Channel" BO_ 2583655520 "can1";
BA_ "GenMsgCycleTime" BO_ 2583655776 20;
BA_ "VssMsg" BO_ 2583655776 "Mch.MCU2.TEFC";
BA_ "Channel" BO_ 2583655776 "can1";
BA_ "GenMsgCycleTime" BO_ 2583656032 20;
BA_ "VssMsg" BO_ 2583656032 "Mch.MCU2.BBHRP";
BA_ "Channel" BO_ 2583656032 "can1";
BA_ "GenMsgCycleTime" BO_ 2583656288 20;
BA_ "VssMsg" BO_ 2583656288 "Mch.MCU2.AHRP";
BA_ "Channel" BO_ 2583656288 "can1";
BA_ "GenMsgCycleTime" BO_ 2583656544 20;
BA_ "VssMsg" BO_ 2583656544 "Mch.MCU2.CPSF";
BA_ "Channel" BO_ 2583656544 "can1";
BA_ "GenMsgCycleTime" BO_ 2583656800 20;
BA_ "VssMsg" BO_ 2583656800 "Mch.MCU2.VPP";
BA_ "Channel" BO_ 2583656800 "can1";
BA_ "GenMsgCycleTime" BO_ 2583657056 20;
BA_ "VssMsg" BO_ 2583657056 "Mch.MCU2.VPPSF";
BA_ "Channel" BO_ 2583657056 "can1";
BA_ "GenMsgCycleTime" BO_ 2583657312 20;
BA_ "VssMsg" BO_ 2583657312 "Mch.MCU2.PCS";
BA_ "Channel" BO_ 2583657312 "can1";
BA_ "GenMsgCycleTime" BO_ 2583667233 20;
BA_ "VssMsg" BO_ 2583667233 "Mch.MCU.CBCC";
BA_ "Channel" BO_ 2583667233 "can1";
BA_ "GenMsgCycleTime" BO_ 2583683873 20;
BA_ "VssMsg" BO_ 2583683873 "Mch.MCU.FJPP";
BA_ "Channel" BO_ 2583683873 "can1";
BA_ "GenMsgCycleTime" BO_ 2583684129 20;
BA_ "VssMsg" BO_ 2583684129 "Mch.MCU.TJPP";
BA_ "Channel" BO_ 2583684129 "can1";
BA_ "GenMsgCycleTime" BO_ 2583684385 20;
BA_ "VssMsg" BO_ 2583684385 "Mch.MCU.VFD";
BA_ "Channel" BO_ 2583684385 "can1";
BA_ "GenMsgCycleTime" BO_ 2583684641 20;
BA_ "VssMsg" BO_ 2583684641 "Mch.MCU.VP1D";
BA_ "Channel" BO_ 2583684641 "can1";
BA_ "GenMsgCycleTime" BO_ 2583684897 20;
BA_ "VssMsg" BO_ 2583684897 "Mch.MCU.VP2D";
BA_ "Channel" BO_ 2583684897 "can1";
BA_ "GenMsgCycleTime" BO_ 2583685153 20;
BA_ "VssMsg" BO_ 2583685153 "Mch.MCU.VTRQD";
BA_ "Channel" BO_ 2583685153 "can1";
BA_ "GenMsgCycleTime" BO_ 2583685409 20;
BA_ "VssMsg" BO_ 2583685409 "Mch.MCU.VSFC";
BA_ "Channel" BO_ 2583685409 "can1";
BA_ "GenMsgCycleTime" BO_ 2583685665 20;
BA_ "VssMsg" BO_ 2583685665 "Mch.MCU.VSPP";
BA_ "Channel" BO_ 2583685665 "can1";
BA_ "GenMsgCycleTime" BO_ 2583685921 20;
BA_ "VssMsg" BO_ 2583685921 "Mch.MCU.VPAD";
BA_ "Channel" BO_ 2583685921 "can1";
BA_ "GenMsgCycleTime" BO_ 2583686177 20;
BA_ "VssMsg" BO_ 2583686177 "Mch.MCU.VTD";
BA_ "Channel" BO_ 2583686177 "can1";
BA_ "GenMsgCycleTime" BO_ 2583686433 20;
BA_ "VssMsg" BO_ 2583686433 "Mch.MCU.VVQD";
BA_ "Channel" BO_ 2583686433 "can1";
BA_ "VssMsg" BO_ 2382360307 "Mch.AGW.TRADM2";
BA_ "Channel" BO_ 2382360307 "can1";
BA_ "VssMsg" BO_ 2382360563 "Mch.AGW.TRADM1";
BA_ "Channel" BO_ 2382360563 "can1";
BA_ "VssMsg" BO_ 2382360819 "Mch.AGW.TAIM1";
BA_ "Channel" BO_ 2382360819 "can1";
BA_ "VssMsg" BO_ 2382361075 "Mch.AGW.TRAIM1";
BA_ "Channel" BO_ 2382361075 "can1";
BA_ "GenMsgCycleTime" BO_ 2382361331 100;
BA_ "VssMsg" BO_ 2382361331 "Mch.AGW.TRSIM1";
BA_ "Channel" BO_ 2382361331 "can1";
BA_ "GenMsgCycleTime" BO_ 2382361587 10;
BA_ "VssMsg" BO_ 2382361587 "Mch.AGW.TRRSDM1";
BA_ "Channel" BO_ 2382361587 "can1";
BA_ "GenMsgCycleTime" BO_ 2382361843 10;
BA_ "VssMsg" BO_ 2382361843 "Mch.AGW.TRTSDM1";
BA_ "Channel" BO_ 2382361843 "can1";
BA_ "GenMsgCycleTime" BO_ 2382362867 50;
BA_ "VssMsg" BO_ 2382362867 "Mch.AGW.AFIM1";
BA_ "Channel" BO_ 2382362867 "can1";
BA_ "GenMsgCycleTime" BO_ 2382363123 50;
BA_ "VssMsg" BO_ 2382363123 "Mch.AGW.ALCM1";
BA_ "Channel" BO_ 2382363123 "can1";
BA_ "GenMsgCycleTime" BO_ 2382363379 50;
BA_ "VssMsg" BO_ 2382363379 "Mch.AGW.AHCM1";
BA_ "Channel" BO_ 2382363379 "can1";
BA_ "GenMsgCycleTime" BO_ 2382363681 50;
BA_ "VssMsg" BO_ 2382363681 "Mch.MCU.EIM1";
BA_ "Channel" BO_ 2382363681 "can1";
BA_ "GenMsgCycleTime" BO_ 2382364193 10;
BA_ "VssMsg" BO_ 2382364193 "Mch.MCU.ACM2";
BA_ "Channel" BO_ 2382364193 "can1";
BA_ "GenMsgCycleTime" BO_ 2382364449 10;
BA_ "VssMsg" BO_ 2382364449 "Mch.MCU.ACM1";
BA_ "Channel" BO_ 2382364449 "can1";
BA_ "GenMsgCycleTime" BO_ 2566842442 1000;
BA_ "VssMsg" BO_ 2566842442 "Mch.TGU.VDS";
BA_ "Channel" BO_ 2566842442 "can1";
BA_ "GenMsgCycleTime" BO_ 2566845258 1000;
BA_ "VssMsg" BO_ 2566845258 "Mch.TGU.VP1";
BA_ "Channel" BO_ 2566845258 "can1";
BA_ "VssMsg" BO_ 2583642954 "Mch.TGU.DKLLG";
BA_ "Channel" BO_ 2583642954 "can1";
BA_ "VssMsg" BO_ 2583643210 "Mch.TGU.DKLUG";
BA_ "Channel" BO_ 2583643210 "can1";
BA_ "VssMsg" BO_ 2583643466 "Mch.TGU.DKTL";
BA_ "Channel" BO_ 2583643466 "can1";
BA_ "VssMsg" BO_ 2583642186 "Mch.TGU.TMSI";
BA_ "Channel" BO_ 2583642186 "can1";
BA_ "VssMsg" BO_ 2583642442 "Mch.TGU.MPI";
BA_ "Channel" BO_ 2583642442 "can1";
BA_ "GenMsgCycleTime" BO_ 2583642698 5000;
BA_ "VssMsg" BO_ 2583642698 "Mch.TGU.TCNI";
BA_ "Channel" BO_ 2583642698 "can1";
BA_ "VssMsg" BO_ 2583642401 "Mch.MCU.MPI";
BA_ "Channel" BO_ 2583642401 "can1";
BA_ "GenMsgCycleTime" BO_ 2583662698 200;
BA_ "VssMsg" BO_ 2583662698 "Mch.TGU.PHMWG";
BA_ "Channel" BO_ 2583662698 "can1";
BA_ "GenMsgCycleTime" BO_ 2583666538 3000;
BA_ "VssMsg" BO_ 2583666538 "Mch.TGU.THO";
BA_ "Channel" BO_ 2583666538 "can1";
BA_ "GenMsgCycleTime" BO_ 2583666794 3000;
BA_ "VssMsg" BO_ 2583666794 "Mch.TGU.TEO";
BA_ "Channel" BO_ 2583666794 "can1";
BA_ "GenMsgCycleTime" BO_ 2583667050 3000;
BA_ "VssMsg" BO_ 2583667050 "Mch.TGU.KVO";
BA_ "Channel" BO_ 2583667050 "can1";
BA_ "GenMsgCycleTime" BO_ 2583662881 1000;
BA_ "VssMsg" BO_ 2583662881 "Mch.MCU.ECDP1";
BA_ "Channel" BO_ 2583662881 "can1";
BA_ "GenMsgCycleTime" BO_ 2583663137 1000;
BA_ "VssMsg" BO_ 2583663137 "Mch.MCU.ECDP2";
BA_ "Channel" BO_ 2583663137 "can1";
BA_ "GenMsgCycleTime" BO_ 2583663393 100;
BA_ "VssMsg" BO_ 2583663393 "Mch.MCU.ECDP3";
BA_ "Channel" BO_ 2583663393 "can1";
BA_ "GenMsgCycleTime" BO_ 2583663649 100;
BA_ "VssMsg" BO_ 2583663649 "Mch.MCU.ECDP4";
BA_ "Channel" BO_ 2583663649 "can1";
BA_ "GenMsgCycleTime" BO_ 2583663905 100;
BA_ "VssMsg" BO_ 2583663905 "Mch.MCU.ECDP5";
BA_ "Channel" BO_ 2583663905 "can1";
BA_ "GenMsgCycleTime" BO_ 2583664161 100;
BA_ "VssMsg" BO_ 2583664161 "Mch.MCU.ECDP6";
BA_ "Channel" BO_ 2583664161 "can1";
BA_ "GenMsgCycleTime" BO_ 2583664417 100;
BA_ "VssMsg" BO_ 2583664417 "Mch.MCU.ECDP7";
BA_ "Channel" BO_ 2583664417 "can1";
BA_ "GenMsgCycleTime" BO_ 2583664673 100;
BA_ "VssMsg" BO_ 2583664673 "Mch.MCU.ECDP8";
BA_ "Channel" BO_ 2583664673 "can1";
BA_ "GenMsgCycleTime" BO_ 2583664929 100;
BA_ "VssMsg" BO_ 2583664929 "Mch.MCU.ECDP9";
BA_ "Channel" BO_ 2583664929 "can1";
BA_ "GenMsgCycleTime" BO_ 2583665185 100;
BA_ "VssMsg" BO_ 2583665185 "Mch.MCU.ECDP10";
BA_ "Channel" BO_ 2583665185 "can1";
BA_ "GenMsgCycleTime" BO_ 2583665441 100;
BA_ "VssMsg" BO_ 2583665441 "Mch.MCU.ECDP11";
BA_ "Channel" BO_ 2583665441 "can1";
BA_ "GenMsgCycleTime" BO_ 2583665697 100;
BA_ "VssMsg" BO_ 2583665697 "Mch.MCU.ECDP12";
BA_ "Channel" BO_ 2583665697 "can1";
BA_ "GenMsgCycleTime" BO_ 2583665953 100;
BA_ "VssMsg" BO_ 2583665953 "Mch.MCU.ECDP13";
BA_ "Channel" BO_ 2583665953 "can1";
BA_ "GenMsgCycleTime" BO_ 2583666209 100;
BA_ "VssMsg" BO_ 2583666209 "Mch.MCU.ECDP14";
BA_ "Channel" BO_ 2583666209 "can1";
BA_ "GenMsgCycleTime" BO_ 2633656127 30000;
BA_ "VssMsg" BO_ 2633656127 "Mch.HDOQS.OQM2";
BA_ "Channel" BO_ 2633656127 "can2";
BA_ "GenMsgCycleTime" BO_ 2633656238 30000;
BA_ "VssMsg" BO_ 2633656238 "Mch.EGOQS.OQM2";
BA_ "Channel" BO_ 2633656238 "can2";
BA_ "VssSig" SG_ 2566904865 SalesRegion "Mch.MCU.CETI.SalesRegion";
BA_ "VssSig" SG_ 2566904865 TcuType "Mch.MCU.CETI.TcuType";
BA_ "VssSig" SG_ 2566904865 JoyType "Mch.MCU.CETI.JoyType";
BA_ "VssSig" SG_ 2566904865 McvCtrlType "Mch.MCU.CETI.McvCtrlType";
BA_ "VssSig" SG_ 2566904865 McvType "Mch.MCU.CETI.McvType";
BA_ "VssSig" SG_ 2566904865 PmpCtrlType "Mch.MCU.CETI.PmpCtrlType";
BA_ "VssSig" SG_ 2566904865 PmpType "Mch.MCU.CETI.PmpType";
BA_ "VssSig" SG_ 2566904865 EcuMaker "Mch.MCU.CETI.EcuMaker";
BA_ "VssSig" SG_ 2566904865 EgMaker "Mch.MCU.CETI.EgMaker";
BA_ "VssSig" SG_ 2566904865 ModelYearVer "Mch.MCU.CETI.ModelYearVer";
BA_ "VssSig" SG_ 2566904865 MchType "Mch.MCU.CETI.MchType";
BA_ "VssSig" SG_ 2566904865 MchClass "Mch.MCU.CETI.MchClass";
BA_ "VssSig" SG_ 2566904865 MchGen "Mch.MCU.CETI.MchGen";
BA_ "VssSig" SG_ 2566904865 EmsCtrl "Mch.MCU.CETI.EmsCtrl";
BA_ "VssSig" SG_ 2566905121 TwUseFlow4 "Mch.MCU.ASDI.TwUseFlow4";
BA_ "VssSig" SG_ 2566905121 TwUseFlow3 "Mch.MCU.ASDI.TwUseFlow3";
BA_ "VssSig" SG_ 2566905121 TwUseFlow2 "Mch.MCU.ASDI.TwUseFlow2";
BA_ "VssSig" SG_ 2566905121 TwUseFlow1 "Mch.MCU.ASDI.TwUseFlow1";
BA_ "VssSig" SG_ 2566905121 TwUseFlow0 "Mch.MCU.ASDI.TwUseFlow0";
BA_ "VssSig" SG_ 2566905121 TwSetFlow4 "Mch.MCU.ASDI.TwSetFlow4";
BA_ "VssSig" SG_ 2566905121 TwSetFlow3 "Mch.MCU.ASDI.TwSetFlow3";
BA_ "VssSig" SG_ 2566905121 TwSetFlow2 "Mch.MCU.ASDI.TwSetFlow2";
BA_ "VssSig" SG_ 2566905121 TwSetFlow1 "Mch.MCU.ASDI.TwSetFlow1";
BA_ "VssSig" SG_ 2566905121 TwSetFlow0 "Mch.MCU.ASDI.TwSetFlow0";
BA_ "VssSig" SG_ 2566905121 TwMinFlowAtt4 "Mch.MCU.ASDI.TwMinFlowAtt4";
BA_ "VssSig" SG_ 2566905121 TwMinFlowAtt3 "Mch.MCU.ASDI.TwMinFlowAtt3";
BA_ "VssSig" SG_ 2566905121 TwMinFlowAtt2 "Mch.MCU.ASDI.TwMinFlowAtt2";
BA_ "VssSig" SG_ 2566905121 TwMinFlowAtt1 "Mch.MCU.ASDI.TwMinFlowAtt1";
BA_ "VssSig" SG_ 2566905121 TwMinFlowAtt0 "Mch.MCU.ASDI.TwMinFlowAtt0";
BA_ "VssSig" SG_ 2566905121 TwMaxFlowAtt4 "Mch.MCU.ASDI.TwMaxFlowAtt4";
BA_ "VssSig" SG_ 2566905121 TwMaxFlowAtt3 "Mch.MCU.ASDI.TwMaxFlowAtt3";
BA_ "VssSig" SG_ 2566905121 TwMaxFlowAtt2 "Mch.MCU.ASDI.TwMaxFlowAtt2";
BA_ "VssSig" SG_ 2566905121 TwMaxFlowAtt1 "Mch.MCU.ASDI.TwMaxFlowAtt1";
BA_ "VssSig" SG_ 2566905121 TwMaxFlowAtt0 "Mch.MCU.ASDI.TwMaxFlowAtt0";
BA_ "VssSig" SG_ 2566905121 TwMaxFlowPmp4 "Mch.MCU.ASDI.TwMaxFlowPmp4";
BA_ "VssSig" SG_ 2566905121 TwMaxFlowPmp3 "Mch.MCU.ASDI.TwMaxFlowPmp3";
BA_ "VssSig" SG_ 2566905121 TwMaxFlowPmp2 "Mch.MCU.ASDI.TwMaxFlowPmp2";
BA_ "VssSig" SG_ 2566905121 TwMaxFlowPmp1 "Mch.MCU.ASDI.TwMaxFlowPmp1";
BA_ "VssSig" SG_ 2566905121 TwMaxFlowPmp0 "Mch.MCU.ASDI.TwMaxFlowPmp0";
BA_ "VssSig" SG_ 2566905121 TwPrs4 "Mch.MCU.ASDI.TwPrs4";
BA_ "VssSig" SG_ 2566905121 TwPrs3 "Mch.MCU.ASDI.TwPrs3";
BA_ "VssSig" SG_ 2566905121 TwPrs2 "Mch.MCU.ASDI.TwPrs2";
BA_ "VssSig" SG_ 2566905121 TwPrs1 "Mch.MCU.ASDI.TwPrs1";
BA_ "VssSig" SG_ 2566905121 TwPrs0 "Mch.MCU.ASDI.TwPrs0";
BA_ "VssSig" SG_ 2566905121 TwRpm4 "Mch.MCU.ASDI.TwRpm4";
BA_ "VssSig" SG_ 2566905121 TwRpm3 "Mch.MCU.ASDI.TwRpm3";
BA_ "VssSig" SG_ 2566905121 TwRpm2 "Mch.MCU.ASDI.TwRpm2";
BA_ "VssSig" SG_ 2566905121 TwRpm1 "Mch.MCU.ASDI.TwRpm1";
BA_ "VssSig" SG_ 2566905121 TwRpm0 "Mch.MCU.ASDI.TwRpm0";
BA_ "VssSig" SG_ 2566905121 Tw4BrkrBtnType "Mch.MCU.ASDI.Tw4BrkrBtnType";
BA_ "VssSig" SG_ 2566905121 Tw4TwoPmpOpt "Mch.MCU.ASDI.Tw4TwoPmpOpt";
BA_ "VssSig" SG_ 2566905121 Tw4SelAttNo "Mch.MCU.ASDI.Tw4SelAttNo";
BA_ "VssSig" SG_ 2566905121 Tw4SelAttType "Mch.MCU.ASDI.Tw4SelAttType";
BA_ "VssSig" SG_ 2566905121 Tw3BrkrBtnType "Mch.MCU.ASDI.Tw3BrkrBtnType";
BA_ "VssSig" SG_ 2566905121 Tw3TwoPmpOpt "Mch.MCU.ASDI.Tw3TwoPmpOpt";
BA_ "VssSig" SG_ 2566905121 Tw3SelAttNo "Mch.MCU.ASDI.Tw3SelAttNo";
BA_ "VssSig" SG_ 2566905121 Tw3SelAttType "Mch.MCU.ASDI.Tw3SelAttType";
BA_ "VssSig" SG_ 2566905121 Tw2BrkrBtnType "Mch.MCU.ASDI.Tw2BrkrBtnType";
BA_ "VssSig" SG_ 2566905121 Tw2TwoPmpOpt "Mch.MCU.ASDI.Tw2TwoPmpOpt";
BA_ "VssSig" SG_ 2566905121 Tw2SelAttNo "Mch.MCU.ASDI.Tw2SelAttNo";
BA_ "VssSig" SG_ 2566905121 Tw2SelAttType "Mch.MCU.ASDI.Tw2SelAttType";
BA_ "VssSig" SG_ 2566905121 Tw1BrkrBtnType "Mch.MCU.ASDI.Tw1BrkrBtnType";
BA_ "VssSig" SG_ 2566905121 Tw1TwoPmpOpt "Mch.MCU.ASDI.Tw1TwoPmpOpt";
BA_ "VssSig" SG_ 2566905121 Tw1SelAttNo "Mch.MCU.ASDI.Tw1SelAttNo";
BA_ "VssSig" SG_ 2566905121 Tw1SelAttType "Mch.MCU.ASDI.Tw1SelAttType";
BA_ "VssSig" SG_ 2566905121 Tw0BrkrBtnType "Mch.MCU.ASDI.Tw0BrkrBtnType";
BA_ "VssSig" SG_ 2566905121 Tw0TwoPmpOpt "Mch.MCU.ASDI.Tw0TwoPmpOpt";
BA_ "VssSig" SG_ 2566905121 Tw0SelAttNo "Mch.MCU.ASDI.Tw0SelAttNo";
BA_ "VssSig" SG_ 2566905121 Tw0SelAttType "Mch.MCU.ASDI.Tw0SelAttType";
BA_ "VssSig" SG_ 2566905121 OwUseFlow4 "Mch.MCU.ASDI.OwUseFlow4";
BA_ "VssSig" SG_ 2566905121 OwUseFlow3 "Mch.MCU.ASDI.OwUseFlow3";
BA_ "VssSig" SG_ 2566905121 OwUseFlow2 "Mch.MCU.ASDI.OwUseFlow2";
BA_ "VssSig" SG_ 2566905121 OwUseFlow1 "Mch.MCU.ASDI.OwUseFlow1";
BA_ "VssSig" SG_ 2566905121 OwUseFlow0 "Mch.MCU.ASDI.OwUseFlow0";
BA_ "VssSig" SG_ 2566905121 OwSetFlow4 "Mch.MCU.ASDI.OwSetFlow4";
BA_ "VssSig" SG_ 2566905121 OwSetFlow3 "Mch.MCU.ASDI.OwSetFlow3";
BA_ "VssSig" SG_ 2566905121 OwSetFlow2 "Mch.MCU.ASDI.OwSetFlow2";
BA_ "VssSig" SG_ 2566905121 OwSetFlow1 "Mch.MCU.ASDI.OwSetFlow1";
BA_ "VssSig" SG_ 2566905121 OwSetFlow0 "Mch.MCU.ASDI.OwSetFlow0";
BA_ "VssSig" SG_ 2566905121 OwMinFlowAtt4 "Mch.MCU.ASDI.OwMinFlowAtt4";
BA_ "VssSig" SG_ 2566905121 OwMinFlowAtt3 "Mch.MCU.ASDI.OwMinFlowAtt3";
BA_ "VssSig" SG_ 2566905121 OwMinFlowAtt2 "Mch.MCU.ASDI.OwMinFlowAtt2";
BA_ "VssSig" SG_ 2566905121 OwMinFlowAtt1 "Mch.MCU.ASDI.OwMinFlowAtt1";
BA_ "VssSig" SG_ 2566905121 OwMinFlowAtt0 "Mch.MCU.ASDI.OwMinFlowAtt0";
BA_ "VssSig" SG_ 2566905121 OwMaxFlowAtt4 "Mch.MCU.ASDI.OwMaxFlowAtt4";
BA_ "VssSig" SG_ 2566905121 OwMaxFlowAtt3 "Mch.MCU.ASDI.OwMaxFlowAtt3";
BA_ "VssSig" SG_ 2566905121 OwMaxFlowAtt2 "Mch.MCU.ASDI.OwMaxFlowAtt2";
BA_ "VssSig" SG_ 2566905121 OwMaxFlowAtt1 "Mch.MCU.ASDI.OwMaxFlowAtt1";
BA_ "VssSig" SG_ 2566905121 OwMaxFlowAtt0 "Mch.MCU.ASDI.OwMaxFlowAtt0";
BA_ "VssSig" SG_ 2566905121 OwMaxFlowPmp4 "Mch.MCU.ASDI.OwMaxFlowPmp4";
BA_ "VssSig" SG_ 2566905121 OwMaxFlowPmp3 "Mch.MCU.ASDI.OwMaxFlowPmp3";
BA_ "VssSig" SG_ 2566905121 OwMaxFlowPmp2 "Mch.MCU.ASDI.OwMaxFlowPmp2";
BA_ "VssSig" SG_ 2566905121 OwMaxFlowPmp1 "Mch.MCU.ASDI.OwMaxFlowPmp1";
BA_ "VssSig" SG_ 2566905121 OwMaxFlowPmp0 "Mch.MCU.ASDI.OwMaxFlowPmp0";
BA_ "VssSig" SG_ 2566905121 OwPrs4 "Mch.MCU.ASDI.OwPrs4";
BA_ "VssSig" SG_ 2566905121 OwPrs3 "Mch.MCU.ASDI.OwPrs3";
BA_ "VssSig" SG_ 2566905121 OwPrs2 "Mch.MCU.ASDI.OwPrs2";
BA_ "VssSig" SG_ 2566905121 OwPrs1 "Mch.MCU.ASDI.OwPrs1";
BA_ "VssSig" SG_ 2566905121 OwPrs0 "Mch.MCU.ASDI.OwPrs0";
BA_ "VssSig" SG_ 2566905121 OwRpm4 "Mch.MCU.ASDI.OwRpm4";
BA_ "VssSig" SG_ 2566905121 OwRpm3 "Mch.MCU.ASDI.OwRpm3";
BA_ "VssSig" SG_ 2566905121 OwRpm2 "Mch.MCU.ASDI.OwRpm2";
BA_ "VssSig" SG_ 2566905121 OwRpm1 "Mch.MCU.ASDI.OwRpm1";
BA_ "VssSig" SG_ 2566905121 OwRpm0 "Mch.MCU.ASDI.OwRpm0";
BA_ "VssSig" SG_ 2566905121 RttCurStep "Mch.MCU.ASDI.RttCurStep";
BA_ "VssSig" SG_ 2566905121 TwCurStep "Mch.MCU.ASDI.TwCurStep";
BA_ "VssSig" SG_ 2566905121 Ow4BrkrBtnType "Mch.MCU.ASDI.Ow4BrkrBtnType";
BA_ "VssSig" SG_ 2566905121 Ow4TwoPmpOpt "Mch.MCU.ASDI.Ow4TwoPmpOpt";
BA_ "VssSig" SG_ 2566905121 Ow4SelAttNo "Mch.MCU.ASDI.Ow4SelAttNo";
BA_ "VssSig" SG_ 2566905121 Ow4SelAttType "Mch.MCU.ASDI.Ow4SelAttType";
BA_ "VssSig" SG_ 2566905121 OwCurStep "Mch.MCU.ASDI.OwCurStep";
BA_ "VssSig" SG_ 2566905121 Ow3BrkrBtnType "Mch.MCU.ASDI.Ow3BrkrBtnType";
BA_ "VssSig" SG_ 2566905121 Ow3TwoPmpOpt "Mch.MCU.ASDI.Ow3TwoPmpOpt";
BA_ "VssSig" SG_ 2566905121 Ow3SelAttNo "Mch.MCU.ASDI.Ow3SelAttNo";
BA_ "VssSig" SG_ 2566905121 Ow3SelAttType "Mch.MCU.ASDI.Ow3SelAttType";
BA_ "VssSig" SG_ 2566905121 Ow2BrkrBtnType "Mch.MCU.ASDI.Ow2BrkrBtnType";
BA_ "VssSig" SG_ 2566905121 Ow2TwoPmpOpt "Mch.MCU.ASDI.Ow2TwoPmpOpt";
BA_ "VssSig" SG_ 2566905121 Ow2SelAttNo "Mch.MCU.ASDI.Ow2SelAttNo";
BA_ "VssSig" SG_ 2566905121 Ow2SelAttType "Mch.MCU.ASDI.Ow2SelAttType";
BA_ "VssSig" SG_ 2566905121 Ow1BrkrBtnType "Mch.MCU.ASDI.Ow1BrkrBtnType";
BA_ "VssSig" SG_ 2566905121 Ow1TwoPmpOpt "Mch.MCU.ASDI.Ow1TwoPmpOpt";
BA_ "VssSig" SG_ 2566905121 Ow1SelAttNo "Mch.MCU.ASDI.Ow1SelAttNo";
BA_ "VssSig" SG_ 2566905121 Ow1SelAttType "Mch.MCU.ASDI.Ow1SelAttType";
BA_ "VssSig" SG_ 2566905121 Ow0BrkrBtnType "Mch.MCU.ASDI.Ow0BrkrBtnType";
BA_ "VssSig" SG_ 2566905121 Ow0TwoPmpOpt "Mch.MCU.ASDI.Ow0TwoPmpOpt";
BA_ "VssSig" SG_ 2566905121 Ow0SelAttNo "Mch.MCU.ASDI.Ow0SelAttNo";
BA_ "VssSig" SG_ 2566905121 Ow0SelAttType "Mch.MCU.ASDI.Ow0SelAttType";
BA_ "VssSig" SG_ 2566905121 MaxFlow "Mch.MCU.ASDI.MaxFlow";
BA_ "VssSig" SG_ 2566905121 MinFlow "Mch.MCU.ASDI.MinFlow";
BA_ "VssSig" SG_ 2566905121 MaxPrsTw "Mch.MCU.ASDI.MaxPrsTw";
BA_ "VssSig" SG_ 2566905121 MinPrsTw "Mch.MCU.ASDI.MinPrsTw";
BA_ "VssSig" SG_ 2566905121 MaxPrsOw "Mch.MCU.ASDI.MaxPrsOw";
BA_ "VssSig" SG_ 2566905121 MinPrsOw "Mch.MCU.ASDI.MinPrsOw";
BA_ "VssSig" SG_ 2566905121 MaxSpd "Mch.MCU.ASDI.MaxSpd";
BA_ "VssSig" SG_ 2566905121 MinSpd "Mch.MCU.ASDI.MinSpd";
BA_ "VssSig" SG_ 2566905121 SelAttTw "Mch.MCU.ASDI.SelAttTw";
BA_ "VssSig" SG_ 2566905121 SelAttOw "Mch.MCU.ASDI.SelAttOw";
BA_ "VssSig" SG_ 2566905377 TrvlStd "Mch.MCU.FUDI.TrvlStd";
BA_ "VssSig" SG_ 2566905377 TrvlPow "Mch.MCU.FUDI.TrvlPow";
BA_ "VssSig" SG_ 2566905377 Idle "Mch.MCU.FUDI.Idle";
BA_ "VssSig" SG_ 2566905377 AutoIdle "Mch.MCU.FUDI.AutoIdle";
BA_ "VssSig" SG_ 2566905377 EcnMd "Mch.MCU.FUDI.EcnMd";
BA_ "VssSig" SG_ 2566905377 StdMd "Mch.MCU.FUDI.StdMd";
BA_ "VssSig" SG_ 2566905377 PowMd "Mch.MCU.FUDI.PowMd";
BA_ "VssSig" SG_ 2566905377 PowPlusMd "Mch.MCU.FUDI.PowPlusMd";
BA_ "VssSig" SG_ 2566905633 TotOprHr "Mch.MCU.UHDI.TotOprHr";
BA_ "VssSig" SG_ 2566905633 Co0lTempAbove106 "Mch.MCU.UHDI.Co0lTempAbove106";
BA_ "VssSig" SG_ 2566905633 Co0lTemp96105 "Mch.MCU.UHDI.Co0lTemp96105";
BA_ "VssSig" SG_ 2566905633 Co0lTemp96100 "Mch.MCU.UHDI.Co0lTemp96100";
BA_ "VssSig" SG_ 2566905633 Co0lTemp9195 "Mch.MCU.UHDI.Co0lTemp9195";
BA_ "VssSig" SG_ 2566905633 Co0lTemp8190 "Mch.MCU.UHDI.Co0lTemp8190";
BA_ "VssSig" SG_ 2566905633 Co0lTempBelow80 "Mch.MCU.UHDI.Co0lTempBelow80";
BA_ "VssSig" SG_ 2566905633 HydOilTmpAbove96 "Mch.MCU.UHDI.HydOilTmpAbove96";
BA_ "VssSig" SG_ 2566905633 HydOilTmp9195 "Mch.MCU.UHDI.HydOilTmp9195";
BA_ "VssSig" SG_ 2566905633 HydOilTmp8190 "Mch.MCU.UHDI.HydOilTmp8190";
BA_ "VssSig" SG_ 2566905633 HydOilTmp7180 "Mch.MCU.UHDI.HydOilTmp7180";
BA_ "VssSig" SG_ 2566905633 HydOilTmp5170 "Mch.MCU.UHDI.HydOilTmp5170";
BA_ "VssSig" SG_ 2566905633 HydOilTmpBelow50 "Mch.MCU.UHDI.HydOilTmpBelow50";
BA_ "VssSig" SG_ 2566905633 TwMd "Mch.MCU.UHDI.TwMd";
BA_ "VssSig" SG_ 2566905633 BrkrMd "Mch.MCU.UHDI.BrkrMd";
BA_ "VssSig" SG_ 2566905633 LiftMd "Mch.MCU.UHDI.LiftMd";
BA_ "VssSig" SG_ 2566905633 TrvlStd "Mch.MCU.UHDI.TrvlStd";
BA_ "VssSig" SG_ 2566905633 TrvlPow "Mch.MCU.UHDI.TrvlPow";
BA_ "VssSig" SG_ 2566905633 Idle "Mch.MCU.UHDI.Idle";
BA_ "VssSig" SG_ 2566905633 AutoIdle "Mch.MCU.UHDI.AutoIdle";
BA_ "VssSig" SG_ 2566905633 EcnMd "Mch.MCU.UHDI.EcnMd";
BA_ "VssSig" SG_ 2566905633 StdMd "Mch.MCU.UHDI.StdMd";
BA_ "VssSig" SG_ 2566905633 PowMd "Mch.MCU.UHDI.PowMd";
BA_ "VssSig" SG_ 2566905633 PowPlusMd "Mch.MCU.UHDI.PowPlusMd";
BA_ "VssSig" SG_ 2566905889 Afc7 "Mch.MCU.RTFI.Afc7";
BA_ "VssSig" SG_ 2566905889 Afc6 "Mch.MCU.RTFI.Afc6";
BA_ "VssSig" SG_ 2566905889 Afc5 "Mch.MCU.RTFI.Afc5";
BA_ "VssSig" SG_ 2566905889 Afc4 "Mch.MCU.RTFI.Afc4";
BA_ "VssSig" SG_ 2566905889 Afc3 "Mch.MCU.RTFI.Afc3";
BA_ "VssSig" SG_ 2566905889 Afc2 "Mch.MCU.RTFI.Afc2";
BA_ "VssSig" SG_ 2566905889 Afc1 "Mch.MCU.RTFI.Afc1";
BA_ "VssSig" SG_ 2566906145 Hfc2FirstOcrTm "Mch.MCU.FLI.Hfc2FirstOcrTm";
BA_ "VssSig" SG_ 2566906145 Hfc2 "Mch.MCU.FLI.Hfc2";
BA_ "VssSig" SG_ 2566906145 Hfc2Cnt "Mch.MCU.FLI.Hfc2Cnt";
BA_ "VssSig" SG_ 2566906145 Hfc1FirstOcrTm "Mch.MCU.FLI.Hfc1FirstOcrTm";
BA_ "VssSig" SG_ 2566906145 Hfc1 "Mch.MCU.FLI.Hfc1";
BA_ "VssSig" SG_ 2566906145 Hfc1Cnt "Mch.MCU.FLI.Hfc1Cnt";
BA_ "VssSig" SG_ 2566906657 TmsPunlckCode "Mch.MCU.TPUC.TmsPunlckCode";
BA_ "VssSig" SG_ 2566907169 McuSwVerYear "Mch.MCU.VSWVER.McuSwVerYear";
BA_ "VssSig" SG_ 2566907169 McuSwVerDay "Mch.MCU.VSWVER.McuSwVerDay";
BA_ "VssSig" SG_ 2566907169 McuSwVerMonth "Mch.MCU.VSWVER.McuSwVerMonth";
BA_ "VssSig" SG_ 2566907169 McuSwVer "Mch.MCU.VSWVER.McuSwVer";
BA_ "VssSig" SG_ 2566907681 IccoFunCrcmdScore "Mch.MCU.ECOGI.IccoFunCrcmdScore";
BA_ "VssSig" SG_ 2566907681 UnssHydReliefScore "Mch.MCU.ECOGI.UnssHydReliefScore";
BA_ "VssSig" SG_ 2566907681 InIntentBrkPreventScore "Mch.MCU.ECOGI.InIntentBrkPreventScore";
BA_ "VssSig" SG_ 2566907681 EmgStpPreventScore "Mch.MCU.ECOGI.EmgStpPreventScore";
BA_ "VssSig" SG_ 2566907681 EgMdDnRcmdScore "Mch.MCU.ECOGI.EgMdDnRcmdScore";
BA_ "VssSig" SG_ 2566907681 LckUpRcmdScore "Mch.MCU.ECOGI.LckUpRcmdScore";
BA_ "VssSig" SG_ 2566907681 GrNeutRpmUpScore "Mch.MCU.ECOGI.GrNeutRpmUpScore";
BA_ "VssSig" SG_ 2566907681 IdlePrvtScore "Mch.MCU.ECOGI.IdlePrvtScore";
BA_ "VssSig" SG_ 2566907681 ManGrMaxSpdRcmdScore "Mch.MCU.ECOGI.ManGrMaxSpdRcmdScore";
BA_ "VssSig" SG_ 2566907681 Auto14RcmdScore "Mch.MCU.ECOGI.Auto14RcmdScore";
BA_ "VssSig" SG_ 2566907681 LisVhcSpdSetDnChngRcmdScore "Mch.MCU.ECOGI.LisVhcSpdSetDnChngRcmdScore";
BA_ "VssSig" SG_ 2566907681 LisVhcSpdSetUpChngRcmdScore "Mch.MCU.ECOGI.LisVhcSpdSetUpChngRcmdScore";
BA_ "VssSig" SG_ 2566907681 LisFunCrcmdScore "Mch.MCU.ECOGI.LisFunCrcmdScore";
BA_ "VssSig" SG_ 2566907681 IccoFunCrctm "Mch.MCU.ECOGI.IccoFunCrctm";
BA_ "VssSig" SG_ 2566907681 EgMdDnRctm "Mch.MCU.ECOGI.EgMdDnRctm";
BA_ "VssSig" SG_ 2566907681 LckUpRcmd "Mch.MCU.ECOGI.LckUpRcmd";
BA_ "VssSig" SG_ 2566907681 IdlePrvtRcmd "Mch.MCU.ECOGI.IdlePrvtRcmd";
BA_ "VssSig" SG_ 2566907681 Auto14Rcmd "Mch.MCU.ECOGI.Auto14Rcmd";
BA_ "VssSig" SG_ 2566907681 LisRcmd "Mch.MCU.ECOGI.LisRcmd";
BA_ "VssSig" SG_ 2566907937 ElecStrJoyThmbWhlConf "Mch.MCU.MCI.ElecStrJoyThmbWhlConf";
BA_ "VssSig" SG_ 2566907937 Dl06EgFuelEffCalbConf "Mch.MCU.MCI.Dl06EgFuelEffCalbConf";
BA_ "VssSig" SG_ 2566907937 RttThmbWhlDirConf "Mch.MCU.MCI.RttThmbWhlDirConf";
BA_ "VssSig" SG_ 2566907937 TwThmbWhlDirConf "Mch.MCU.MCI.TwThmbWhlDirConf";
BA_ "VssSig" SG_ 2566907937 CanPdlIntChngConf "Mch.MCU.MCI.CanPdlIntChngConf";
BA_ "VssSig" SG_ 2566907937 TrvlSwgAlmIntChngConf "Mch.MCU.MCI.TrvlSwgAlmIntChngConf";
BA_ "VssSig" SG_ 2566907937 OprHrTmpIntChngConf "Mch.MCU.MCI.OprHrTmpIntChngConf";
BA_ "VssSig" SG_ 2566907937 QckCouplerIntChngConf "Mch.MCU.MCI.QckCouplerIntChngConf";
BA_ "VssSig" SG_ 2566907937 ThmbWhlSensConf "Mch.MCU.MCI.ThmbWhlSensConf";
BA_ "VssSig" SG_ 2566907937 MultiFuncJoyBtnConf "Mch.MCU.MCI.MultiFuncJoyBtnConf";
BA_ "VssSig" SG_ 2566908449 AssitSwgRh "Mch.MCU.MWIG.AssitSwgRh";
BA_ "VssSig" SG_ 2566908449 AssitSwgLh "Mch.MCU.MWIG.AssitSwgLh";
BA_ "VssSig" SG_ 2566908449 AssitBck "Mch.MCU.MWIG.AssitBck";
BA_ "VssSig" SG_ 2566908449 AssitGrd "Mch.MCU.MWIG.AssitGrd";
BA_ "VssSig" SG_ 2566908449 SafeWrkSideFar "Mch.MCU.MWIG.SafeWrkSideFar";
BA_ "VssSig" SG_ 2566908449 SafeWrkSideMid "Mch.MCU.MWIG.SafeWrkSideMid";
BA_ "VssSig" SG_ 2566908449 SafeWrkSideNear "Mch.MCU.MWIG.SafeWrkSideNear";
BA_ "VssSig" SG_ 2566908449 SafeWrkFrFar "Mch.MCU.MWIG.SafeWrkFrFar";
BA_ "VssSig" SG_ 2566908449 SafeWrkFrMid "Mch.MCU.MWIG.SafeWrkFrMid";
BA_ "VssSig" SG_ 2566908449 SafeWrkFrNear "Mch.MCU.MWIG.SafeWrkFrNear";
BA_ "VssSig" SG_ 2566908449 FrMvGuidArmOut "Mch.MCU.MWIG.FrMvGuidArmOut";
BA_ "VssSig" SG_ 2566908449 FrMvGuidArmIn "Mch.MCU.MWIG.FrMvGuidArmIn";
BA_ "VssSig" SG_ 2566908449 FrMvGuidBoomDn "Mch.MCU.MWIG.FrMvGuidBoomDn";
BA_ "VssSig" SG_ 2566908449 FrMvGuidBoomUp "Mch.MCU.MWIG.FrMvGuidBoomUp";
BA_ "VssSig" SG_ 2566908449 EfenceTrkWrn "Mch.MCU.MWIG.EfenceTrkWrn";
BA_ "VssSig" SG_ 2566908449 EfenceDzWrn "Mch.MCU.MWIG.EfenceDzWrn";
BA_ "VssSig" SG_ 2566908449 EfenceCabWrn "Mch.MCU.MWIG.EfenceCabWrn";
BA_ "VssSig" SG_ 2566908449 EfenceFSwgRhWrn "Mch.MCU.MWIG.EfenceFSwgRhWrn";
BA_ "VssSig" SG_ 2566908449 EfenceFSwgLhWrn "Mch.MCU.MWIG.EfenceFSwgLhWrn";
BA_ "VssSig" SG_ 2566908449 EfenceCeilWrn "Mch.MCU.MWIG.EfenceCeilWrn";
BA_ "VssSig" SG_ 2566908449 EfenceFloorWrn "Mch.MCU.MWIG.EfenceFloorWrn";
BA_ "VssSig" SG_ 2566908449 EfenceWallWrn "Mch.MCU.MWIG.EfenceWallWrn";
BA_ "VssSig" SG_ 2566908705 TotWhgCurTrk "Mch.MCU.TWG.TotWhgCurTrk";
BA_ "VssSig" SG_ 2566908705 BckCntCurTrk "Mch.MCU.TWG.BckCntCurTrk";
BA_ "VssSig" SG_ 2566908705 WghCntSt "Mch.MCU.TWG.WghCntSt";
BA_ "VssSig" SG_ 2566908705 WghSt "Mch.MCU.TWG.WghSt";
BA_ "VssSig" SG_ 2566908705 RelTmBckWhg "Mch.MCU.TWG.RelTmBckWhg";
BA_ "VssSig" SG_ 2566908961 BckZeroCalbStep "Mch.MCU.WCPR.BckZeroCalbStep";
BA_ "VssSig" SG_ 2566908961 BckZeroCalbStage "Mch.MCU.WCPR.BckZeroCalbStage";
BA_ "VssSig" SG_ 2566908961 FrMultiCalbStep "Mch.MCU.WCPR.FrMultiCalbStep";
BA_ "VssSig" SG_ 2566908961 FrMultiCalbStage "Mch.MCU.WCPR.FrMultiCalbStage";
BA_ "VssSig" SG_ 2566908961 FrSngCalbStep "Mch.MCU.WCPR.FrSngCalbStep";
BA_ "VssSig" SG_ 2566908961 FrSngCalbStage "Mch.MCU.WCPR.FrSngCalbStage";
BA_ "VssSig" SG_ 2566909217 TgtArmCylSpdUpLmt "Mch.MCU.WCCV.TgtArmCylSpdUpLmt";
BA_ "VssSig" SG_ 2566909217 TgtArmCylSpdLwLmt "Mch.MCU.WCCV.TgtArmCylSpdLwLmt";
BA_ "VssSig" SG_ 2566909217 CurArmCylSpd "Mch.MCU.WCCV.CurArmCylSpd";
BA_ "VssSig" SG_ 2566909217 TgtBoomCylSpdUpLmt "Mch.MCU.WCCV.TgtBoomCylSpdUpLmt";
BA_ "VssSig" SG_ 2566909217 TgtBoomCylSpdLwLmt "Mch.MCU.WCCV.TgtBoomCylSpdLwLmt";
BA_ "VssSig" SG_ 2566909217 CurBoomCylSpd "Mch.MCU.WCCV.CurBoomCylSpd";
BA_ "VssSig" SG_ 2566909473 TgtArmJointAngEndPos "Mch.MCU.WCJA.TgtArmJointAngEndPos";
BA_ "VssSig" SG_ 2566909473 TgtArmJointAngStartPos "Mch.MCU.WCJA.TgtArmJointAngStartPos";
BA_ "VssSig" SG_ 2566909473 CurArmJointAng "Mch.MCU.WCJA.CurArmJointAng";
BA_ "VssSig" SG_ 2566909473 TgtBoomJointAngEndPos "Mch.MCU.WCJA.TgtBoomJointAngEndPos";
BA_ "VssSig" SG_ 2566909473 TgtBoomJointAngStartPos "Mch.MCU.WCJA.TgtBoomJointAngStartPos";
BA_ "VssSig" SG_ 2566909473 CurBoomJointAng "Mch.MCU.WCJA.CurBoomJointAng";
BA_ "VssSig" SG_ 2566909729 Reach "Mch.MCU.LADG.Reach";
BA_ "VssSig" SG_ 2566909729 Hight "Mch.MCU.LADG.Hight";
BA_ "VssSig" SG_ 2566909729 RatedLoad "Mch.MCU.LADG.RatedLoad";
BA_ "VssSig" SG_ 2566909729 ActLoad "Mch.MCU.LADG.ActLoad";
BA_ "VssSig" SG_ 2566910241 SwgAng "Mch.MCU.ASRG.SwgAng";
BA_ "VssSig" SG_ 2566912289 SsOfsRttAng "Mch.MCU.MWHG4.SsOfsRttAng";
BA_ "VssSig" SG_ 2566912289 ImuSsOfsTrttTiltAng "Mch.MCU.MWHG4.ImuSsOfsTrttTiltAng";
BA_ "VssSig" SG_ 2566912289 TrttBodyDmsnTQ4 "Mch.MCU.MWHG4.TrttBodyDmsnTQ4";
BA_ "VssSig" SG_ 2566912289 TrttBodyDmsnDQ4 "Mch.MCU.MWHG4.TrttBodyDmsnDQ4";
BA_ "VssSig" SG_ 2566912289 TrttBodyDmsnAngGdt "Mch.MCU.MWHG4.TrttBodyDmsnAngGdt";
BA_ "VssSig" SG_ 2566912289 TrttBodyDmsnDT "Mch.MCU.MWHG4.TrttBodyDmsnDT";
BA_ "VssSig" SG_ 2566912289 TrttBodyDmsnGT "Mch.MCU.MWHG4.TrttBodyDmsnGT";
BA_ "VssSig" SG_ 2566912289 TrttBodyDmsnDG "Mch.MCU.MWHG4.TrttBodyDmsnDG";
BA_ "VssSig" SG_ 2566912289 TrttBodyDmsnVW "Mch.MCU.MWHG4.TrttBodyDmsnVW";
BA_ "VssSig" SG_ 2566912289 TrttBodyDmsnUV "Mch.MCU.MWHG4.TrttBodyDmsnUV";
BA_ "VssSig" SG_ 2566912289 TrttBodyDmsnTU "Mch.MCU.MWHG4.TrttBodyDmsnTU";
BA_ "VssSig" SG_ 2566912289 TrttBck05DmsnAngVwn "Mch.MCU.MWHG4.TrttBck05DmsnAngVwn";
BA_ "VssSig" SG_ 2566912289 TrttBck05DmsnTN "Mch.MCU.MWHG4.TrttBck05DmsnTN";
BA_ "VssSig" SG_ 2566912289 TrttBck05DmsnWN "Mch.MCU.MWHG4.TrttBck05DmsnWN";
BA_ "VssSig" SG_ 2566912289 TrttBck05DmsnWT "Mch.MCU.MWHG4.TrttBck05DmsnWT";
BA_ "VssSig" SG_ 2566912289 TrttBck05DmsnNQ3 "Mch.MCU.MWHG4.TrttBck05DmsnNQ3";
BA_ "VssSig" SG_ 2566912289 TrttBck05DmsnWQ3 "Mch.MCU.MWHG4.TrttBck05DmsnWQ3";
BA_ "VssSig" SG_ 2566912289 TrttBck05DmsnNQ2 "Mch.MCU.MWHG4.TrttBck05DmsnNQ2";
BA_ "VssSig" SG_ 2566912289 TrttBck05DmsnWQ2 "Mch.MCU.MWHG4.TrttBck05DmsnWQ2";
BA_ "VssSig" SG_ 2566912289 TrttBck05DmsnWidth "Mch.MCU.MWHG4.TrttBck05DmsnWidth";
BA_ "VssSig" SG_ 2566912289 TrttBck05DmsnNQ1 "Mch.MCU.MWHG4.TrttBck05DmsnNQ1";
BA_ "VssSig" SG_ 2566912289 TrttBck05DmsnWQ1 "Mch.MCU.MWHG4.TrttBck05DmsnWQ1";
BA_ "VssSig" SG_ 2566912289 TrttBck04DmsnAngVwn "Mch.MCU.MWHG4.TrttBck04DmsnAngVwn";
BA_ "VssSig" SG_ 2566912289 TrttBck04DmsnTN "Mch.MCU.MWHG4.TrttBck04DmsnTN";
BA_ "VssSig" SG_ 2566912289 TrttBck04DmsnWN "Mch.MCU.MWHG4.TrttBck04DmsnWN";
BA_ "VssSig" SG_ 2566912289 TrttBck04DmsnWT "Mch.MCU.MWHG4.TrttBck04DmsnWT";
BA_ "VssSig" SG_ 2566912289 TrttBck04DmsnNQ3 "Mch.MCU.MWHG4.TrttBck04DmsnNQ3";
BA_ "VssSig" SG_ 2566912289 TrttBck04DmsnWQ3 "Mch.MCU.MWHG4.TrttBck04DmsnWQ3";
BA_ "VssSig" SG_ 2566912289 TrttBck04DmsnNQ2 "Mch.MCU.MWHG4.TrttBck04DmsnNQ2";
BA_ "VssSig" SG_ 2566912289 TrttBck04DmsnWQ2 "Mch.MCU.MWHG4.TrttBck04DmsnWQ2";
BA_ "VssSig" SG_ 2566912289 TrttBck04DmsnWidth "Mch.MCU.MWHG4.TrttBck04DmsnWidth";
BA_ "VssSig" SG_ 2566912289 TrttBck04DmsnNQ1 "Mch.MCU.MWHG4.TrttBck04DmsnNQ1";
BA_ "VssSig" SG_ 2566912289 TrttBck04DmsnWQ1 "Mch.MCU.MWHG4.TrttBck04DmsnWQ1";
BA_ "VssSig" SG_ 2566912289 TrttBck03DmsnAngVwn "Mch.MCU.MWHG4.TrttBck03DmsnAngVwn";
BA_ "VssSig" SG_ 2566912289 TrttBck03DmsnTN "Mch.MCU.MWHG4.TrttBck03DmsnTN";
BA_ "VssSig" SG_ 2566912289 TrttBck03DmsnWN "Mch.MCU.MWHG4.TrttBck03DmsnWN";
BA_ "VssSig" SG_ 2566912289 TrttBck03DmsnWT "Mch.MCU.MWHG4.TrttBck03DmsnWT";
BA_ "VssSig" SG_ 2566912289 TrttBck03DmsnNQ3 "Mch.MCU.MWHG4.TrttBck03DmsnNQ3";
BA_ "VssSig" SG_ 2566912289 TrttBck03DmsnWQ3 "Mch.MCU.MWHG4.TrttBck03DmsnWQ3";
BA_ "VssSig" SG_ 2566912289 TrttBck03DmsnNQ2 "Mch.MCU.MWHG4.TrttBck03DmsnNQ2";
BA_ "VssSig" SG_ 2566912289 TrttBck03DmsnWQ2 "Mch.MCU.MWHG4.TrttBck03DmsnWQ2";
BA_ "VssSig" SG_ 2566912289 TrttBck03DmsnWidth "Mch.MCU.MWHG4.TrttBck03DmsnWidth";
BA_ "VssSig" SG_ 2566912289 TrttBck03DmsnNQ1 "Mch.MCU.MWHG4.TrttBck03DmsnNQ1";
BA_ "VssSig" SG_ 2566912289 TrttBck03DmsnWQ1 "Mch.MCU.MWHG4.TrttBck03DmsnWQ1";
BA_ "VssSig" SG_ 2566912289 TrttBck02DmsnAngVwn "Mch.MCU.MWHG4.TrttBck02DmsnAngVwn";
BA_ "VssSig" SG_ 2566912289 TrttBck02DmsnTN "Mch.MCU.MWHG4.TrttBck02DmsnTN";
BA_ "VssSig" SG_ 2566912289 TrttBck02DmsnWN "Mch.MCU.MWHG4.TrttBck02DmsnWN";
BA_ "VssSig" SG_ 2566912289 TrttBck02DmsnWT "Mch.MCU.MWHG4.TrttBck02DmsnWT";
BA_ "VssSig" SG_ 2566912289 TrttBck02DmsnNQ3 "Mch.MCU.MWHG4.TrttBck02DmsnNQ3";
BA_ "VssSig" SG_ 2566912289 TrttBck02DmsnWQ3 "Mch.MCU.MWHG4.TrttBck02DmsnWQ3";
BA_ "VssSig" SG_ 2566912289 TrttBck02DmsnNQ2 "Mch.MCU.MWHG4.TrttBck02DmsnNQ2";
BA_ "VssSig" SG_ 2566912289 TrttBck02DmsnWQ2 "Mch.MCU.MWHG4.TrttBck02DmsnWQ2";
BA_ "VssSig" SG_ 2566912289 TrttBck02DmsnWidth "Mch.MCU.MWHG4.TrttBck02DmsnWidth";
BA_ "VssSig" SG_ 2566912289 TrttBck02DmsnNQ1 "Mch.MCU.MWHG4.TrttBck02DmsnNQ1";
BA_ "VssSig" SG_ 2566912289 TrttBck02DmsnWQ1 "Mch.MCU.MWHG4.TrttBck02DmsnWQ1";
BA_ "VssSig" SG_ 2566912289 TrttBck01DmsnAngVwn "Mch.MCU.MWHG4.TrttBck01DmsnAngVwn";
BA_ "VssSig" SG_ 2566912289 TrttBck01DmsnTN "Mch.MCU.MWHG4.TrttBck01DmsnTN";
BA_ "VssSig" SG_ 2566912289 TrttBck01DmsnWN "Mch.MCU.MWHG4.TrttBck01DmsnWN";
BA_ "VssSig" SG_ 2566912289 TrttBck01DmsnWT "Mch.MCU.MWHG4.TrttBck01DmsnWT";
BA_ "VssSig" SG_ 2566912289 TrttBck01DmsnNQ3 "Mch.MCU.MWHG4.TrttBck01DmsnNQ3";
BA_ "VssSig" SG_ 2566912289 TrttBck01DmsnWQ3 "Mch.MCU.MWHG4.TrttBck01DmsnWQ3";
BA_ "VssSig" SG_ 2566912289 TrttBck01DmsnNQ2 "Mch.MCU.MWHG4.TrttBck01DmsnNQ2";
BA_ "VssSig" SG_ 2566912289 TrttBck01DmsnWQ2 "Mch.MCU.MWHG4.TrttBck01DmsnWQ2";
BA_ "VssSig" SG_ 2566912289 TrttBck01DmsnWidth "Mch.MCU.MWHG4.TrttBck01DmsnWidth";
BA_ "VssSig" SG_ 2566912289 TrttBck01DmsnNQ1 "Mch.MCU.MWHG4.TrttBck01DmsnNQ1";
BA_ "VssSig" SG_ 2566912289 TrttBck01DmsnWQ1 "Mch.MCU.MWHG4.TrttBck01DmsnWQ1";
BA_ "VssSig" SG_ 2566912545 Bck05DmsnAngGdn "Mch.MCU.MWHG1.Bck05DmsnAngGdn";
BA_ "VssSig" SG_ 2566912545 Bck05DmsnDT "Mch.MCU.MWHG1.Bck05DmsnDT";
BA_ "VssSig" SG_ 2566912545 Bck05DmsnNQ3 "Mch.MCU.MWHG1.Bck05DmsnNQ3";
BA_ "VssSig" SG_ 2566912545 Bck05DmsnDQ3 "Mch.MCU.MWHG1.Bck05DmsnDQ3";
BA_ "VssSig" SG_ 2566912545 Bck05DmsnNQ2 "Mch.MCU.MWHG1.Bck05DmsnNQ2";
BA_ "VssSig" SG_ 2566912545 Bck05DmsnDQ2 "Mch.MCU.MWHG1.Bck05DmsnDQ2";
BA_ "VssSig" SG_ 2566912545 Bck05DmsnTN "Mch.MCU.MWHG1.Bck05DmsnTN";
BA_ "VssSig" SG_ 2566912545 Bck05DmsnWidth "Mch.MCU.MWHG1.Bck05DmsnWidth";
BA_ "VssSig" SG_ 2566912545 Bck05DmsnNQ1 "Mch.MCU.MWHG1.Bck05DmsnNQ1";
BA_ "VssSig" SG_ 2566912545 Bck05DmsnDQ1 "Mch.MCU.MWHG1.Bck05DmsnDQ1";
BA_ "VssSig" SG_ 2566912545 Bck05DmsnDN "Mch.MCU.MWHG1.Bck05DmsnDN";
BA_ "VssSig" SG_ 2566912545 Bck05DmsnDG "Mch.MCU.MWHG1.Bck05DmsnDG";
BA_ "VssSig" SG_ 2566912545 Bck04DmsnAngGdn "Mch.MCU.MWHG1.Bck04DmsnAngGdn";
BA_ "VssSig" SG_ 2566912545 Bck04DmsnDT "Mch.MCU.MWHG1.Bck04DmsnDT";
BA_ "VssSig" SG_ 2566912545 Bck04DmsnNQ3 "Mch.MCU.MWHG1.Bck04DmsnNQ3";
BA_ "VssSig" SG_ 2566912545 Bck04DmsnDQ3 "Mch.MCU.MWHG1.Bck04DmsnDQ3";
BA_ "VssSig" SG_ 2566912545 Bck04DmsnNQ2 "Mch.MCU.MWHG1.Bck04DmsnNQ2";
BA_ "VssSig" SG_ 2566912545 Bck04DmsnDQ2 "Mch.MCU.MWHG1.Bck04DmsnDQ2";
BA_ "VssSig" SG_ 2566912545 Bck04DmsnTN "Mch.MCU.MWHG1.Bck04DmsnTN";
BA_ "VssSig" SG_ 2566912545 Bck04DmsnWidth "Mch.MCU.MWHG1.Bck04DmsnWidth";
BA_ "VssSig" SG_ 2566912545 Bck04DmsnNQ1 "Mch.MCU.MWHG1.Bck04DmsnNQ1";
BA_ "VssSig" SG_ 2566912545 Bck04DmsnDQ1 "Mch.MCU.MWHG1.Bck04DmsnDQ1";
BA_ "VssSig" SG_ 2566912545 Bck04DmsnDN "Mch.MCU.MWHG1.Bck04DmsnDN";
BA_ "VssSig" SG_ 2566912545 Bck04DmsnDG "Mch.MCU.MWHG1.Bck04DmsnDG";
BA_ "VssSig" SG_ 2566912545 Bck03DmsnAngGdn "Mch.MCU.MWHG1.Bck03DmsnAngGdn";
BA_ "VssSig" SG_ 2566912545 Bck03DmsnDT "Mch.MCU.MWHG1.Bck03DmsnDT";
BA_ "VssSig" SG_ 2566912545 Bck03DmsnNQ3 "Mch.MCU.MWHG1.Bck03DmsnNQ3";
BA_ "VssSig" SG_ 2566912545 Bck03DmsnDQ3 "Mch.MCU.MWHG1.Bck03DmsnDQ3";
BA_ "VssSig" SG_ 2566912545 Bck03DmsnNQ2 "Mch.MCU.MWHG1.Bck03DmsnNQ2";
BA_ "VssSig" SG_ 2566912545 Bck03DmsnDQ2 "Mch.MCU.MWHG1.Bck03DmsnDQ2";
BA_ "VssSig" SG_ 2566912545 Bck03DmsnTN "Mch.MCU.MWHG1.Bck03DmsnTN";
BA_ "VssSig" SG_ 2566912545 Bck03DmsnWidth "Mch.MCU.MWHG1.Bck03DmsnWidth";
BA_ "VssSig" SG_ 2566912545 Bck03DmsnNQ1 "Mch.MCU.MWHG1.Bck03DmsnNQ1";
BA_ "VssSig" SG_ 2566912545 Bck03DmsnDQ1 "Mch.MCU.MWHG1.Bck03DmsnDQ1";
BA_ "VssSig" SG_ 2566912545 Bck03DmsnDN "Mch.MCU.MWHG1.Bck03DmsnDN";
BA_ "VssSig" SG_ 2566912545 Bck03DmsnDG "Mch.MCU.MWHG1.Bck03DmsnDG";
BA_ "VssSig" SG_ 2566912545 Bck02DmsnAngGdn "Mch.MCU.MWHG1.Bck02DmsnAngGdn";
BA_ "VssSig" SG_ 2566912545 Bck02DmsnDT "Mch.MCU.MWHG1.Bck02DmsnDT";
BA_ "VssSig" SG_ 2566912545 Bck02DmsnNQ3 "Mch.MCU.MWHG1.Bck02DmsnNQ3";
BA_ "VssSig" SG_ 2566912545 Bck02DmsnDQ3 "Mch.MCU.MWHG1.Bck02DmsnDQ3";
BA_ "VssSig" SG_ 2566912545 Bck02DmsnNQ2 "Mch.MCU.MWHG1.Bck02DmsnNQ2";
BA_ "VssSig" SG_ 2566912545 Bck02DmsnDQ2 "Mch.MCU.MWHG1.Bck02DmsnDQ2";
BA_ "VssSig" SG_ 2566912545 Bck02DmsnTN "Mch.MCU.MWHG1.Bck02DmsnTN";
BA_ "VssSig" SG_ 2566912545 Bck02DmsnWidth "Mch.MCU.MWHG1.Bck02DmsnWidth";
BA_ "VssSig" SG_ 2566912545 Bck02DmsnNQ1 "Mch.MCU.MWHG1.Bck02DmsnNQ1";
BA_ "VssSig" SG_ 2566912545 Bck02DmsnDQ1 "Mch.MCU.MWHG1.Bck02DmsnDQ1";
BA_ "VssSig" SG_ 2566912545 Bck02DmsnDN "Mch.MCU.MWHG1.Bck02DmsnDN";
BA_ "VssSig" SG_ 2566912545 Bck02DmsnDG "Mch.MCU.MWHG1.Bck02DmsnDG";
BA_ "VssSig" SG_ 2566912545 Bck01DmsnAngGdn "Mch.MCU.MWHG1.Bck01DmsnAngGdn";
BA_ "VssSig" SG_ 2566912545 Bck01DmsnDT "Mch.MCU.MWHG1.Bck01DmsnDT";
BA_ "VssSig" SG_ 2566912545 Bck01DmsnNQ3 "Mch.MCU.MWHG1.Bck01DmsnNQ3";
BA_ "VssSig" SG_ 2566912545 Bck01DmsnDQ3 "Mch.MCU.MWHG1.Bck01DmsnDQ3";
BA_ "VssSig" SG_ 2566912545 Bck01DmsnNQ2 "Mch.MCU.MWHG1.Bck01DmsnNQ2";
BA_ "VssSig" SG_ 2566912545 Bck01DmsnDQ2 "Mch.MCU.MWHG1.Bck01DmsnDQ2";
BA_ "VssSig" SG_ 2566912545 Bck01DmsnTN "Mch.MCU.MWHG1.Bck01DmsnTN";
BA_ "VssSig" SG_ 2566912545 Bck01DmsnWidth "Mch.MCU.MWHG1.Bck01DmsnWidth";
BA_ "VssSig" SG_ 2566912545 Bck01DmsnNQ1 "Mch.MCU.MWHG1.Bck01DmsnNQ1";
BA_ "VssSig" SG_ 2566912545 Bck01DmsnDQ1 "Mch.MCU.MWHG1.Bck01DmsnDQ1";
BA_ "VssSig" SG_ 2566912545 Bck01DmsnDN "Mch.MCU.MWHG1.Bck01DmsnDN";
BA_ "VssSig" SG_ 2566912545 Bck01DmsnDG "Mch.MCU.MWHG1.Bck01DmsnDG";
BA_ "VssSig" SG_ 2566912801 DacCoordinateSystem "Mch.MCU.MWHG2.DacCoordinateSystem";
BA_ "VssSig" SG_ 2566912801 DacAutoMdSelect "Mch.MCU.MWHG2.DacAutoMdSelect";
BA_ "VssSig" SG_ 2566912801 CrwTipCalbLen "Mch.MCU.MWHG2.CrwTipCalbLen";
BA_ "VssSig" SG_ 2566912801 ImuSsOfsBladeRoll "Mch.MCU.MWHG2.ImuSsOfsBladeRoll";
BA_ "VssSig" SG_ 2566912801 ImuSsOfsBladePch "Mch.MCU.MWHG2.ImuSsOfsBladePch";
BA_ "VssSig" SG_ 2566912801 ImuSsOfsCfrmRoll "Mch.MCU.MWHG2.ImuSsOfsCfrmRoll";
BA_ "VssSig" SG_ 2566912801 ImuSsOfsCfrmPch "Mch.MCU.MWHG2.ImuSsOfsCfrmPch";
BA_ "VssSig" SG_ 2566912801 BladeTipCalbLen "Mch.MCU.MWHG2.BladeTipCalbLen";
BA_ "VssSig" SG_ 2566912801 BladeJointCalbLen "Mch.MCU.MWHG2.BladeJointCalbLen";
BA_ "VssSig" SG_ 2566912801 GrdAstPrfDsnDt01PntZ09 "Mch.MCU.MWHG2.GrdAstPrfDsnDt01PntZ09";
BA_ "VssSig" SG_ 2566912801 GrdAstPrfDsnDt01PntY09 "Mch.MCU.MWHG2.GrdAstPrfDsnDt01PntY09";
BA_ "VssSig" SG_ 2566912801 GrdAstPrfDsnDt01PntZ08 "Mch.MCU.MWHG2.GrdAstPrfDsnDt01PntZ08";
BA_ "VssSig" SG_ 2566912801 GrdAstPrfDsnDt01PntY08 "Mch.MCU.MWHG2.GrdAstPrfDsnDt01PntY08";
BA_ "VssSig" SG_ 2566912801 GrdAstPrfDsnDt01PntZ07 "Mch.MCU.MWHG2.GrdAstPrfDsnDt01PntZ07";
BA_ "VssSig" SG_ 2566912801 GrdAstPrfDsnDt01PntY07 "Mch.MCU.MWHG2.GrdAstPrfDsnDt01PntY07";
BA_ "VssSig" SG_ 2566912801 GrdAstPrfDsnDt01PntZ06 "Mch.MCU.MWHG2.GrdAstPrfDsnDt01PntZ06";
BA_ "VssSig" SG_ 2566912801 GrdAstPrfDsnDt01PntY06 "Mch.MCU.MWHG2.GrdAstPrfDsnDt01PntY06";
BA_ "VssSig" SG_ 2566912801 GrdAstPrfDsnDt01PntZ05 "Mch.MCU.MWHG2.GrdAstPrfDsnDt01PntZ05";
BA_ "VssSig" SG_ 2566912801 GrdAstPrfDsnDt01PntY05 "Mch.MCU.MWHG2.GrdAstPrfDsnDt01PntY05";
BA_ "VssSig" SG_ 2566912801 GrdAstPrfDsnDt01PntZ04 "Mch.MCU.MWHG2.GrdAstPrfDsnDt01PntZ04";
BA_ "VssSig" SG_ 2566912801 GrdAstPrfDsnDt01PntY04 "Mch.MCU.MWHG2.GrdAstPrfDsnDt01PntY04";
BA_ "VssSig" SG_ 2566912801 GrdAstPrfDsnDt01PntZ03 "Mch.MCU.MWHG2.GrdAstPrfDsnDt01PntZ03";
BA_ "VssSig" SG_ 2566912801 GrdAstPrfDsnDt01PntY03 "Mch.MCU.MWHG2.GrdAstPrfDsnDt01PntY03";
BA_ "VssSig" SG_ 2566912801 GrdAstPrfDsnDt01PntZ02 "Mch.MCU.MWHG2.GrdAstPrfDsnDt01PntZ02";
BA_ "VssSig" SG_ 2566912801 GrdAstPrfDsnDt01PntY02 "Mch.MCU.MWHG2.GrdAstPrfDsnDt01PntY02";
BA_ "VssSig" SG_ 2566912801 GrdAstPrfDsnDt01PntZ01 "Mch.MCU.MWHG2.GrdAstPrfDsnDt01PntZ01";
BA_ "VssSig" SG_ 2566912801 GrdAstPrfDsnDt01PntY01 "Mch.MCU.MWHG2.GrdAstPrfDsnDt01PntY01";
BA_ "VssSig" SG_ 2566912801 CrossSlopeDsnDt "Mch.MCU.MWHG2.CrossSlopeDsnDt";
BA_ "VssSig" SG_ 2566912801 SlopeDsnDt "Mch.MCU.MWHG2.SlopeDsnDt";
BA_ "VssSig" SG_ 2566912801 DepthDsnDt "Mch.MCU.MWHG2.DepthDsnDt";
BA_ "VssSig" SG_ 2566912801 JoyFuncAssnRhThmbWhl05 "Mch.MCU.MWHG2.JoyFuncAssnRhThmbWhl05";
BA_ "VssSig" SG_ 2566912801 JoyFuncAssnRhThmbWhl04 "Mch.MCU.MWHG2.JoyFuncAssnRhThmbWhl04";
BA_ "VssSig" SG_ 2566912801 JoyFuncAssnRhThmbWhl03 "Mch.MCU.MWHG2.JoyFuncAssnRhThmbWhl03";
BA_ "VssSig" SG_ 2566912801 JoyFuncAssnRhThmbWhl02 "Mch.MCU.MWHG2.JoyFuncAssnRhThmbWhl02";
BA_ "VssSig" SG_ 2566912801 JoyFuncAssnRhThmbWhl01 "Mch.MCU.MWHG2.JoyFuncAssnRhThmbWhl01";
BA_ "VssSig" SG_ 2566912801 JoyFuncAssnLhThmbWhl05 "Mch.MCU.MWHG2.JoyFuncAssnLhThmbWhl05";
BA_ "VssSig" SG_ 2566912801 JoyFuncAssnLhThmbWhl04 "Mch.MCU.MWHG2.JoyFuncAssnLhThmbWhl04";
BA_ "VssSig" SG_ 2566912801 JoyFuncAssnLhThmbWhl03 "Mch.MCU.MWHG2.JoyFuncAssnLhThmbWhl03";
BA_ "VssSig" SG_ 2566912801 JoyFuncAssnLhThmbWhl02 "Mch.MCU.MWHG2.JoyFuncAssnLhThmbWhl02";
BA_ "VssSig" SG_ 2566912801 JoyFuncAssnLhThmbWhl01 "Mch.MCU.MWHG2.JoyFuncAssnLhThmbWhl01";
BA_ "VssSig" SG_ 2566912801 JoyFuncAssnRhBtn10 "Mch.MCU.MWHG2.JoyFuncAssnRhBtn10";
BA_ "VssSig" SG_ 2566912801 JoyFuncAssnRhBtn09 "Mch.MCU.MWHG2.JoyFuncAssnRhBtn09";
BA_ "VssSig" SG_ 2566912801 JoyFuncAssnRhBtn08 "Mch.MCU.MWHG2.JoyFuncAssnRhBtn08";
BA_ "VssSig" SG_ 2566912801 JoyFuncAssnRhBtn07 "Mch.MCU.MWHG2.JoyFuncAssnRhBtn07";
BA_ "VssSig" SG_ 2566912801 JoyFuncAssnRhBtn06 "Mch.MCU.MWHG2.JoyFuncAssnRhBtn06";
BA_ "VssSig" SG_ 2566912801 JoyFuncAssnRhBtn05 "Mch.MCU.MWHG2.JoyFuncAssnRhBtn05";
BA_ "VssSig" SG_ 2566912801 JoyFuncAssnRhBtn04 "Mch.MCU.MWHG2.JoyFuncAssnRhBtn04";
BA_ "VssSig" SG_ 2566912801 JoyFuncAssnRhBtn03 "Mch.MCU.MWHG2.JoyFuncAssnRhBtn03";
BA_ "VssSig" SG_ 2566912801 JoyFuncAssnRhBtn02 "Mch.MCU.MWHG2.JoyFuncAssnRhBtn02";
BA_ "VssSig" SG_ 2566912801 JoyFuncAssnRhBtn01 "Mch.MCU.MWHG2.JoyFuncAssnRhBtn01";
BA_ "VssSig" SG_ 2566912801 JoyFuncAssnLhBtn10 "Mch.MCU.MWHG2.JoyFuncAssnLhBtn10";
BA_ "VssSig" SG_ 2566912801 JoyFuncAssnLhBtn09 "Mch.MCU.MWHG2.JoyFuncAssnLhBtn09";
BA_ "VssSig" SG_ 2566912801 JoyFuncAssnLhBtn08 "Mch.MCU.MWHG2.JoyFuncAssnLhBtn08";
BA_ "VssSig" SG_ 2566912801 JoyFuncAssnLhBtn07 "Mch.MCU.MWHG2.JoyFuncAssnLhBtn07";
BA_ "VssSig" SG_ 2566912801 JoyFuncAssnLhBtn06 "Mch.MCU.MWHG2.JoyFuncAssnLhBtn06";
BA_ "VssSig" SG_ 2566912801 JoyFuncAssnLhBtn05 "Mch.MCU.MWHG2.JoyFuncAssnLhBtn05";
BA_ "VssSig" SG_ 2566912801 JoyFuncAssnLhBtn04 "Mch.MCU.MWHG2.JoyFuncAssnLhBtn04";
BA_ "VssSig" SG_ 2566912801 JoyFuncAssnLhBtn03 "Mch.MCU.MWHG2.JoyFuncAssnLhBtn03";
BA_ "VssSig" SG_ 2566912801 JoyFuncAssnLhBtn02 "Mch.MCU.MWHG2.JoyFuncAssnLhBtn02";
BA_ "VssSig" SG_ 2566912801 JoyFuncAssnLhBtn01 "Mch.MCU.MWHG2.JoyFuncAssnLhBtn01";
BA_ "VssSig" SG_ 2566912801 ImuSsOfsBucket "Mch.MCU.MWHG2.ImuSsOfsBucket";
BA_ "VssSig" SG_ 2566912801 ImuSsOfsArtiArmPch "Mch.MCU.MWHG2.ImuSsOfsArtiArmPch";
BA_ "VssSig" SG_ 2566912801 ImuSsOfsArmPch "Mch.MCU.MWHG2.ImuSsOfsArmPch";
BA_ "VssSig" SG_ 2566912801 ImuSsOfsBoomPch "Mch.MCU.MWHG2.ImuSsOfsBoomPch";
BA_ "VssSig" SG_ 2566912801 ImuSsOfsBodyRoll "Mch.MCU.MWHG2.ImuSsOfsBodyRoll";
BA_ "VssSig" SG_ 2566912801 ImuSsOfsBodyPch "Mch.MCU.MWHG2.ImuSsOfsBodyPch";
BA_ "VssSig" SG_ 2566912801 SelectedBucketNo "Mch.MCU.MWHG2.SelectedBucketNo";
BA_ "VssSig" SG_ 2566913057 MaterialName "Mch.MCU.MWHG3.MaterialName";
BA_ "VssSig" SG_ 2566913057 TrkName "Mch.MCU.MWHG3.TrkName";
BA_ "VssSig" SG_ 2566913057 BchmkZOfs "Mch.MCU.MWHG3.BchmkZOfs";
BA_ "VssSig" SG_ 2566913057 BchmkYOfs "Mch.MCU.MWHG3.BchmkYOfs";
BA_ "VssSig" SG_ 2566913057 BchmkXOfs "Mch.MCU.MWHG3.BchmkXOfs";
BA_ "VssSig" SG_ 2566913057 TrkCount "Mch.MCU.MWHG3.TrkCount";
BA_ "VssSig" SG_ 2566913057 SelMaterialDensity "Mch.MCU.MWHG3.SelMaterialDensity";
BA_ "VssSig" SG_ 2566913057 SelTrkTgtWgh "Mch.MCU.MWHG3.SelTrkTgtWgh";
BA_ "VssSig" SG_ 2566913057 BckRefPnt "Mch.MCU.MWHG3.BckRefPnt";
BA_ "VssSig" SG_ 2566913057 ArtiBoomDmsnOpt "Mch.MCU.MWHG3.ArtiBoomDmsnOpt";
BA_ "VssSig" SG_ 2566913057 ArmDmsnOpt "Mch.MCU.MWHG3.ArmDmsnOpt";
BA_ "VssSig" SG_ 2566913057 BoomDmsnOpt "Mch.MCU.MWHG3.BoomDmsnOpt";
BA_ "VssSig" SG_ 2566913057 GrdAstMd "Mch.MCU.MWHG3.GrdAstMd";
BA_ "VssSig" SG_ 2566913057 GrdAstAccuracy "Mch.MCU.MWHG3.GrdAstAccuracy";
BA_ "VssSig" SG_ 2566913057 TrkShoeWidth "Mch.MCU.MWHG3.TrkShoeWidth";
BA_ "VssSig" SG_ 2566913313 SwgAstAngTgtSetSwgLh "Mch.MCU.MWTSV.SwgAstAngTgtSetSwgLh";
BA_ "VssSig" SG_ 2566913313 SwgAstAngTgtSetSwgRh "Mch.MCU.MWTSV.SwgAstAngTgtSetSwgRh";
BA_ "VssSig" SG_ 2566913313 EfenceTgtSetSwgRh "Mch.MCU.MWTSV.EfenceTgtSetSwgRh";
BA_ "VssSig" SG_ 2566913313 EfenceTgtSetSwgLh "Mch.MCU.MWTSV.EfenceTgtSetSwgLh";
BA_ "VssSig" SG_ 2566913313 EfenceTgtSetCeil "Mch.MCU.MWTSV.EfenceTgtSetCeil";
BA_ "VssSig" SG_ 2566913313 EfenceTgtSetFloor "Mch.MCU.MWTSV.EfenceTgtSetFloor";
BA_ "VssSig" SG_ 2566913313 EfenceTgtSetWall "Mch.MCU.MWTSV.EfenceTgtSetWall";
BA_ "VssSig" SG_ 2566913569 MaterialLoadSt "Mch.MCU.MTSI.MaterialLoadSt";
BA_ "VssSig" SG_ 2566913569 TotWghCurtrk "Mch.MCU.MTSI.TotWghCurtrk";
BA_ "VssSig" SG_ 2566913569 BckCntCurtrk "Mch.MCU.MTSI.BckCntCurtrk";
BA_ "VssSig" SG_ 2566913569 SelMaterialDensity "Mch.MCU.MTSI.SelMaterialDensity";
BA_ "VssSig" SG_ 2566913569 MaterialName "Mch.MCU.MTSI.MaterialName";
BA_ "VssSig" SG_ 2566913569 TrkName "Mch.MCU.MTSI.TrkName";
BA_ "VssSig" SG_ 2566913825 TotAcmtWgh "Mch.MCU.MAWI.TotAcmtWgh";
BA_ "VssSig" SG_ 2566913825 TotAcmtBckCnt "Mch.MCU.MAWI.TotAcmtBckCnt";
BA_ "VssSig" SG_ 2583646241 TrvlLhSpoolCmd "Mch.MCU.FPSSC.TrvlLhSpoolCmd";
BA_ "VssSig" SG_ 2583646241 ArmConfSpoolCmd "Mch.MCU.FPSSC.ArmConfSpoolCmd";
BA_ "VssSig" SG_ 2583646241 BckSpoolCmd "Mch.MCU.FPSSC.BckSpoolCmd";
BA_ "VssSig" SG_ 2583646241 BoomSpoolCmd "Mch.MCU.FPSSC.BoomSpoolCmd";
BA_ "VssSig" SG_ 2583646497 TrvlrightSpoolCmd "Mch.MCU.RPSSC.TrvlrightSpoolCmd";
BA_ "VssSig" SG_ 2583646497 BoomConfSpoolCmd "Mch.MCU.RPSSC.BoomConfSpoolCmd";
BA_ "VssSig" SG_ 2583646497 SwgSpoolCmd "Mch.MCU.RPSSC.SwgSpoolCmd";
BA_ "VssSig" SG_ 2583646497 ArmSpoolCmd "Mch.MCU.RPSSC.ArmSpoolCmd";
BA_ "VssSig" SG_ 2583646753 ArtiBoomConfSpoolCmd "Mch.MCU.OSSC.ArtiBoomConfSpoolCmd";
BA_ "VssSig" SG_ 2583646753 DzSpoolCmd "Mch.MCU.OSSC.DzSpoolCmd";
BA_ "VssSig" SG_ 2583646753 OptSpoolCmd "Mch.MCU.OSSC.OptSpoolCmd";
BA_ "VssSig" SG_ 2583651424 TrvlleftSplDlyCmd "Mch.MCU2.FPDSSC.TrvlleftSplDlyCmd";
BA_ "VssSig" SG_ 2583651424 BckSplDlyCmd "Mch.MCU2.FPDSSC.BckSplDlyCmd";
BA_ "VssSig" SG_ 2583651424 ArmCnfSplDlyCmd "Mch.MCU2.FPDSSC.ArmCnfSplDlyCmd";
BA_ "VssSig" SG_ 2583651424 BoomSplDlyCmd "Mch.MCU2.FPDSSC.BoomSplDlyCmd";
BA_ "VssSig" SG_ 2583651680 TrvlrightSplDlyCmd "Mch.MCU2.RPDSSC.TrvlrightSplDlyCmd";
BA_ "VssSig" SG_ 2583651680 SwgSplDlyCmd "Mch.MCU2.RPDSSC.SwgSplDlyCmd";
BA_ "VssSig" SG_ 2583651680 BoomCnfSplDlyCmd "Mch.MCU2.RPDSSC.BoomCnfSplDlyCmd";
BA_ "VssSig" SG_ 2583651680 ArmSplDlyCmd "Mch.MCU2.RPDSSC.ArmSplDlyCmd";
BA_ "VssSig" SG_ 2583651936 ArtiboomSplDlyCmd "Mch.MCU2.ODSSC.ArtiboomSplDlyCmd";
BA_ "VssSig" SG_ 2583651936 DzSplDlyCmd "Mch.MCU2.ODSSC.DzSplDlyCmd";
BA_ "VssSig" SG_ 2583651936 OptSplDlyCmd "Mch.MCU2.ODSSC.OptSplDlyCmd";
BA_ "VssSig" SG_ 2583654752 BckdumpEpprFdbkCur "Mch.MCU2.BBEFC.BckdumpEpprFdbkCur";
BA_ "VssSig" SG_ 2583654752 BckcrowdEpprFdbkCur "Mch.MCU2.BBEFC.BckcrowdEpprFdbkCur";
BA_ "VssSig" SG_ 2583654752 BoomDnEpprFdbkCur "Mch.MCU2.BBEFC.BoomDnEpprFdbkCur";
BA_ "VssSig" SG_ 2583654752 BoomupEpprFdbkCur "Mch.MCU2.BBEFC.BoomupEpprFdbkCur";
BA_ "VssSig" SG_ 2583655008 SwgREpprFdbkCur "Mch.MCU2.ASEFC.SwgREpprFdbkCur";
BA_ "VssSig" SG_ 2583655008 SwgLEpprFdbkCur "Mch.MCU2.ASEFC.SwgLEpprFdbkCur";
BA_ "VssSig" SG_ 2583655008 ArmdumpEpprFdbkCur "Mch.MCU2.ASEFC.ArmdumpEpprFdbkCur";
BA_ "VssSig" SG_ 2583655008 ArmcrowdEpprFdbkCur "Mch.MCU2.ASEFC.ArmcrowdEpprFdbkCur";
BA_ "VssSig" SG_ 2583655264 ArmCnfdumpEpprFdbkCur "Mch.MCU2.CEFC.ArmCnfdumpEpprFdbkCur";
BA_ "VssSig" SG_ 2583655264 ArmCnfcrowdEpprFdbkCur "Mch.MCU2.CEFC.ArmCnfcrowdEpprFdbkCur";
BA_ "VssSig" SG_ 2583655264 BoomCnfEpprFdbkCur "Mch.MCU2.CEFC.BoomCnfEpprFdbkCur";
BA_ "VssSig" SG_ 2583655520 OpenEpprFdbkCur "Mch.MCU2.OEFC.OpenEpprFdbkCur";
BA_ "VssSig" SG_ 2583655520 CloseEpprFdbkCur "Mch.MCU2.OEFC.CloseEpprFdbkCur";
BA_ "VssSig" SG_ 2583655776 TrvlRBwdEpprFdbkCur "Mch.MCU2.TEFC.TrvlRBwdEpprFdbkCur";
BA_ "VssSig" SG_ 2583655776 TrvlRFwdEpprFdbkCur "Mch.MCU2.TEFC.TrvlRFwdEpprFdbkCur";
BA_ "VssSig" SG_ 2583655776 TrvlLBwdEpprFdbkCur "Mch.MCU2.TEFC.TrvlLBwdEpprFdbkCur";
BA_ "VssSig" SG_ 2583655776 TrvlLFwdEpprFdbkCur "Mch.MCU2.TEFC.TrvlLFwdEpprFdbkCur";
BA_ "VssSig" SG_ 2583656032 BckCylrodPrs "Mch.MCU2.BBHRP.BckCylrodPrs";
BA_ "VssSig" SG_ 2583656032 BckCylheadPrs "Mch.MCU2.BBHRP.BckCylheadPrs";
BA_ "VssSig" SG_ 2583656032 BoomCylrodPrs "Mch.MCU2.BBHRP.BoomCylrodPrs";
BA_ "VssSig" SG_ 2583656032 BoomCylheadPrs "Mch.MCU2.BBHRP.BoomCylheadPrs";
BA_ "VssSig" SG_ 2583656288 ArmCylrodPrs "Mch.MCU2.AHRP.ArmCylrodPrs";
BA_ "VssSig" SG_ 2583656288 ArmCylheadPrs "Mch.MCU2.AHRP.ArmCylheadPrs";
BA_ "VssSig" SG_ 2583656544 BckCylrodPrsSsFmi "Mch.MCU2.CPSF.BckCylrodPrsSsFmi";
BA_ "VssSig" SG_ 2583656544 BckCylheadPrsSsFmi "Mch.MCU2.CPSF.BckCylheadPrsSsFmi";
BA_ "VssSig" SG_ 2583656544 ArmCylrodPrsSsFmi "Mch.MCU2.CPSF.ArmCylrodPrsSsFmi";
BA_ "VssSig" SG_ 2583656544 ArmCylheadPrsSsFmi "Mch.MCU2.CPSF.ArmCylheadPrsSsFmi";
BA_ "VssSig" SG_ 2583656544 BoomCylrodPrsSsFmi "Mch.MCU2.CPSF.BoomCylrodPrsSsFmi";
BA_ "VssSig" SG_ 2583656544 BoomCylheadPrsSsFmi "Mch.MCU2.CPSF.BoomCylheadPrsSsFmi";
BA_ "VssSig" SG_ 2583656800 PtPltPrs "Mch.MCU2.VPP.PtPltPrs";
BA_ "VssSig" SG_ 2583656800 PaPltPrs "Mch.MCU2.VPP.PaPltPrs";
BA_ "VssSig" SG_ 2583656800 BckcrowdEpprPltPrs "Mch.MCU2.VPP.BckcrowdEpprPltPrs";
BA_ "VssSig" SG_ 2583656800 ArmcrowdEpprPltPrs "Mch.MCU2.VPP.ArmcrowdEpprPltPrs";
BA_ "VssSig" SG_ 2583656800 BoomDnEpprPltPrs "Mch.MCU2.VPP.BoomDnEpprPltPrs";
BA_ "VssSig" SG_ 2583657056 PtPltPrsSsFmi "Mch.MCU2.VPPSF.PtPltPrsSsFmi";
BA_ "VssSig" SG_ 2583657056 PaPltPrsSsFmi "Mch.MCU2.VPPSF.PaPltPrsSsFmi";
BA_ "VssSig" SG_ 2583657056 BckcrowdEpprPltPrsSsFmi "Mch.MCU2.VPPSF.BckcrowdEpprPltPrsSsFmi";
BA_ "VssSig" SG_ 2583657056 ArmcrowdEpprPltPrsSsFmi "Mch.MCU2.VPPSF.ArmcrowdEpprPltPrsSsFmi";
BA_ "VssSig" SG_ 2583657056 BoomDnEpprPltPrsSsFmi "Mch.MCU2.VPPSF.BoomDnEpprPltPrsSsFmi";
BA_ "VssSig" SG_ 2583657312 PltCutoffsolVvFmi "Mch.MCU2.PCS.PltCutoffsolVvFmi";
BA_ "VssSig" SG_ 2583657312 PltCutoffsolVvCmd "Mch.MCU2.PCS.PltCutoffsolVvCmd";
BA_ "VssSig" SG_ 2583657312 PltCutoffsolVvswst "Mch.MCU2.PCS.PltCutoffsolVvswst";
BA_ "VssSig" SG_ 2583685153 RefPowShftEnb "Mch.MCU.VTRQD.RefPowShftEnb";
BA_ "VssSig" SG_ 2583685153 PmpActTrq "Mch.MCU.VTRQD.PmpActTrq";
BA_ "VssSig" SG_ 2583685153 PmpCmdTrq "Mch.MCU.VTRQD.PmpCmdTrq";
BA_ "VssSig" SG_ 2583685153 TrqCmdLever "Mch.MCU.VTRQD.TrqCmdLever";
BA_ "VssSig" SG_ 2583685153 TrqCmdLmt "Mch.MCU.VTRQD.TrqCmdLmt";
BA_ "VssSig" SG_ 2583685153 PidCtrlResult "Mch.MCU.VTRQD.PidCtrlResult";
BA_ "VssSig" SG_ 2583685153 TrqCmdTrqCtrl "Mch.MCU.VTRQD.TrqCmdTrqCtrl";
BA_ "VssSig" SG_ 2583685153 TrqCmdPowShftCtrl "Mch.MCU.VTRQD.TrqCmdPowShftCtrl";
BA_ "VssSig" SG_ 2583685409 Bypass2SpoolEpprFdbkCur "Mch.MCU.VSFC.Bypass2SpoolEpprFdbkCur";
BA_ "VssSig" SG_ 2583685409 Bypass1SpoolEpprFdbkCur "Mch.MCU.VSFC.Bypass1SpoolEpprFdbkCur";
BA_ "VssSig" SG_ 2583685409 Boom2SpoolEpprFdbkCur "Mch.MCU.VSFC.Boom2SpoolEpprFdbkCur";
BA_ "VssSig" SG_ 2583685409 Bck2SpoolEpprFdbkCur "Mch.MCU.VSFC.Bck2SpoolEpprFdbkCur";
BA_ "VssSig" SG_ 2583685409 Arm2SpoolEpprFdbkCur "Mch.MCU.VSFC.Arm2SpoolEpprFdbkCur";
BA_ "VssSig" SG_ 2583685409 ArmLckSpoolEpprFdbkCur "Mch.MCU.VSFC.ArmLckSpoolEpprFdbkCur";
BA_ "VssSig" SG_ 2583685665 BoomConfSpoolPilotPrs "Mch.MCU.VSPP.BoomConfSpoolPilotPrs";
BA_ "VssSig" SG_ 2583685665 BckConfSpoolPilotPrs "Mch.MCU.VSPP.BckConfSpoolPilotPrs";
BA_ "VssSig" SG_ 2583685665 ArmConfSpoolPilotPrs "Mch.MCU.VSPP.ArmConfSpoolPilotPrs";
BA_ "VssSig" SG_ 2583685665 ArmLckSpoolPilotPrs "Mch.MCU.VSPP.ArmLckSpoolPilotPrs";
BA_ "VssSig" SG_ 2583685921 ReaRpmpEpprFdbkCur "Mch.MCU.VPAD.ReaRpmpEpprFdbkCur";
BA_ "VssSig" SG_ 2583685921 FrPmpEpprFdbkCur "Mch.MCU.VPAD.FrPmpEpprFdbkCur";
BA_ "VssSig" SG_ 2583685921 FrPmpAngVlt "Mch.MCU.VPAD.FrPmpAngVlt";
BA_ "VssSig" SG_ 2583685921 ReaRpmpAngVlt "Mch.MCU.VPAD.ReaRpmpAngVlt";
BA_ "VssSig" SG_ 2583686177 FrPmpAngVlt "Mch.MCU.VTD.FrPmpAngVlt";
BA_ "VssSig" SG_ 2583686177 OilFanEpprFdbkCur "Mch.MCU.VTD.OilFanEpprFdbkCur";
BA_ "VssSig" SG_ 2583686433 Pmp2flowandCmdDev "Mch.MCU.VVQD.Pmp2flowandCmdDev";
BA_ "VssSig" SG_ 2583686433 Pmp1flowandCmdDev "Mch.MCU.VVQD.Pmp1flowandCmdDev";
BA_ "VssSig" SG_ 2583686433 Pmp2VirQa "Mch.MCU.VVQD.Pmp2VirQa";
BA_ "VssSig" SG_ 2583686433 Pmp1VirQa "Mch.MCU.VVQD.Pmp1VirQa";
BA_ "VssSig" SG_ 2566842442 Pitch "Mch.TGU.VDS.Pitch";
BA_ "VssSig" SG_ 2566842442 Spd "Mch.TGU.VDS.Spd";
BA_ "VssSig" SG_ 2583642954 Dkey "Mch.TGU.DKLLG.Dkey";
BA_ "VssSig" SG_ 2583642954 SelType "Mch.TGU.DKLLG.SelType";
BA_ "VssSig" SG_ 2583643210 DkeyList "Mch.TGU.DKLUG.DkeyList";
BA_ "VssSig" SG_ 2583642442 MpSt "Mch.TGU.MPI.MpSt";
BA_ "VssSig" SG_ 2583642442 TguId "Mch.TGU.MPI.TguId";
BA_ "VssSig" SG_ 2583642442 Sname "Mch.TGU.MPI.Sname";
BA_ "VssSig" SG_ 2583642442 Pname "Mch.TGU.MPI.Pname";
BA_ "VssSig" SG_ 2583642442 Vin "Mch.TGU.MPI.Vin";
BA_ "VssSig" SG_ 2583642442 MchType "Mch.TGU.MPI.MchType";
BA_ "VssSig" SG_ 2583642442 Oem "Mch.TGU.MPI.Oem";
BA_ "VssSig" SG_ 2583642442 Mch "Mch.TGU.MPI.Mch";
BA_ "VssSig" SG_ 2583642698 NetNm "Mch.TGU.TCNI.NetNm";
BA_ "VssSig" SG_ 2583642698 Rssi "Mch.TGU.TCNI.Rssi";
BA_ "VssSig" SG_ 2583642698 Type "Mch.TGU.TCNI.Type";
BA_ "VssSig" SG_ 2583642698 Con "Mch.TGU.TCNI.Con";
BA_ "VssSig" SG_ 2583642401 MpSt "Mch.MCU.MPI.MpSt";
BA_ "VssSig" SG_ 2583642401 TguId "Mch.MCU.MPI.TguId";
BA_ "VssSig" SG_ 2583642401 Sname "Mch.MCU.MPI.Sname";
BA_ "VssSig" SG_ 2583642401 Pname "Mch.MCU.MPI.Pname";
BA_ "VssSig" SG_ 2583642401 Vin "Mch.MCU.MPI.Vin";
BA_ "VssSig" SG_ 2583642401 MchType "Mch.MCU.MPI.MchType";
BA_ "VssSig" SG_ 2583642401 Oem "Mch.MCU.MPI.Oem";
BA_ "VssSig" SG_ 2583642401 Mch "Mch.MCU.MPI.Mch";
BA_ "VssSig" SG_ 2583662698 WarnPopEgOilQual "Mch.TGU.PHMWG.WarnPopEgOilQual";
BA_ "VssSig" SG_ 2583662698 WarnPopHyhOilQual "Mch.TGU.PHMWG.WarnPopHyhOilQual";
BA_ "VssSig" SG_ 2583666538 LwThKnmtVcstyofHyhOil "Mch.TGU.THO.LwThKnmtVcstyofHyhOil";
BA_ "VssSig" SG_ 2583666538 UpThKnmtVcstyofHyhOil "Mch.TGU.THO.UpThKnmtVcstyofHyhOil";
BA_ "VssSig" SG_ 2583666538 LwThDielecCstofHyhOil "Mch.TGU.THO.LwThDielecCstofHyhOil";
BA_ "VssSig" SG_ 2583666538 UpThDielecCstofHyhOil "Mch.TGU.THO.UpThDielecCstofHyhOil";
BA_ "VssSig" SG_ 2583666794 LwThKnmtVcstyofEgOil "Mch.TGU.TEO.LwThKnmtVcstyofEgOil";
BA_ "VssSig" SG_ 2583666794 UpThKnmtVcstyofEgOil "Mch.TGU.TEO.UpThKnmtVcstyofEgOil";
BA_ "VssSig" SG_ 2583666794 LwThDielecCstofEgOil "Mch.TGU.TEO.LwThDielecCstofEgOil";
BA_ "VssSig" SG_ 2583666794 UpThDielecCstofEgOil "Mch.TGU.TEO.UpThDielecCstofEgOil";
BA_ "VssSig" SG_ 2583667050 KnmtVcstyofEgOil "Mch.TGU.KVO.KnmtVcstyofEgOil";
BA_ "VssSig" SG_ 2583667050 KnmtVcstyofHyhOil "Mch.TGU.KVO.KnmtVcstyofHyhOil";
BA_ "VssSig" SG_ 2583662881 AccPdlVlt "Mch.MCU.ECDP1.AccPdlVlt";
BA_ "VssSig" SG_ 2583662881 CtlEgCtrlDialVlt "Mch.MCU.ECDP1.CtlEgCtrlDialVlt";
BA_ "VssSig" SG_ 2583662881 FlwCtrlLeverRh "Mch.MCU.ECDP1.FlwCtrlLeverRh";
BA_ "VssSig" SG_ 2583662881 FlwCtrlLeverLh "Mch.MCU.ECDP1.FlwCtrlLeverLh";
BA_ "VssSig" SG_ 2583663137 WifSsVlt "Mch.MCU.ECDP2.WifSsVlt";
BA_ "VssSig" SG_ 2583663137 VhcTrvlSpdSsFreq "Mch.MCU.ECDP2.VhcTrvlSpdSsFreq";
BA_ "VssSig" SG_ 2583663137 AltVlt "Mch.MCU.ECDP2.AltVlt";
BA_ "VssSig" SG_ 2583663137 BatVlt "Mch.MCU.ECDP2.BatVlt";
BA_ "VssSig" SG_ 2583663393 BckdumpEpprFdbkCur "Mch.MCU.ECDP3.BckdumpEpprFdbkCur";
BA_ "VssSig" SG_ 2583663393 BckcrowdEpprFdbkCur "Mch.MCU.ECDP3.BckcrowdEpprFdbkCur";
BA_ "VssSig" SG_ 2583663393 BoomDnEpprFdbkCur "Mch.MCU.ECDP3.BoomDnEpprFdbkCur";
BA_ "VssSig" SG_ 2583663393 BoomupEpprFdbkCur "Mch.MCU.ECDP3.BoomupEpprFdbkCur";
BA_ "VssSig" SG_ 2583663649 SwgREpprFdbkCur "Mch.MCU.ECDP4.SwgREpprFdbkCur";
BA_ "VssSig" SG_ 2583663649 SwgLEpprFdbkCur "Mch.MCU.ECDP4.SwgLEpprFdbkCur";
BA_ "VssSig" SG_ 2583663649 ArmdumpEpprFdbkCur "Mch.MCU.ECDP4.ArmdumpEpprFdbkCur";
BA_ "VssSig" SG_ 2583663649 ArmcrowdEpprFdbkCur "Mch.MCU.ECDP4.ArmcrowdEpprFdbkCur";
BA_ "VssSig" SG_ 2583663905 ArmCnfdumpEpprFdbkCur "Mch.MCU.ECDP5.ArmCnfdumpEpprFdbkCur";
BA_ "VssSig" SG_ 2583663905 ArmCnfcrowdEpprFdbkCur "Mch.MCU.ECDP5.ArmCnfcrowdEpprFdbkCur";
BA_ "VssSig" SG_ 2583663905 BoomCnfEpprFdbkCur "Mch.MCU.ECDP5.BoomCnfEpprFdbkCur";
BA_ "VssSig" SG_ 2583664161 TrvlRBwdEpprFdbkCur "Mch.MCU.ECDP6.TrvlRBwdEpprFdbkCur";
BA_ "VssSig" SG_ 2583664161 TrvlRFwdEpprFdbkCur "Mch.MCU.ECDP6.TrvlRFwdEpprFdbkCur";
BA_ "VssSig" SG_ 2583664161 TrvlLBwdEpprFdbkCur "Mch.MCU.ECDP6.TrvlLBwdEpprFdbkCur";
BA_ "VssSig" SG_ 2583664161 TrvlLFwdEpprFdbkCur "Mch.MCU.ECDP6.TrvlLFwdEpprFdbkCur";
BA_ "VssSig" SG_ 2583664417 BckCylrodPrs "Mch.MCU.ECDP7.BckCylrodPrs";
BA_ "VssSig" SG_ 2583664417 BckCylheadPrs "Mch.MCU.ECDP7.BckCylheadPrs";
BA_ "VssSig" SG_ 2583664417 BoomCylrodPrs "Mch.MCU.ECDP7.BoomCylrodPrs";
BA_ "VssSig" SG_ 2583664417 BoomCylheadPrs "Mch.MCU.ECDP7.BoomCylheadPrs";
BA_ "VssSig" SG_ 2583664673 ArmCylrodPrs "Mch.MCU.ECDP8.ArmCylrodPrs";
BA_ "VssSig" SG_ 2583664673 ArmCylheadPrs "Mch.MCU.ECDP8.ArmCylheadPrs";
BA_ "VssSig" SG_ 2583664673 OpenEpprFdbkCur "Mch.MCU.ECDP8.OpenEpprFdbkCur";
BA_ "VssSig" SG_ 2583664673 CloseEpprFdbkCur "Mch.MCU.ECDP8.CloseEpprFdbkCur";
BA_ "VssSig" SG_ 2583664929 TrvlRStrkPltPrs "Mch.MCU.ECDP9.TrvlRStrkPltPrs";
BA_ "VssSig" SG_ 2583664929 TrvlLStrkPltPrs "Mch.MCU.ECDP9.TrvlLStrkPltPrs";
BA_ "VssSig" SG_ 2583664929 PtPltPrs "Mch.MCU.ECDP9.PtPltPrs";
BA_ "VssSig" SG_ 2583664929 PaPltPrs "Mch.MCU.ECDP9.PaPltPrs";
BA_ "VssSig" SG_ 2583664929 BckcrowdEpprPltPrs "Mch.MCU.ECDP9.BckcrowdEpprPltPrs";
BA_ "VssSig" SG_ 2583664929 ArmcrowdEpprPltPrs "Mch.MCU.ECDP9.ArmcrowdEpprPltPrs";
BA_ "VssSig" SG_ 2583664929 BoomDnEpprPltPrs "Mch.MCU.ECDP9.BoomDnEpprPltPrs";
BA_ "VssSig" SG_ 2583665185 Pmp2ActFlw "Mch.MCU.ECDP10.Pmp2ActFlw";
BA_ "VssSig" SG_ 2583665185 Pmp1ActFlw "Mch.MCU.ECDP10.Pmp1ActFlw";
BA_ "VssSig" SG_ 2583665185 Pmp2FlwCmd "Mch.MCU.ECDP10.Pmp2FlwCmd";
BA_ "VssSig" SG_ 2583665185 Pmp1FlwCmd "Mch.MCU.ECDP10.Pmp1FlwCmd";
BA_ "VssSig" SG_ 2583665185 Pmp2ReqrFlw "Mch.MCU.ECDP10.Pmp2ReqrFlw";
BA_ "VssSig" SG_ 2583665185 Pmp1ReqrFlw "Mch.MCU.ECDP10.Pmp1ReqrFlw";
BA_ "VssSig" SG_ 2583665441 SwgStrkPltPrs "Mch.MCU.ECDP11.SwgStrkPltPrs";
BA_ "VssSig" SG_ 2583665441 ArmdumpStrkPltPrs "Mch.MCU.ECDP11.ArmdumpStrkPltPrs";
BA_ "VssSig" SG_ 2583665441 ArmcrowdStrkPltPrs "Mch.MCU.ECDP11.ArmcrowdStrkPltPrs";
BA_ "VssSig" SG_ 2583665441 BckdumpStrkPltPrs "Mch.MCU.ECDP11.BckdumpStrkPltPrs";
BA_ "VssSig" SG_ 2583665441 BckcrowdStrkPltPrs "Mch.MCU.ECDP11.BckcrowdStrkPltPrs";
BA_ "VssSig" SG_ 2583665441 BoomDnStrkPltPrs "Mch.MCU.ECDP11.BoomDnStrkPltPrs";
BA_ "VssSig" SG_ 2583665441 BoomupStrkPltPrs "Mch.MCU.ECDP11.BoomupStrkPltPrs";
BA_ "VssSig" SG_ 2583665697 Bypass2SpoolEpprFdbkCur "Mch.MCU.ECDP12.Bypass2SpoolEpprFdbkCur";
BA_ "VssSig" SG_ 2583665697 Bypass1SpoolEpprFdbkCur "Mch.MCU.ECDP12.Bypass1SpoolEpprFdbkCur";
BA_ "VssSig" SG_ 2583665697 Boom2SpoolEpprFdbkCur "Mch.MCU.ECDP12.Boom2SpoolEpprFdbkCur";
BA_ "VssSig" SG_ 2583665697 Bck2SpoolEpprFdbkCur "Mch.MCU.ECDP12.Bck2SpoolEpprFdbkCur";
BA_ "VssSig" SG_ 2583665697 Arm2SpoolEpprFdbkCur "Mch.MCU.ECDP12.Arm2SpoolEpprFdbkCur";
BA_ "VssSig" SG_ 2583665697 ArmLckSpoolEpprFdbkCur "Mch.MCU.ECDP12.ArmLckSpoolEpprFdbkCur";
BA_ "VssSig" SG_ 2583665953 BoomConfSpoolPilotPrs "Mch.MCU.ECDP13.BoomConfSpoolPilotPrs";
BA_ "VssSig" SG_ 2583665953 BckConfSpoolPilotPrs "Mch.MCU.ECDP13.BckConfSpoolPilotPrs";
BA_ "VssSig" SG_ 2583665953 ArmConfSpoolPilotPrs "Mch.MCU.ECDP13.ArmConfSpoolPilotPrs";
BA_ "VssSig" SG_ 2583665953 ArmLckSpoolPilotPrs "Mch.MCU.ECDP13.ArmLckSpoolPilotPrs";
BA_ "VssSig" SG_ 2583666209 Pmp2FinPrsCmd "Mch.MCU.ECDP14.Pmp2FinPrsCmd";
BA_ "VssSig" SG_ 2583666209 Pmp1FinPrsCmd "Mch.MCU.ECDP14.Pmp1FinPrsCmd";
BA_ "VssSig" SG_ 2583666209 RrPmpPrs "Mch.MCU.ECDP14.RrPmpPrs";
BA_ "VssSig" SG_ 2583666209 FrPmpPrs "Mch.MCU.ECDP14.FrPmpPrs";
BA_ "VssSig" SG_ 2633656127 Oilresistivity "Mch.HDOQS.OQM2.Oilresistivity";
BA_ "VssSig" SG_ 2633656238 Oilresistivity "Mch.EGOQS.OQM2.Oilresistivity";
VAL_ 2566904865 SalesRegion 0 "Korea" 1 "China" 2 "Advanced" 3 "Emerging" 4 "US" ;
VAL_ 2566904865 TcuType 0 "HDT" 1 "HST" 2 "CVT" 3 "HDT Level1" ;
VAL_ 2566904865 JoyType 0 "Hydraulic" 1 "Electronic" ;
VAL_ 2566904865 McvCtrlType 0 "Mechanic" 1 "VBO" 2 "FEH" ;
VAL_ 2566904865 McvType 0 "Mechanic" 1 "Electric" ;
VAL_ 2566904865 PmpCtrlType 0 "Mechanic" 1 "Electric" ;
VAL_ 2566904865 PmpType 0 "Negacon" 1 "Posicon" 2 "Open Center" 3 "VBO" 4 "LS" ;
VAL_ 2566904865 EcuMaker 0 "None" 1 "Bosch (DL06 / DL08)" 2 "Scania" 3 "Cummins" 4 "Perkins_2506J" 5 "Isuzu" 6 "Bosch (G2)" 7 "Hitachi" 8 "Perkins_1204J" 9 "Woodward" 10 "Bosch (EDC7)" 11 "Weifu" 12 "Perkins_2506J_Unified" ;
VAL_ 2566904865 EgMaker 0 "None" 1 "Doosan" 2 "Scania" 3 "Cummins" 4 "Perkins" 5 "Isuzu" 7 "Yanmar" 8 "Daedong" ;
VAL_ 2566904865 ModelYearVer 0 "Original" 1 "1st" 2 "2nd" 3 "3rd" 4 "4th" 5 "5th" ;
VAL_ 2566904865 MchType 0 "Crawler" 1 "Long Crawler" 2 "LogLoader" 3 "Reduced Tail" 4 "Zero Tail" 5 "Mountain" 6 "Wheel" 7 "Loader" 8 "Dozer" 9 "Material Handler" 10 "Material Handler Wheel" 11 "Drill Rig" 12 "Compact Track Loader" 13 "Road Builder" 14 "ADT" ;
VAL_ 2566904865 MchGen 0 "DX" 1 "U" 2 "V" 3 "C" 4 "B" 5 "W" 96 "JD" 108 "AGK" 128 "DL" 129 "H" 130 "K" 131 "S" 132 "SD" 133 "G" 224 "D" ;
VAL_ 2566904865 EmsCtrl 0 "Tier2" 1 "Tier3" 2 "Tier4i" 3 "Tier4F" 4 "StageV" 5 "NR4" 128 "N/A" ;
VAL_ 2566905121 Tw4BrkrBtnType 0 "Push" 1 "Toggle" 2 "Propotional" 3 "N/A" ;
VAL_ 2566905121 Tw3BrkrBtnType 0 "Push" 1 "Toggle" 2 "Propotional" 3 "N/A" ;
VAL_ 2566905121 Tw2BrkrBtnType 0 "Push" 1 "Toggle" 2 "Propotional" 3 "N/A" ;
VAL_ 2566905121 Tw1BrkrBtnType 0 "Push" 1 "Toggle" 2 "Propotional" 3 "N/A" ;
VAL_ 2566905121 Tw0BrkrBtnType 0 "Push" 1 "Toggle" 2 "Propotional" 3 "N/A" ;
VAL_ 2566905121 Ow4BrkrBtnType 0 "Push" 1 "Toggle" 2 "Propotional" 3 "N/A" ;
VAL_ 2566905121 Ow3BrkrBtnType 0 "Push" 1 "Toggle" 2 "Propotional" 3 "N/A" ;
VAL_ 2566905121 Ow2BrkrBtnType 0 "Push" 1 "Toggle" 2 "Propotional" 3 "N/A" ;
VAL_ 2566905121 Ow1BrkrBtnType 0 "Push" 1 "Toggle" 2 "Propotional" 3 "N/A" ;
VAL_ 2566905121 Ow0BrkrBtnType 0 "Push" 1 "Toggle" 2 "Propotional" 3 "N/A" ;
VAL_ 2566905377 TrvlStd 0 "False" 1 "True" 2 "Error" 3 "N/A" ;
VAL_ 2566905377 TrvlPow 0 "False" 1 "True" 2 "Error" 3 "N/A" ;
VAL_ 2566905377 Idle 0 "False" 1 "True" 2 "Error" 3 "N/A" ;
VAL_ 2566905377 AutoIdle 0 "False" 1 "True" 2 "Error" 3 "N/A" ;
VAL_ 2566905377 EcnMd 0 "False" 1 "True" 2 "Error" 3 "N/A" ;
VAL_ 2566905377 StdMd 0 "False" 1 "True" 2 "Error" 3 "N/A" ;
VAL_ 2566905377 PowMd 0 "False" 1 "True" 2 "Error" 3 "N/A" ;
VAL_ 2566905377 PowPlusMd 0 "False" 1 "True" 2 "Error" 3 "N/A" ;
VAL_ 2566907681 IccoFunCrctm 0 "False" 1 "True" 2 "Error" 3 "N/A" ;
VAL_ 2566907681 EgMdDnRctm 0 "False" 1 "True" 2 "Error" 3 "N/A" ;
VAL_ 2566907681 LckUpRcmd 0 "False" 1 "True" 2 "Error" 3 "N/A" ;
VAL_ 2566907681 IdlePrvtRcmd 0 "False" 1 "True" 2 "Error" 3 "N/A" ;
VAL_ 2566907681 Auto14Rcmd 0 "False" 1 "True" 2 "Error" 3 "N/A" ;
VAL_ 2566907681 LisRcmd 0 "False" 1 "True" 2 "Error" 3 "N/A" ;
VAL_ 2566907937 ElecStrJoyThmbWhlConf 0 "Deactive" 1 "Active" 2 "Error" 3 "N/A" ;
VAL_ 2566907937 Dl06EgFuelEffCalbConf 0 "Deactive" 1 "Active" 2 "Error" 3 "N/A" ;
VAL_ 2566907937 RttThmbWhlDirConf 0 "Deactive" 1 "Active" 2 "Error" 3 "N/A" ;
VAL_ 2566907937 TwThmbWhlDirConf 0 "Deactive" 1 "Active" 2 "Error" 3 "N/A" ;
VAL_ 2566907937 CanPdlIntChngConf 0 "Deactive" 1 "Active" 2 "Error" 3 "N/A" ;
VAL_ 2566907937 TrvlSwgAlmIntChngConf 0 "Deactive" 1 "Active" 2 "Error" 3 "N/A" ;
VAL_ 2566907937 OprHrTmpIntChngConf 0 "Deactive" 1 "Active" 2 "Error" 3 "N/A" ;
VAL_ 2566907937 QckCouplerIntChngConf 0 "Deactive" 1 "Active" 2 "Error" 3 "N/A" ;
VAL_ 2566907937 ThmbWhlSensConf 0 "Deactive" 1 "Active" 2 "Error" 3 "N/A" ;
VAL_ 2566907937 MultiFuncJoyBtnConf 0 "Deactive" 1 "Active" 2 "Error" 3 "N/A" ;
VAL_ 2566908449 AssitSwgRh 0 "Off" 1 "On" 2 "Error" 3 "N/A" ;
VAL_ 2566908449 AssitSwgLh 0 "Off" 1 "On" 2 "Error" 3 "N/A" ;
VAL_ 2566908449 AssitBck 0 "Off" 1 "On" 2 "Error" 3 "N/A" ;
VAL_ 2566908449 AssitGrd 0 "Off" 1 "On" 2 "Error" 3 "N/A" ;
VAL_ 2566908449 SafeWrkSideFar 0 "Off" 1 "On" 2 "Error" 3 "N/A" ;
VAL_ 2566908449 SafeWrkSideMid 0 "Off" 1 "On" 2 "Error" 3 "N/A" ;
VAL_ 2566908449 SafeWrkSideNear 0 "Off" 1 "On" 2 "Error" 3 "N/A" ;
VAL_ 2566908449 SafeWrkFrFar 0 "Off" 1 "On" 2 "Error" 3 "N/A" ;
VAL_ 2566908449 SafeWrkFrMid 0 "Off" 1 "On" 2 "Error" 3 "N/A" ;
VAL_ 2566908449 SafeWrkFrNear 0 "Off" 1 "On" 2 "Error" 3 "N/A" ;
VAL_ 2566908449 FrMvGuidArmOut 0 "Off" 1 "On" 2 "Error" 3 "N/A" ;
VAL_ 2566908449 FrMvGuidArmIn 0 "Off" 1 "On" 2 "Error" 3 "N/A" ;
VAL_ 2566908449 FrMvGuidBoomDn 0 "Off" 1 "On" 2 "Error" 3 "N/A" ;
VAL_ 2566908449 FrMvGuidBoomUp 0 "Green" 1 "Yellow" 2 "Red" ;
VAL_ 2566908449 EfenceTrkWrn 0 "Off" 1 "On" 2 "Error" 3 "N/A" ;
VAL_ 2566908449 EfenceDzWrn 0 "Off" 1 "On" 2 "Error" 3 "N/A" ;
VAL_ 2566908449 EfenceCabWrn 0 "Off" 1 "On" 2 "Error" 3 "N/A" ;
VAL_ 2566908449 EfenceFSwgRhWrn 0 "Off" 1 "On" 2 "Error" 3 "N/A" ;
VAL_ 2566908449 EfenceFSwgLhWrn 0 "Off" 1 "On" 2 "Error" 3 "N/A" ;
VAL_ 2566908449 EfenceCeilWrn 0 "Off" 1 "On" 2 "Error" 3 "N/A" ;
VAL_ 2566908449 EfenceFloorWrn 0 "Off" 1 "On" 2 "Error" 3 "N/A" ;
VAL_ 2566908449 EfenceWallWrn 0 "Off" 1 "On" 2 "Error" 3 "N/A" ;
VAL_ 2566908705 WghCntSt 0 "Off" 1 "Cancel" 2 "Return" 3 "Not Defined" ;
VAL_ 2566908705 WghSt 0 "Ready" 1 "Estimate" 2 "Confirm" 3 "Complete" 4 "Estimate(Truck tip-off)" 5 "Confirm(Truck Tip-off)" ;
VAL_ 2566908961 BckZeroCalbStage 0 "Reserved" 1 "Stage 1" 2 "Stage 2" 3 "Stage 3" 4 "Stage 4" 5 "Stage 5" 6 "Stage 6" 7 "Stage 7" 8 "Stage 8" 9 "Stage 9" 10 "Stage 10" 11 "Stage 11" 12 "Stage 12" 13 "Last Stage (Confirm)" 14 "Success" 15 "Error" ;
VAL_ 2566908961 FrMultiCalbStage 0 "Reserved" 1 "Stage 1" 2 "Stage 2" 3 "Stage 3" 4 "Stage 4" 5 "Stage 5" 6 "Stage 6" 7 "Stage 7" 8 "Stage 8" 9 "Stage 9" 10 "Stage 10" 11 "Stage 11" 12 "Stage 12" 13 "Last Stage (Confirm)" 14 "Success" 15 "Error" ;
VAL_ 2566908961 FrSngCalbStage 0 "Reserved" 1 "Stage 1" 2 "Stage 2" 3 "Stage 3" 4 "Stage 4" 5 "Stage 5" 6 "Stage 6" 7 "Stage 7" 8 "Stage 8" 9 "Stage 9" 10 "Stage 10" 11 "Stage 11" 12 "Stage 12" 13 "Last Stage (Confirm)" 14 "Success" 15 "Error" ;
VAL_ 2566913569 MaterialLoadSt 0 "In Progress" 1 "Complete" ;
VAL_ 2583642954 SelType 0 "None" 1 "Fob" 2 "Digital Key" 3 "Keyless" 4 "Remote" ;
VAL_ 2583642442 MpSt 0 "False" 1 "True" 2 "Error" 3 "N/A" ;
VAL_ 2583642698 Type 0 "2G" 1 "3G" 2 "4G" 3 "5G" 7 "N/A" ;
VAL_ 2583642698 Con 0 "False" 1 "True" 2 "Error" 3 "N/A" ;
VAL_ 2583642401 MpSt 0 "False" 1 "True" 2 "Error" 3 "N/A" ;
VAL_ 2583662698 WarnPopEgOilQual 0 "Off" 1 "?? 1??" 2 "?? 2??" ;
VAL_ 2583662698 WarnPopHyhOilQual 0 "Off" 1 "?? 1??" 2 "?? 2??" ;
